VERSION ""

NS_ :

BS_:

BU_: ETH

BO_ 1274 USM_alertCleared: 8 Vector__XXX
 SG_ USM_alertClearedID : 0|8@1+ (1,0) [0|0] "" Vector__XXX

BO_ 1278 USM_logging10Hz: 8 Vector__XXX
 SG_ USM_frontSensorsHSDCurrent : 0|10@1+ (0.005865102639296188,0) [0|0] "" Vector__XXX
 SG_ USM_rearSensorsHSDCurrent : 10|10@1+ (0.005865102639296188,0) [0|0] "" Vector__XXX

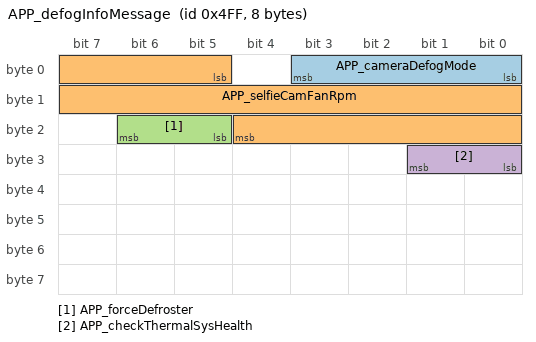
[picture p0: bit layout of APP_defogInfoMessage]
BO_ 1279 APP_defogInfoMessage: 8 Vector__XXX
 SG_ APP_cameraDefogMode : 0|4@1+ (1,0) [0|0] "" Vector__XXX
 SG_ APP_selfieCamFanRpm : 5|16@1+ (1,0) [0|0] "" Vector__XXX
 SG_ APP_forceDefroster : 21|2@1+ (1,0) [0|0] "" Vector__XXX
 SG_ APP_checkThermalSysHealth : 24|2@1+ (1,0) [0|0] "" Vector__XXX

BO_ 1282 RADC_alertMatrix0: 8 Vector__XXX
 SG_ RADC_a001_can1BusOff : 1|1@1+ (1,0) [0|0] "" Vector__XXX
 SG_ RADC_a002_ecuAdcError : 2|1@1+ (1,0) [0|0] "" Vector__XXX
 SG_ RADC_a003_ecuBistDisabled : 3|1@1+ (1,0) [0|0] "" Vector__XXX
 SG_ RADC_a004_ecuCrcHwError : 4|1@1+ (1,0) [0|0] "" Vector__XXX
 SG_ RADC_a005_ecuEcuMError : 5|1@1+ (1,0) [0|0] "" Vector__XXX
 SG_ RADC_a006_ecuFimError : 6|1@1+ (1,0) [0|0] "" Vector__XXX
 SG_ RADC_a007_ecuGptCheckError : 7|1@1+ (1,0) [0|0] "" Vector__XXX
 SG_ RADC_a008_ecuHwSwInterlock : 8|1@1+ (1,0) [0|0] "" Vector__XXX
 SG_ RADC_a009_plantModeActive : 9|1@1+ (1,0) [0|0] "" Vector__XXX
 SG_ RADC_a010_ecuIoHwAbError : 10|1@1+ (1,0) [0|0] "" Vector__XXX
 SG_ RADC_a011_ecuMcemError : 11|1@1+ (1,0) [0|0] "" Vector__XXX
 SG_ RADC_a012_ecuSpiError : 12|1@1+ (1,0) [0|0] "" Vector__XXX
 SG_ RADC_a013_ecuWdgError : 13|1@1+ (1,0) [0|0] "" Vector__XXX
 SG_ RADC_a014_fctSelfTestNotDone : 14|1@1+ (1,0) [0|0] "" Vector__XXX
 SG_ RADC_a015_fctSenInterference : 15|1@1+ (1,0) [0|0] "" Vector__XXX
 SG_ RADC_a016_adcOverVolt : 16|1@1+ (1,0) [0|0] "" Vector__XXX
 SG_ RADC_a017_adcUnderVolt : 17|1@1+ (1,0) [0|0] "" Vector__XXX
 SG_ RADC_a018_internalHardwareFault : 18|1@1+ (1,0) [0|0] "" Vector__XXX
 SG_ RADC_a019_internalSoftwareFault : 19|1@1+ (1,0) [0|0] "" Vector__XXX
 SG_ RADC_a020_overTemp : 20|1@1+ (1,0) [0|0] "" Vector__XXX
 SG_ RADC_a021_overTempCrit : 21|1@1+ (1,0) [0|0] "" Vector__XXX
 SG_ RADC_a022_tempImplausible : 22|1@1+ (1,0) [0|0] "" Vector__XXX
 SG_ RADC_a023_underTemp : 23|1@1+ (1,0) [0|0] "" Vector__XXX
 SG_ RADC_a024_underTempCrit : 24|1@1+ (1,0) [0|0] "" Vector__XXX
 SG_ RADC_a025_overVoltage : 25|1@1+ (1,0) [0|0] "" Vector__XXX
 SG_ RADC_a026_underVoltage : 26|1@1+ (1,0) [0|0] "" Vector__XXX
 SG_ RADC_a027_nvmFailure : 27|1@1+ (1,0) [0|0] "" Vector__XXX
 SG_ RADC_a028_rfChipError : 28|1@1+ (1,0) [0|0] "" Vector__XXX
 SG_ RADC_a029_rhcError : 29|1@1+ (1,0) [0|0] "" Vector__XXX
 SG_ RADC_a030_rspError : 30|1@1+ (1,0) [0|0] "" Vector__XXX
 SG_ RADC_a031_sensorMisaligned : 31|1@1+ (1,0) [0|0] "" Vector__XXX
 SG_ RADC_a032_sensorBlocked : 32|1@1+ (1,0) [0|0] "" Vector__XXX
 SG_ RADC_a033_sensorNeverAligned : 33|1@1+ (1,0) [0|0] "" Vector__XXX
 SG_ RADC_a034_vehDynamicsError : 34|1@1+ (1,0) [0|0] "" Vector__XXX
 SG_ RADC_a035_vinMIA : 35|1@1+ (1,0) [0|0] "" Vector__XXX
 SG_ RADC_a036_carConfigMIA : 36|1@1+ (1,0) [0|0] "" Vector__XXX
 SG_ RADC_a037_inertialSignalsMIA : 37|1@1+ (1,0) [0|0] "" Vector__XXX
 SG_ RADC_a038_steeringWheelAngleMIA : 38|1@1+ (1,0) [0|0] "" Vector__XXX
 SG_ RADC_a039_vehicleStateMIA : 39|1@1+ (1,0) [0|0] "" Vector__XXX
 SG_ RADC_a040_wheelSpeedsMIA : 40|1@1+ (1,0) [0|0] "" Vector__XXX
 SG_ RADC_a041_vinErr : 41|1@1+ (1,0) [0|0] "" Vector__XXX
 SG_ RADC_a042_carConfigErr : 42|1@1+ (1,0) [0|0] "" Vector__XXX
 SG_ RADC_a043_inertialSignalsErr : 43|1@1+ (1,0) [0|0] "" Vector__XXX
 SG_ RADC_a044_steeringWheelAngleErr : 44|1@1+ (1,0) [0|0] "" Vector__XXX
 SG_ RADC_a045_vehicleStateErr : 45|1@1+ (1,0) [0|0] "" Vector__XXX
 SG_ RADC_a046_wheelSpeedsErr : 46|1@1+ (1,0) [0|0] "" Vector__XXX
 SG_ RADC_a047_mismatchChassisType : 47|1@1+ (1,0) [0|0] "" Vector__XXX
 SG_ RADC_a048_mismatchAirSuspension : 48|1@1+ (1,0) [0|0] "" Vector__XXX
 SG_ RADC_a049_mismatchFourWheelDrive : 49|1@1+ (1,0) [0|0] "" Vector__XXX
 SG_ RADC_a050_mismatchCountry : 50|1@1+ (1,0) [0|0] "" Vector__XXX
 SG_ RADC_a051_mismatchEPASType : 51|1@1+ (1,0) [0|0] "" Vector__XXX
 SG_ RADC_a052_mismatcRadPos : 52|1@1+ (1,0) [0|0] "" Vector__XXX
 SG_ RADC_a053_emError : 53|1@1+ (1,0) [0|0] "" Vector__XXX
 SG_ RADC_a054_blockageInfo_Frame_1 : 54|1@1+ (1,0) [0|0] "" Vector__XXX
 SG_ RADC_a055_blockageInfo_Frame_2 : 55|1@1+ (1,0) [0|0] "" Vector__XXX

BO_ 1285 ESP_alertLog: 8 Vector__XXX
 SG_ ESP_alertID : 0|9@1+ (1,0) [0|0] "" Vector__XXX
 SG_ ESP_alertState : 15|1@1+ (1,0) [0|0] "" Vector__XXX

BO_ 1297 RCM_alertLog: 8 Vector__XXX
 SG_ RCM_alertID M : 0|10@1+ (1,0) [0|0] "" Vector__XXX
 SG_ RCM_alertState : 10|1@1+ (1,0) [0|0] "" Vector__XXX
 SG_ RCM_a000_eventArmStatus m0 : 11|1@1+ (1,0) [0|0] "" Vector__XXX
 SG_ RCM_a001_eventArmStatus m1 : 11|1@1+ (1,0) [0|0] "" Vector__XXX
 SG_ RCM_a002_eventArmStatus m2 : 11|1@1+ (1,0) [0|0] "" Vector__XXX
 SG_ RCM_a003_eventArmStatus m3 : 11|1@1+ (1,0) [0|0] "" Vector__XXX
 SG_ RCM_a004_eventArmStatus m4 : 11|1@1+ (1,0) [0|0] "" Vector__XXX
 SG_ RCM_a005_eventArmStatus m5 : 11|1@1+ (1,0) [0|0] "" Vector__XXX
 SG_ RCM_a006_eventArmStatus m6 : 11|1@1+ (1,0) [0|0] "" Vector__XXX
 SG_ RCM_a007_eventArmStatus m7 : 11|1@1+ (1,0) [0|0] "" Vector__XXX
 SG_ RCM_a008_eventArmStatus m8 : 11|1@1+ (1,0) [0|0] "" Vector__XXX
 SG_ RCM_a009_eventArmStatus m9 : 11|1@1+ (1,0) [0|0] "" Vector__XXX
 SG_ RCM_a010_eventArmStatus m10 : 11|1@1+ (1,0) [0|0] "" Vector__XXX
 SG_ RCM_a011_eventArmStatus m11 : 11|1@1+ (1,0) [0|0] "" Vector__XXX
 SG_ RCM_a012_eventArmStatus m12 : 11|1@1+ (1,0) [0|0] "" Vector__XXX
 SG_ RCM_a013_eventArmStatus m13 : 11|1@1+ (1,0) [0|0] "" Vector__XXX
 SG_ RCM_a014_eventArmStatus m14 : 11|1@1+ (1,0) [0|0] "" Vector__XXX
 SG_ RCM_a015_eventArmStatus m15 : 11|1@1+ (1,0) [0|0] "" Vector__XXX
 SG_ RCM_a016_eventArmStatus m16 : 11|1@1+ (1,0) [0|0] "" Vector__XXX
 SG_ RCM_a017_eventArmStatus m17 : 11|1@1+ (1,0) [0|0] "" Vector__XXX
 SG_ RCM_a018_eventArmStatus m18 : 11|1@1+ (1,0) [0|0] "" Vector__XXX
 SG_ RCM_a019_eventArmStatus m19 : 11|1@1+ (1,0) [0|0] "" Vector__XXX
 SG_ RCM_a020_eventArmStatus m20 : 11|1@1+ (1,0) [0|0] "" Vector__XXX
 SG_ RCM_a021_eventArmStatus m21 : 11|1@1+ (1,0) [0|0] "" Vector__XXX
 SG_ RCM_a022_eventArmStatus m22 : 11|1@1+ (1,0) [0|0] "" Vector__XXX
 SG_ RCM_a023_eventArmStatus m23 : 11|1@1+ (1,0) [0|0] "" Vector__XXX
 SG_ RCM_a024_eventArmStatus m24 : 11|1@1+ (1,0) [0|0] "" Vector__XXX
 SG_ RCM_a025_eventArmStatus m25 : 11|1@1+ (1,0) [0|0] "" Vector__XXX
 SG_ RCM_a026_eventArmStatus m26 : 11|1@1+ (1,0) [0|0] "" Vector__XXX
 SG_ RCM_a027_eventArmStatus m27 : 11|1@1+ (1,0) [0|0] "" Vector__XXX
 SG_ RCM_a028_eventArmStatus m28 : 11|1@1+ (1,0) [0|0] "" Vector__XXX
 SG_ RCM_a029_eventArmStatus m29 : 11|1@1+ (1,0) [0|0] "" Vector__XXX
 SG_ RCM_a030_eventArmStatus m30 : 11|1@1+ (1,0) [0|0] "" Vector__XXX
 SG_ RCM_a031_eventArmStatus m31 : 11|1@1+ (1,0) [0|0] "" Vector__XXX
 SG_ RCM_a032_eventArmStatus m32 : 11|1@1+ (1,0) [0|0] "" Vector__XXX
 SG_ RCM_a033_eventArmStatus m33 : 11|1@1+ (1,0) [0|0] "" Vector__XXX
 SG_ RCM_a034_eventArmStatus m34 : 11|1@1+ (1,0) [0|0] "" Vector__XXX
 SG_ RCM_a035_eventArmStatus m35 : 11|1@1+ (1,0) [0|0] "" Vector__XXX
 SG_ RCM_a036_eventArmStatus m36 : 11|1@1+ (1,0) [0|0] "" Vector__XXX
 SG_ RCM_a037_eventArmStatus m37 : 11|1@1+ (1,0) [0|0] "" Vector__XXX
 SG_ RCM_a038_eventArmStatus m38 : 11|1@1+ (1,0) [0|0] "" Vector__XXX
 SG_ RCM_a039_eventArmStatus m39 : 11|1@1+ (1,0) [0|0] "" Vector__XXX
 SG_ RCM_a040_eventArmStatus m40 : 11|1@1+ (1,0) [0|0] "" Vector__XXX
 SG_ RCM_a041_eventArmStatus m41 : 11|1@1+ (1,0) [0|0] "" Vector__XXX
 SG_ RCM_a042_eventArmStatus m42 : 11|1@1+ (1,0) [0|0] "" Vector__XXX
 SG_ RCM_a043_eventArmStatus m43 : 11|1@1+ (1,0) [0|0] "" Vector__XXX
 SG_ RCM_a044_eventArmStatus m44 : 11|1@1+ (1,0) [0|0] "" Vector__XXX
 SG_ RCM_a045_eventArmStatus m45 : 11|1@1+ (1,0) [0|0] "" Vector__XXX
 SG_ RCM_a046_eventArmStatus m46 : 11|1@1+ (1,0) [0|0] "" Vector__XXX
 SG_ RCM_a047_eventArmStatus m47 : 11|1@1+ (1,0) [0|0] "" Vector__XXX
 SG_ RCM_a048_eventArmStatus m48 : 11|1@1+ (1,0) [0|0] "" Vector__XXX
 SG_ RCM_a049_eventArmStatus m49 : 11|1@1+ (1,0) [0|0] "" Vector__XXX
 SG_ RCM_a050_eventArmStatus m50 : 11|1@1+ (1,0) [0|0] "" Vector__XXX
 SG_ RCM_a051_eventArmStatus m51 : 11|1@1+ (1,0) [0|0] "" Vector__XXX
 SG_ RCM_a052_eventArmStatus m52 : 11|1@1+ (1,0) [0|0] "" Vector__XXX
 SG_ RCM_a053_eventArmStatus m53 : 11|1@1+ (1,0) [0|0] "" Vector__XXX
 SG_ RCM_a054_eventArmStatus m54 : 11|1@1+ (1,0) [0|0] "" Vector__XXX
 SG_ RCM_a055_eventArmStatus m55 : 11|1@1+ (1,0) [0|0] "" Vector__XXX
 SG_ RCM_a056_eventArmStatus m56 : 11|1@1+ (1,0) [0|0] "" Vector__XXX
 SG_ RCM_a057_eventArmStatus m57 : 11|1@1+ (1,0) [0|0] "" Vector__XXX
 SG_ RCM_a058_eventArmStatus m58 : 11|1@1+ (1,0) [0|0] "" Vector__XXX
 SG_ RCM_a059_eventArmStatus m59 : 11|1@1+ (1,0) [0|0] "" Vector__XXX
 SG_ RCM_a060_eventArmStatus m60 : 11|1@1+ (1,0) [0|0] "" Vector__XXX
 SG_ RCM_a061_eventArmStatus m61 : 11|1@1+ (1,0) [0|0] "" Vector__XXX
 SG_ RCM_a062_eventArmStatus m62 : 11|1@1+ (1,0) [0|0] "" Vector__XXX
 SG_ RCM_a063_eventArmStatus m63 : 11|1@1+ (1,0) [0|0] "" Vector__XXX
 SG_ RCM_a064_eventArmStatus m64 : 11|1@1+ (1,0) [0|0] "" Vector__XXX
 SG_ RCM_a065_eventArmStatus m65 : 11|1@1+ (1,0) [0|0] "" Vector__XXX
 SG_ RCM_a066_eventArmStatus m66 : 11|1@1+ (1,0) [0|0] "" Vector__XXX
 SG_ RCM_a067_eventArmStatus m67 : 11|1@1+ (1,0) [0|0] "" Vector__XXX
 SG_ RCM_a068_eventArmStatus m68 : 11|1@1+ (1,0) [0|0] "" Vector__XXX
 SG_ RCM_a069_eventArmStatus m69 : 11|1@1+ (1,0) [0|0] "" Vector__XXX
 SG_ RCM_a070_eventArmStatus m70 : 11|1@1+ (1,0) [0|0] "" Vector__XXX
 SG_ RCM_a071_eventArmStatus m71 : 11|1@1+ (1,0) [0|0] "" Vector__XXX
 SG_ RCM_a072_eventArmStatus m72 : 11|1@1+ (1,0) [0|0] "" Vector__XXX
 SG_ RCM_a073_eventArmStatus m73 : 11|1@1+ (1,0) [0|0] "" Vector__XXX
 SG_ RCM_a074_eventArmStatus m74 : 11|1@1+ (1,0) [0|0] "" Vector__XXX
 SG_ RCM_a075_eventArmStatus m75 : 11|1@1+ (1,0) [0|0] "" Vector__XXX
 SG_ RCM_a076_eventArmStatus m76 : 11|1@1+ (1,0) [0|0] "" Vector__XXX
 SG_ RCM_a077_eventArmStatus m77 : 11|1@1+ (1,0) [0|0] "" Vector__XXX
 SG_ RCM_a078_eventArmStatus m78 : 11|1@1+ (1,0) [0|0] "" Vector__XXX
 SG_ RCM_a079_eventArmStatus m79 : 11|1@1+ (1,0) [0|0] "" Vector__XXX
 SG_ RCM_a080_eventArmStatus m80 : 11|1@1+ (1,0) [0|0] "" Vector__XXX
 SG_ RCM_a081_eventArmStatus m81 : 11|1@1+ (1,0) [0|0] "" Vector__XXX
 SG_ RCM_a082_eventArmStatus m82 : 11|1@1+ (1,0) [0|0] "" Vector__XXX
 SG_ RCM_a083_eventArmStatus m83 : 11|1@1+ (1,0) [0|0] "" Vector__XXX
 SG_ RCM_a084_eventArmStatus m84 : 11|1@1+ (1,0) [0|0] "" Vector__XXX
 SG_ RCM_a085_eventArmStatus m85 : 11|1@1+ (1,0) [0|0] "" Vector__XXX
 SG_ RCM_a086_eventArmStatus m86 : 11|1@1+ (1,0) [0|0] "" Vector__XXX
 SG_ RCM_a087_eventArmStatus m87 : 11|1@1+ (1,0) [0|0] "" Vector__XXX
 SG_ RCM_a088_eventArmStatus m88 : 11|1@1+ (1,0) [0|0] "" Vector__XXX
 SG_ RCM_a089_eventArmStatus m89 : 11|1@1+ (1,0) [0|0] "" Vector__XXX
 SG_ RCM_a090_eventArmStatus m90 : 11|1@1+ (1,0) [0|0] "" Vector__XXX
 SG_ RCM_a091_eventArmStatus m91 : 11|1@1+ (1,0) [0|0] "" Vector__XXX
 SG_ RCM_a092_eventArmStatus m92 : 11|1@1+ (1,0) [0|0] "" Vector__XXX
 SG_ RCM_a093_eventArmStatus m93 : 11|1@1+ (1,0) [0|0] "" Vector__XXX
 SG_ RCM_a094_eventArmStatus m94 : 11|1@1+ (1,0) [0|0] "" Vector__XXX
 SG_ RCM_a095_eventArmStatus m95 : 11|1@1+ (1,0) [0|0] "" Vector__XXX
 SG_ RCM_a096_eventArmStatus m96 : 11|1@1+ (1,0) [0|0] "" Vector__XXX
 SG_ RCM_a097_eventArmStatus m97 : 11|1@1+ (1,0) [0|0] "" Vector__XXX
 SG_ RCM_a098_eventArmStatus m98 : 11|1@1+ (1,0) [0|0] "" Vector__XXX
 SG_ RCM_a099_eventArmStatus m99 : 11|1@1+ (1,0) [0|0] "" Vector__XXX
 SG_ RCM_a100_eventArmStatus m100 : 11|1@1+ (1,0) [0|0] "" Vector__XXX
 SG_ RCM_a101_eventArmStatus m101 : 11|1@1+ (1,0) [0|0] "" Vector__XXX
 SG_ RCM_a102_eventArmStatus m102 : 11|1@1+ (1,0) [0|0] "" Vector__XXX
 SG_ RCM_a103_eventArmStatus m103 : 11|1@1+ (1,0) [0|0] "" Vector__XXX
 SG_ RCM_a104_eventArmStatus m104 : 11|1@1+ (1,0) [0|0] "" Vector__XXX
 SG_ RCM_a105_eventArmStatus m105 : 11|1@1+ (1,0) [0|0] "" Vector__XXX
 SG_ RCM_a106_eventArmStatus m106 : 11|1@1+ (1,0) [0|0] "" Vector__XXX
 SG_ RCM_a107_eventArmStatus m107 : 11|1@1+ (1,0) [0|0] "" Vector__XXX
 SG_ RCM_a108_eventArmStatus m108 : 11|1@1+ (1,0) [0|0] "" Vector__XXX
 SG_ RCM_a109_eventArmStatus m109 : 11|1@1+ (1,0) [0|0] "" Vector__XXX
 SG_ RCM_a110_eventArmStatus m110 : 11|1@1+ (1,0) [0|0] "" Vector__XXX
 SG_ RCM_a111_eventArmStatus m111 : 11|1@1+ (1,0) [0|0] "" Vector__XXX
 SG_ RCM_a112_eventArmStatus m112 : 11|1@1+ (1,0) [0|0] "" Vector__XXX
 SG_ RCM_a113_eventArmStatus m113 : 11|1@1+ (1,0) [0|0] "" Vector__XXX
 SG_ RCM_a114_eventArmStatus m114 : 11|1@1+ (1,0) [0|0] "" Vector__XXX
 SG_ RCM_a115_eventArmStatus m115 : 11|1@1+ (1,0) [0|0] "" Vector__XXX
 SG_ RCM_a116_eventArmStatus m116 : 11|1@1+ (1,0) [0|0] "" Vector__XXX
 SG_ RCM_a117_eventArmStatus m117 : 11|1@1+ (1,0) [0|0] "" Vector__XXX
 SG_ RCM_a118_eventArmStatus m118 : 11|1@1+ (1,0) [0|0] "" Vector__XXX
 SG_ RCM_a000_eventFactoryMode m0 : 12|1@1+ (1,0) [0|0] "" Vector__XXX
 SG_ RCM_a001_eventFactoryMode m1 : 12|1@1+ (1,0) [0|0] "" Vector__XXX
 SG_ RCM_a002_eventFactoryMode m2 : 12|1@1+ (1,0) [0|0] "" Vector__XXX
 SG_ RCM_a003_eventFactoryMode m3 : 12|1@1+ (1,0) [0|0] "" Vector__XXX
 SG_ RCM_a004_eventFactoryMode m4 : 12|1@1+ (1,0) [0|0] "" Vector__XXX
 SG_ RCM_a005_eventFactoryMode m5 : 12|1@1+ (1,0) [0|0] "" Vector__XXX
 SG_ RCM_a006_eventFactoryMode m6 : 12|1@1+ (1,0) [0|0] "" Vector__XXX
 SG_ RCM_a007_eventFactoryMode m7 : 12|1@1+ (1,0) [0|0] "" Vector__XXX
 SG_ RCM_a008_eventFactoryMode m8 : 12|1@1+ (1,0) [0|0] "" Vector__XXX
 SG_ RCM_a009_eventFactoryMode m9 : 12|1@1+ (1,0) [0|0] "" Vector__XXX
 SG_ RCM_a010_eventFactoryMode m10 : 12|1@1+ (1,0) [0|0] "" Vector__XXX
 SG_ RCM_a011_eventFactoryMode m11 : 12|1@1+ (1,0) [0|0] "" Vector__XXX
 SG_ RCM_a012_eventFactoryMode m12 : 12|1@1+ (1,0) [0|0] "" Vector__XXX
 SG_ RCM_a013_eventFactoryMode m13 : 12|1@1+ (1,0) [0|0] "" Vector__XXX
 SG_ RCM_a014_eventFactoryMode m14 : 12|1@1+ (1,0) [0|0] "" Vector__XXX
 SG_ RCM_a015_eventFactoryMode m15 : 12|1@1+ (1,0) [0|0] "" Vector__XXX
 SG_ RCM_a016_eventFactoryMode m16 : 12|1@1+ (1,0) [0|0] "" Vector__XXX
 SG_ RCM_a017_eventFactoryMode m17 : 12|1@1+ (1,0) [0|0] "" Vector__XXX
 SG_ RCM_a018_eventFactoryMode m18 : 12|1@1+ (1,0) [0|0] "" Vector__XXX
 SG_ RCM_a019_eventFactoryMode m19 : 12|1@1+ (1,0) [0|0] "" Vector__XXX
 SG_ RCM_a020_eventFactoryMode m20 : 12|1@1+ (1,0) [0|0] "" Vector__XXX
 SG_ RCM_a021_eventFactoryMode m21 : 12|1@1+ (1,0) [0|0] "" Vector__XXX
 SG_ RCM_a022_eventFactoryMode m22 : 12|1@1+ (1,0) [0|0] "" Vector__XXX
 SG_ RCM_a023_eventFactoryMode m23 : 12|1@1+ (1,0) [0|0] "" Vector__XXX
 SG_ RCM_a024_eventFactoryMode m24 : 12|1@1+ (1,0) [0|0] "" Vector__XXX
 SG_ RCM_a025_eventFactoryMode m25 : 12|1@1+ (1,0) [0|0] "" Vector__XXX
 SG_ RCM_a026_eventFactoryMode m26 : 12|1@1+ (1,0) [0|0] "" Vector__XXX
 SG_ RCM_a027_eventFactoryMode m27 : 12|1@1+ (1,0) [0|0] "" Vector__XXX
 SG_ RCM_a028_eventFactoryMode m28 : 12|1@1+ (1,0) [0|0] "" Vector__XXX
 SG_ RCM_a029_eventFactoryMode m29 : 12|1@1+ (1,0) [0|0] "" Vector__XXX
 SG_ RCM_a030_eventFactoryMode m30 : 12|1@1+ (1,0) [0|0] "" Vector__XXX
 SG_ RCM_a031_eventFactoryMode m31 : 12|1@1+ (1,0) [0|0] "" Vector__XXX
 SG_ RCM_a032_eventFactoryMode m32 : 12|1@1+ (1,0) [0|0] "" Vector__XXX
 SG_ RCM_a033_eventFactoryMode m33 : 12|1@1+ (1,0) [0|0] "" Vector__XXX
 SG_ RCM_a034_eventFactoryMode m34 : 12|1@1+ (1,0) [0|0] "" Vector__XXX
 SG_ RCM_a035_eventFactoryMode m35 : 12|1@1+ (1,0) [0|0] "" Vector__XXX
 SG_ RCM_a036_eventFactoryMode m36 : 12|1@1+ (1,0) [0|0] "" Vector__XXX
 SG_ RCM_a037_eventFactoryMode m37 : 12|1@1+ (1,0) [0|0] "" Vector__XXX
 SG_ RCM_a038_eventFactoryMode m38 : 12|1@1+ (1,0) [0|0] "" Vector__XXX
 SG_ RCM_a039_eventFactoryMode m39 : 12|1@1+ (1,0) [0|0] "" Vector__XXX
 SG_ RCM_a040_eventFactoryMode m40 : 12|1@1+ (1,0) [0|0] "" Vector__XXX
 SG_ RCM_a041_eventFactoryMode m41 : 12|1@1+ (1,0) [0|0] "" Vector__XXX
 SG_ RCM_a042_eventFactoryMode m42 : 12|1@1+ (1,0) [0|0] "" Vector__XXX
 SG_ RCM_a043_eventFactoryMode m43 : 12|1@1+ (1,0) [0|0] "" Vector__XXX
 SG_ RCM_a044_eventFactoryMode m44 : 12|1@1+ (1,0) [0|0] "" Vector__XXX
 SG_ RCM_a045_eventFactoryMode m45 : 12|1@1+ (1,0) [0|0] "" Vector__XXX
 SG_ RCM_a046_eventFactoryMode m46 : 12|1@1+ (1,0) [0|0] "" Vector__XXX
 SG_ RCM_a047_eventFactoryMode m47 : 12|1@1+ (1,0) [0|0] "" Vector__XXX
 SG_ RCM_a048_eventFactoryMode m48 : 12|1@1+ (1,0) [0|0] "" Vector__XXX
 SG_ RCM_a049_eventFactoryMode m49 : 12|1@1+ (1,0) [0|0] "" Vector__XXX
 SG_ RCM_a050_eventFactoryMode m50 : 12|1@1+ (1,0) [0|0] "" Vector__XXX
 SG_ RCM_a051_eventFactoryMode m51 : 12|1@1+ (1,0) [0|0] "" Vector__XXX
 SG_ RCM_a052_eventFactoryMode m52 : 12|1@1+ (1,0) [0|0] "" Vector__XXX
 SG_ RCM_a053_eventFactoryMode m53 : 12|1@1+ (1,0) [0|0] "" Vector__XXX
 SG_ RCM_a054_eventFactoryMode m54 : 12|1@1+ (1,0) [0|0] "" Vector__XXX
 SG_ RCM_a055_eventFactoryMode m55 : 12|1@1+ (1,0) [0|0] "" Vector__XXX
 SG_ RCM_a056_eventFactoryMode m56 : 12|1@1+ (1,0) [0|0] "" Vector__XXX
 SG_ RCM_a057_eventFactoryMode m57 : 12|1@1+ (1,0) [0|0] "" Vector__XXX
 SG_ RCM_a058_eventFactoryMode m58 : 12|1@1+ (1,0) [0|0] "" Vector__XXX
 SG_ RCM_a059_eventFactoryMode m59 : 12|1@1+ (1,0) [0|0] "" Vector__XXX
 SG_ RCM_a060_eventFactoryMode m60 : 12|1@1+ (1,0) [0|0] "" Vector__XXX
 SG_ RCM_a061_eventFactoryMode m61 : 12|1@1+ (1,0) [0|0] "" Vector__XXX
 SG_ RCM_a062_eventFactoryMode m62 : 12|1@1+ (1,0) [0|0] "" Vector__XXX
 SG_ RCM_a063_eventFactoryMode m63 : 12|1@1+ (1,0) [0|0] "" Vector__XXX
 SG_ RCM_a064_eventFactoryMode m64 : 12|1@1+ (1,0) [0|0] "" Vector__XXX
 SG_ RCM_a065_eventFactoryMode m65 : 12|1@1+ (1,0) [0|0] "" Vector__XXX
 SG_ RCM_a066_eventFactoryMode m66 : 12|1@1+ (1,0) [0|0] "" Vector__XXX
 SG_ RCM_a067_eventFactoryMode m67 : 12|1@1+ (1,0) [0|0] "" Vector__XXX
 SG_ RCM_a068_eventFactoryMode m68 : 12|1@1+ (1,0) [0|0] "" Vector__XXX
 SG_ RCM_a069_eventFactoryMode m69 : 12|1@1+ (1,0) [0|0] "" Vector__XXX
 SG_ RCM_a070_eventFactoryMode m70 : 12|1@1+ (1,0) [0|0] "" Vector__XXX
 SG_ RCM_a071_eventFactoryMode m71 : 12|1@1+ (1,0) [0|0] "" Vector__XXX
 SG_ RCM_a072_eventFactoryMode m72 : 12|1@1+ (1,0) [0|0] "" Vector__XXX
 SG_ RCM_a073_eventFactoryMode m73 : 12|1@1+ (1,0) [0|0] "" Vector__XXX
 SG_ RCM_a074_eventFactoryMode m74 : 12|1@1+ (1,0) [0|0] "" Vector__XXX
 SG_ RCM_a075_eventFactoryMode m75 : 12|1@1+ (1,0) [0|0] "" Vector__XXX
 SG_ RCM_a076_eventFactoryMode m76 : 12|1@1+ (1,0) [0|0] "" Vector__XXX
 SG_ RCM_a077_eventFactoryMode m77 : 12|1@1+ (1,0) [0|0] "" Vector__XXX
 SG_ RCM_a078_eventFactoryMode m78 : 12|1@1+ (1,0) [0|0] "" Vector__XXX
 SG_ RCM_a079_eventFactoryMode m79 : 12|1@1+ (1,0) [0|0] "" Vector__XXX
 SG_ RCM_a080_eventFactoryMode m80 : 12|1@1+ (1,0) [0|0] "" Vector__XXX
 SG_ RCM_a081_eventFactoryMode m81 : 12|1@1+ (1,0) [0|0] "" Vector__XXX
 SG_ RCM_a082_eventFactoryMode m82 : 12|1@1+ (1,0) [0|0] "" Vector__XXX
 SG_ RCM_a083_eventFactoryMode m83 : 12|1@1+ (1,0) [0|0] "" Vector__XXX
 SG_ RCM_a084_eventFactoryMode m84 : 12|1@1+ (1,0) [0|0] "" Vector__XXX
 SG_ RCM_a085_eventFactoryMode m85 : 12|1@1+ (1,0) [0|0] "" Vector__XXX
 SG_ RCM_a086_eventFactoryMode m86 : 12|1@1+ (1,0) [0|0] "" Vector__XXX
 SG_ RCM_a087_eventFactoryMode m87 : 12|1@1+ (1,0) [0|0] "" Vector__XXX
 SG_ RCM_a088_eventFactoryMode m88 : 12|1@1+ (1,0) [0|0] "" Vector__XXX
 SG_ RCM_a089_eventFactoryMode m89 : 12|1@1+ (1,0) [0|0] "" Vector__XXX
 SG_ RCM_a090_eventFactoryMode m90 : 12|1@1+ (1,0) [0|0] "" Vector__XXX
 SG_ RCM_a091_eventFactoryMode m91 : 12|1@1+ (1,0) [0|0] "" Vector__XXX
 SG_ RCM_a092_eventFactoryMode m92 : 12|1@1+ (1,0) [0|0] "" Vector__XXX
 SG_ RCM_a093_eventFactoryMode m93 : 12|1@1+ (1,0) [0|0] "" Vector__XXX
 SG_ RCM_a094_eventFactoryMode m94 : 12|1@1+ (1,0) [0|0] "" Vector__XXX
 SG_ RCM_a095_eventFactoryMode m95 : 12|1@1+ (1,0) [0|0] "" Vector__XXX
 SG_ RCM_a096_eventFactoryMode m96 : 12|1@1+ (1,0) [0|0] "" Vector__XXX
 SG_ RCM_a097_eventFactoryMode m97 : 12|1@1+ (1,0) [0|0] "" Vector__XXX
 SG_ RCM_a098_eventFactoryMode m98 : 12|1@1+ (1,0) [0|0] "" Vector__XXX
 SG_ RCM_a099_eventFactoryMode m99 : 12|1@1+ (1,0) [0|0] "" Vector__XXX
 SG_ RCM_a100_eventFactoryMode m100 : 12|1@1+ (1,0) [0|0] "" Vector__XXX
 SG_ RCM_a101_eventFactoryMode m101 : 12|1@1+ (1,0) [0|0] "" Vector__XXX
 SG_ RCM_a102_eventFactoryMode m102 : 12|1@1+ (1,0) [0|0] "" Vector__XXX
 SG_ RCM_a103_eventFactoryMode m103 : 12|1@1+ (1,0) [0|0] "" Vector__XXX
 SG_ RCM_a104_eventFactoryMode m104 : 12|1@1+ (1,0) [0|0] "" Vector__XXX
 SG_ RCM_a105_eventFactoryMode m105 : 12|1@1+ (1,0) [0|0] "" Vector__XXX
 SG_ RCM_a106_eventFactoryMode m106 : 12|1@1+ (1,0) [0|0] "" Vector__XXX
 SG_ RCM_a107_eventFactoryMode m107 : 12|1@1+ (1,0) [0|0] "" Vector__XXX
 SG_ RCM_a108_eventFactoryMode m108 : 12|1@1+ (1,0) [0|0] "" Vector__XXX
 SG_ RCM_a109_eventFactoryMode m109 : 12|1@1+ (1,0) [0|0] "" Vector__XXX
 SG_ RCM_a110_eventFactoryMode m110 : 12|1@1+ (1,0) [0|0] "" Vector__XXX
 SG_ RCM_a111_eventFactoryMode m111 : 12|1@1+ (1,0) [0|0] "" Vector__XXX
 SG_ RCM_a112_eventFactoryMode m112 : 12|1@1+ (1,0) [0|0] "" Vector__XXX
 SG_ RCM_a113_eventFactoryMode m113 : 12|1@1+ (1,0) [0|0] "" Vector__XXX
 SG_ RCM_a114_eventFactoryMode m114 : 12|1@1+ (1,0) [0|0] "" Vector__XXX
 SG_ RCM_a115_eventFactoryMode m115 : 12|1@1+ (1,0) [0|0] "" Vector__XXX
 SG_ RCM_a116_eventFactoryMode m116 : 12|1@1+ (1,0) [0|0] "" Vector__XXX
 SG_ RCM_a117_eventFactoryMode m117 : 12|1@1+ (1,0) [0|0] "" Vector__XXX
 SG_ RCM_a118_eventFactoryMode m118 : 12|1@1+ (1,0) [0|0] "" Vector__XXX
 SG_ RCM_a000_eventDiagEnabled m0 : 13|1@1+ (1,0) [0|0] "" Vector__XXX
 SG_ RCM_a001_eventDiagEnabled m1 : 13|1@1+ (1,0) [0|0] "" Vector__XXX
 SG_ RCM_a002_eventDiagEnabled m2 : 13|1@1+ (1,0) [0|0] "" Vector__XXX
 SG_ RCM_a003_eventDiagEnabled m3 : 13|1@1+ (1,0) [0|0] "" Vector__XXX
 SG_ RCM_a004_eventDiagEnabled m4 : 13|1@1+ (1,0) [0|0] "" Vector__XXX
 SG_ RCM_a005_eventDiagEnabled m5 : 13|1@1+ (1,0) [0|0] "" Vector__XXX
 SG_ RCM_a006_eventDiagEnabled m6 : 13|1@1+ (1,0) [0|0] "" Vector__XXX
 SG_ RCM_a007_eventDiagEnabled m7 : 13|1@1+ (1,0) [0|0] "" Vector__XXX
 SG_ RCM_a008_eventDiagEnabled m8 : 13|1@1+ (1,0) [0|0] "" Vector__XXX
 SG_ RCM_a009_eventDiagEnabled m9 : 13|1@1+ (1,0) [0|0] "" Vector__XXX
 SG_ RCM_a010_eventDiagEnabled m10 : 13|1@1+ (1,0) [0|0] "" Vector__XXX
 SG_ RCM_a011_eventDiagEnabled m11 : 13|1@1+ (1,0) [0|0] "" Vector__XXX
 SG_ RCM_a012_eventDiagEnabled m12 : 13|1@1+ (1,0) [0|0] "" Vector__XXX
 SG_ RCM_a013_eventDiagEnabled m13 : 13|1@1+ (1,0) [0|0] "" Vector__XXX
 SG_ RCM_a014_eventDiagEnabled m14 : 13|1@1+ (1,0) [0|0] "" Vector__XXX
 SG_ RCM_a015_eventDiagEnabled m15 : 13|1@1+ (1,0) [0|0] "" Vector__XXX
 SG_ RCM_a016_eventDiagEnabled m16 : 13|1@1+ (1,0) [0|0] "" Vector__XXX
 SG_ RCM_a017_eventDiagEnabled m17 : 13|1@1+ (1,0) [0|0] "" Vector__XXX
 SG_ RCM_a018_eventDiagEnabled m18 : 13|1@1+ (1,0) [0|0] "" Vector__XXX
 SG_ RCM_a019_eventDiagEnabled m19 : 13|1@1+ (1,0) [0|0] "" Vector__XXX
 SG_ RCM_a020_eventDiagEnabled m20 : 13|1@1+ (1,0) [0|0] "" Vector__XXX
 SG_ RCM_a021_eventDiagEnabled m21 : 13|1@1+ (1,0) [0|0] "" Vector__XXX
 SG_ RCM_a022_eventDiagEnabled m22 : 13|1@1+ (1,0) [0|0] "" Vector__XXX
 SG_ RCM_a023_eventDiagEnabled m23 : 13|1@1+ (1,0) [0|0] "" Vector__XXX
 SG_ RCM_a024_eventDiagEnabled m24 : 13|1@1+ (1,0) [0|0] "" Vector__XXX
 SG_ RCM_a025_eventDiagEnabled m25 : 13|1@1+ (1,0) [0|0] "" Vector__XXX
 SG_ RCM_a026_eventDiagEnabled m26 : 13|1@1+ (1,0) [0|0] "" Vector__XXX
 SG_ RCM_a027_eventDiagEnabled m27 : 13|1@1+ (1,0) [0|0] "" Vector__XXX
 SG_ RCM_a028_eventDiagEnabled m28 : 13|1@1+ (1,0) [0|0] "" Vector__XXX
 SG_ RCM_a029_eventDiagEnabled m29 : 13|1@1+ (1,0) [0|0] "" Vector__XXX
 SG_ RCM_a030_eventDiagEnabled m30 : 13|1@1+ (1,0) [0|0] "" Vector__XXX
 SG_ RCM_a031_eventDiagEnabled m31 : 13|1@1+ (1,0) [0|0] "" Vector__XXX
 SG_ RCM_a032_eventDiagEnabled m32 : 13|1@1+ (1,0) [0|0] "" Vector__XXX
 SG_ RCM_a033_eventDiagEnabled m33 : 13|1@1+ (1,0) [0|0] "" Vector__XXX
 SG_ RCM_a034_eventDiagEnabled m34 : 13|1@1+ (1,0) [0|0] "" Vector__XXX
 SG_ RCM_a035_eventDiagEnabled m35 : 13|1@1+ (1,0) [0|0] "" Vector__XXX
 SG_ RCM_a036_eventDiagEnabled m36 : 13|1@1+ (1,0) [0|0] "" Vector__XXX
 SG_ RCM_a037_eventDiagEnabled m37 : 13|1@1+ (1,0) [0|0] "" Vector__XXX
 SG_ RCM_a038_eventDiagEnabled m38 : 13|1@1+ (1,0) [0|0] "" Vector__XXX
 SG_ RCM_a039_eventDiagEnabled m39 : 13|1@1+ (1,0) [0|0] "" Vector__XXX
 SG_ RCM_a040_eventDiagEnabled m40 : 13|1@1+ (1,0) [0|0] "" Vector__XXX
 SG_ RCM_a041_eventDiagEnabled m41 : 13|1@1+ (1,0) [0|0] "" Vector__XXX
 SG_ RCM_a042_eventDiagEnabled m42 : 13|1@1+ (1,0) [0|0] "" Vector__XXX
 SG_ RCM_a043_eventDiagEnabled m43 : 13|1@1+ (1,0) [0|0] "" Vector__XXX
 SG_ RCM_a044_eventDiagEnabled m44 : 13|1@1+ (1,0) [0|0] "" Vector__XXX
 SG_ RCM_a045_eventDiagEnabled m45 : 13|1@1+ (1,0) [0|0] "" Vector__XXX
 SG_ RCM_a046_eventDiagEnabled m46 : 13|1@1+ (1,0) [0|0] "" Vector__XXX
 SG_ RCM_a047_eventDiagEnabled m47 : 13|1@1+ (1,0) [0|0] "" Vector__XXX
 SG_ RCM_a048_eventDiagEnabled m48 : 13|1@1+ (1,0) [0|0] "" Vector__XXX
 SG_ RCM_a049_eventDiagEnabled m49 : 13|1@1+ (1,0) [0|0] "" Vector__XXX
 SG_ RCM_a050_eventDiagEnabled m50 : 13|1@1+ (1,0) [0|0] "" Vector__XXX
 SG_ RCM_a051_eventDiagEnabled m51 : 13|1@1+ (1,0) [0|0] "" Vector__XXX
 SG_ RCM_a052_eventDiagEnabled m52 : 13|1@1+ (1,0) [0|0] "" Vector__XXX
 SG_ RCM_a053_eventDiagEnabled m53 : 13|1@1+ (1,0) [0|0] "" Vector__XXX
 SG_ RCM_a054_eventDiagEnabled m54 : 13|1@1+ (1,0) [0|0] "" Vector__XXX
 SG_ RCM_a055_eventDiagEnabled m55 : 13|1@1+ (1,0) [0|0] "" Vector__XXX
 SG_ RCM_a056_eventDiagEnabled m56 : 13|1@1+ (1,0) [0|0] "" Vector__XXX
 SG_ RCM_a057_eventDiagEnabled m57 : 13|1@1+ (1,0) [0|0] "" Vector__XXX
 SG_ RCM_a058_eventDiagEnabled m58 : 13|1@1+ (1,0) [0|0] "" Vector__XXX
 SG_ RCM_a059_eventDiagEnabled m59 : 13|1@1+ (1,0) [0|0] "" Vector__XXX
 SG_ RCM_a060_eventDiagEnabled m60 : 13|1@1+ (1,0) [0|0] "" Vector__XXX
 SG_ RCM_a061_eventDiagEnabled m61 : 13|1@1+ (1,0) [0|0] "" Vector__XXX
 SG_ RCM_a062_eventDiagEnabled m62 : 13|1@1+ (1,0) [0|0] "" Vector__XXX
 SG_ RCM_a063_eventDiagEnabled m63 : 13|1@1+ (1,0) [0|0] "" Vector__XXX
 SG_ RCM_a064_eventDiagEnabled m64 : 13|1@1+ (1,0) [0|0] "" Vector__XXX
 SG_ RCM_a065_eventDiagEnabled m65 : 13|1@1+ (1,0) [0|0] "" Vector__XXX
 SG_ RCM_a066_eventDiagEnabled m66 : 13|1@1+ (1,0) [0|0] "" Vector__XXX
 SG_ RCM_a067_eventDiagEnabled m67 : 13|1@1+ (1,0) [0|0] "" Vector__XXX
 SG_ RCM_a068_eventDiagEnabled m68 : 13|1@1+ (1,0) [0|0] "" Vector__XXX
 SG_ RCM_a069_eventDiagEnabled m69 : 13|1@1+ (1,0) [0|0] "" Vector__XXX
 SG_ RCM_a070_eventDiagEnabled m70 : 13|1@1+ (1,0) [0|0] "" Vector__XXX
 SG_ RCM_a071_eventDiagEnabled m71 : 13|1@1+ (1,0) [0|0] "" Vector__XXX
 SG_ RCM_a072_eventDiagEnabled m72 : 13|1@1+ (1,0) [0|0] "" Vector__XXX
 SG_ RCM_a073_eventDiagEnabled m73 : 13|1@1+ (1,0) [0|0] "" Vector__XXX
 SG_ RCM_a074_eventDiagEnabled m74 : 13|1@1+ (1,0) [0|0] "" Vector__XXX
 SG_ RCM_a075_eventDiagEnabled m75 : 13|1@1+ (1,0) [0|0] "" Vector__XXX
 SG_ RCM_a076_eventDiagEnabled m76 : 13|1@1+ (1,0) [0|0] "" Vector__XXX
 SG_ RCM_a077_eventDiagEnabled m77 : 13|1@1+ (1,0) [0|0] "" Vector__XXX
 SG_ RCM_a078_eventDiagEnabled m78 : 13|1@1+ (1,0) [0|0] "" Vector__XXX
 SG_ RCM_a079_eventDiagEnabled m79 : 13|1@1+ (1,0) [0|0] "" Vector__XXX
 SG_ RCM_a080_eventDiagEnabled m80 : 13|1@1+ (1,0) [0|0] "" Vector__XXX
 SG_ RCM_a081_eventDiagEnabled m81 : 13|1@1+ (1,0) [0|0] "" Vector__XXX
 SG_ RCM_a082_eventDiagEnabled m82 : 13|1@1+ (1,0) [0|0] "" Vector__XXX
 SG_ RCM_a083_eventDiagEnabled m83 : 13|1@1+ (1,0) [0|0] "" Vector__XXX
 SG_ RCM_a084_eventDiagEnabled m84 : 13|1@1+ (1,0) [0|0] "" Vector__XXX
 SG_ RCM_a085_eventDiagEnabled m85 : 13|1@1+ (1,0) [0|0] "" Vector__XXX
 SG_ RCM_a086_eventDiagEnabled m86 : 13|1@1+ (1,0) [0|0] "" Vector__XXX
 SG_ RCM_a087_eventDiagEnabled m87 : 13|1@1+ (1,0) [0|0] "" Vector__XXX
 SG_ RCM_a088_eventDiagEnabled m88 : 13|1@1+ (1,0) [0|0] "" Vector__XXX
 SG_ RCM_a089_eventDiagEnabled m89 : 13|1@1+ (1,0) [0|0] "" Vector__XXX
 SG_ RCM_a090_eventDiagEnabled m90 : 13|1@1+ (1,0) [0|0] "" Vector__XXX
 SG_ RCM_a091_eventDiagEnabled m91 : 13|1@1+ (1,0) [0|0] "" Vector__XXX
 SG_ RCM_a092_eventDiagEnabled m92 : 13|1@1+ (1,0) [0|0] "" Vector__XXX
 SG_ RCM_a093_eventDiagEnabled m93 : 13|1@1+ (1,0) [0|0] "" Vector__XXX
 SG_ RCM_a094_eventDiagEnabled m94 : 13|1@1+ (1,0) [0|0] "" Vector__XXX
 SG_ RCM_a095_eventDiagEnabled m95 : 13|1@1+ (1,0) [0|0] "" Vector__XXX
 SG_ RCM_a096_eventDiagEnabled m96 : 13|1@1+ (1,0) [0|0] "" Vector__XXX
 SG_ RCM_a097_eventDiagEnabled m97 : 13|1@1+ (1,0) [0|0] "" Vector__XXX
 SG_ RCM_a098_eventDiagEnabled m98 : 13|1@1+ (1,0) [0|0] "" Vector__XXX
 SG_ RCM_a099_eventDiagEnabled m99 : 13|1@1+ (1,0) [0|0] "" Vector__XXX
 SG_ RCM_a100_eventDiagEnabled m100 : 13|1@1+ (1,0) [0|0] "" Vector__XXX
 SG_ RCM_a101_eventDiagEnabled m101 : 13|1@1+ (1,0) [0|0] "" Vector__XXX
 SG_ RCM_a102_eventDiagEnabled m102 : 13|1@1+ (1,0) [0|0] "" Vector__XXX
 SG_ RCM_a103_eventDiagEnabled m103 : 13|1@1+ (1,0) [0|0] "" Vector__XXX
 SG_ RCM_a104_eventDiagEnabled m104 : 13|1@1+ (1,0) [0|0] "" Vector__XXX
 SG_ RCM_a105_eventDiagEnabled m105 : 13|1@1+ (1,0) [0|0] "" Vector__XXX
 SG_ RCM_a106_eventDiagEnabled m106 : 13|1@1+ (1,0) [0|0] "" Vector__XXX
 SG_ RCM_a107_eventDiagEnabled m107 : 13|1@1+ (1,0) [0|0] "" Vector__XXX
 SG_ RCM_a108_eventDiagEnabled m108 : 13|1@1+ (1,0) [0|0] "" Vector__XXX
 SG_ RCM_a109_eventDiagEnabled m109 : 13|1@1+ (1,0) [0|0] "" Vector__XXX
 SG_ RCM_a110_eventDiagEnabled m110 : 13|1@1+ (1,0) [0|0] "" Vector__XXX
 SG_ RCM_a111_eventDiagEnabled m111 : 13|1@1+ (1,0) [0|0] "" Vector__XXX
 SG_ RCM_a112_eventDiagEnabled m112 : 13|1@1+ (1,0) [0|0] "" Vector__XXX
 SG_ RCM_a113_eventDiagEnabled m113 : 13|1@1+ (1,0) [0|0] "" Vector__XXX
 SG_ RCM_a114_eventDiagEnabled m114 : 13|1@1+ (1,0) [0|0] "" Vector__XXX
 SG_ RCM_a115_eventDiagEnabled m115 : 13|1@1+ (1,0) [0|0] "" Vector__XXX
 SG_ RCM_a116_eventDiagEnabled m116 : 13|1@1+ (1,0) [0|0] "" Vector__XXX
 SG_ RCM_a117_eventDiagEnabled m117 : 13|1@1+ (1,0) [0|0] "" Vector__XXX
 SG_ RCM_a118_eventDiagEnabled m118 : 13|1@1+ (1,0) [0|0] "" Vector__XXX
 SG_ RCM_a000_eventDriveOrientation m0 : 14|1@1+ (1,0) [0|0] "" Vector__XXX
 SG_ RCM_a001_eventDriveOrientation m1 : 14|1@1+ (1,0) [0|0] "" Vector__XXX
 SG_ RCM_a002_eventDriveOrientation m2 : 14|1@1+ (1,0) [0|0] "" Vector__XXX
 SG_ RCM_a003_eventDriveOrientation m3 : 14|1@1+ (1,0) [0|0] "" Vector__XXX
 SG_ RCM_a004_eventDriveOrientation m4 : 14|1@1+ (1,0) [0|0] "" Vector__XXX
 SG_ RCM_a005_eventDriveOrientation m5 : 14|1@1+ (1,0) [0|0] "" Vector__XXX
 SG_ RCM_a006_eventDriveOrientation m6 : 14|1@1+ (1,0) [0|0] "" Vector__XXX
 SG_ RCM_a007_eventDriveOrientation m7 : 14|1@1+ (1,0) [0|0] "" Vector__XXX
 SG_ RCM_a008_eventDriveOrientation m8 : 14|1@1+ (1,0) [0|0] "" Vector__XXX
 SG_ RCM_a009_eventDriveOrientation m9 : 14|1@1+ (1,0) [0|0] "" Vector__XXX
 SG_ RCM_a010_eventDriveOrientation m10 : 14|1@1+ (1,0) [0|0] "" Vector__XXX
 SG_ RCM_a011_eventDriveOrientation m11 : 14|1@1+ (1,0) [0|0] "" Vector__XXX
 SG_ RCM_a012_eventDriveOrientation m12 : 14|1@1+ (1,0) [0|0] "" Vector__XXX
 SG_ RCM_a013_eventDriveOrientation m13 : 14|1@1+ (1,0) [0|0] "" Vector__XXX
 SG_ RCM_a014_eventDriveOrientation m14 : 14|1@1+ (1,0) [0|0] "" Vector__XXX
 SG_ RCM_a015_eventDriveOrientation m15 : 14|1@1+ (1,0) [0|0] "" Vector__XXX
 SG_ RCM_a016_eventDriveOrientation m16 : 14|1@1+ (1,0) [0|0] "" Vector__XXX
 SG_ RCM_a017_eventDriveOrientation m17 : 14|1@1+ (1,0) [0|0] "" Vector__XXX
 SG_ RCM_a018_eventDriveOrientation m18 : 14|1@1+ (1,0) [0|0] "" Vector__XXX
 SG_ RCM_a019_eventDriveOrientation m19 : 14|1@1+ (1,0) [0|0] "" Vector__XXX
 SG_ RCM_a020_eventDriveOrientation m20 : 14|1@1+ (1,0) [0|0] "" Vector__XXX
 SG_ RCM_a021_eventDriveOrientation m21 : 14|1@1+ (1,0) [0|0] "" Vector__XXX
 SG_ RCM_a022_eventDriveOrientation m22 : 14|1@1+ (1,0) [0|0] "" Vector__XXX
 SG_ RCM_a023_eventDriveOrientation m23 : 14|1@1+ (1,0) [0|0] "" Vector__XXX
 SG_ RCM_a024_eventDriveOrientation m24 : 14|1@1+ (1,0) [0|0] "" Vector__XXX
 SG_ RCM_a025_eventDriveOrientation m25 : 14|1@1+ (1,0) [0|0] "" Vector__XXX
 SG_ RCM_a026_eventDriveOrientation m26 : 14|1@1+ (1,0) [0|0] "" Vector__XXX
 SG_ RCM_a027_eventDriveOrientation m27 : 14|1@1+ (1,0) [0|0] "" Vector__XXX
 SG_ RCM_a028_eventDriveOrientation m28 : 14|1@1+ (1,0) [0|0] "" Vector__XXX
 SG_ RCM_a029_eventDriveOrientation m29 : 14|1@1+ (1,0) [0|0] "" Vector__XXX
 SG_ RCM_a030_eventDriveOrientation m30 : 14|1@1+ (1,0) [0|0] "" Vector__XXX
 SG_ RCM_a031_eventDriveOrientation m31 : 14|1@1+ (1,0) [0|0] "" Vector__XXX
 SG_ RCM_a032_eventDriveOrientation m32 : 14|1@1+ (1,0) [0|0] "" Vector__XXX
 SG_ RCM_a033_eventDriveOrientation m33 : 14|1@1+ (1,0) [0|0] "" Vector__XXX
 SG_ RCM_a034_eventDriveOrientation m34 : 14|1@1+ (1,0) [0|0] "" Vector__XXX
 SG_ RCM_a035_eventDriveOrientation m35 : 14|1@1+ (1,0) [0|0] "" Vector__XXX
 SG_ RCM_a036_eventDriveOrientation m36 : 14|1@1+ (1,0) [0|0] "" Vector__XXX
 SG_ RCM_a037_eventDriveOrientation m37 : 14|1@1+ (1,0) [0|0] "" Vector__XXX
 SG_ RCM_a038_eventDriveOrientation m38 : 14|1@1+ (1,0) [0|0] "" Vector__XXX
 SG_ RCM_a039_eventDriveOrientation m39 : 14|1@1+ (1,0) [0|0] "" Vector__XXX
 SG_ RCM_a040_eventDriveOrientation m40 : 14|1@1+ (1,0) [0|0] "" Vector__XXX
 SG_ RCM_a041_eventDriveOrientation m41 : 14|1@1+ (1,0) [0|0] "" Vector__XXX
 SG_ RCM_a042_eventDriveOrientation m42 : 14|1@1+ (1,0) [0|0] "" Vector__XXX
 SG_ RCM_a043_eventDriveOrientation m43 : 14|1@1+ (1,0) [0|0] "" Vector__XXX
 SG_ RCM_a044_eventDriveOrientation m44 : 14|1@1+ (1,0) [0|0] "" Vector__XXX
 SG_ RCM_a045_eventDriveOrientation m45 : 14|1@1+ (1,0) [0|0] "" Vector__XXX
 SG_ RCM_a046_eventDriveOrientation m46 : 14|1@1+ (1,0) [0|0] "" Vector__XXX
 SG_ RCM_a047_eventDriveOrientation m47 : 14|1@1+ (1,0) [0|0] "" Vector__XXX
 SG_ RCM_a048_eventDriveOrientation m48 : 14|1@1+ (1,0) [0|0] "" Vector__XXX
 SG_ RCM_a049_eventDriveOrientation m49 : 14|1@1+ (1,0) [0|0] "" Vector__XXX
 SG_ RCM_a050_eventDriveOrientation m50 : 14|1@1+ (1,0) [0|0] "" Vector__XXX
 SG_ RCM_a051_eventDriveOrientation m51 : 14|1@1+ (1,0) [0|0] "" Vector__XXX
 SG_ RCM_a052_eventDriveOrientation m52 : 14|1@1+ (1,0) [0|0] "" Vector__XXX
 SG_ RCM_a053_eventDriveOrientation m53 : 14|1@1+ (1,0) [0|0] "" Vector__XXX
 SG_ RCM_a054_eventDriveOrientation m54 : 14|1@1+ (1,0) [0|0] "" Vector__XXX
 SG_ RCM_a055_eventDriveOrientation m55 : 14|1@1+ (1,0) [0|0] "" Vector__XXX
 SG_ RCM_a056_eventDriveOrientation m56 : 14|1@1+ (1,0) [0|0] "" Vector__XXX
 SG_ RCM_a057_eventDriveOrientation m57 : 14|1@1+ (1,0) [0|0] "" Vector__XXX
 SG_ RCM_a058_eventDriveOrientation m58 : 14|1@1+ (1,0) [0|0] "" Vector__XXX
 SG_ RCM_a059_eventDriveOrientation m59 : 14|1@1+ (1,0) [0|0] "" Vector__XXX
 SG_ RCM_a060_eventDriveOrientation m60 : 14|1@1+ (1,0) [0|0] "" Vector__XXX
 SG_ RCM_a061_eventDriveOrientation m61 : 14|1@1+ (1,0) [0|0] "" Vector__XXX
 SG_ RCM_a062_eventDriveOrientation m62 : 14|1@1+ (1,0) [0|0] "" Vector__XXX
 SG_ RCM_a063_eventDriveOrientation m63 : 14|1@1+ (1,0) [0|0] "" Vector__XXX
 SG_ RCM_a064_eventDriveOrientation m64 : 14|1@1+ (1,0) [0|0] "" Vector__XXX
 SG_ RCM_a065_eventDriveOrientation m65 : 14|1@1+ (1,0) [0|0] "" Vector__XXX
 SG_ RCM_a066_eventDriveOrientation m66 : 14|1@1+ (1,0) [0|0] "" Vector__XXX
 SG_ RCM_a067_eventDriveOrientation m67 : 14|1@1+ (1,0) [0|0] "" Vector__XXX
 SG_ RCM_a068_eventDriveOrientation m68 : 14|1@1+ (1,0) [0|0] "" Vector__XXX
 SG_ RCM_a069_eventDriveOrientation m69 : 14|1@1+ (1,0) [0|0] "" Vector__XXX
 SG_ RCM_a070_eventDriveOrientation m70 : 14|1@1+ (1,0) [0|0] "" Vector__XXX
 SG_ RCM_a071_eventDriveOrientation m71 : 14|1@1+ (1,0) [0|0] "" Vector__XXX
 SG_ RCM_a072_eventDriveOrientation m72 : 14|1@1+ (1,0) [0|0] "" Vector__XXX
 SG_ RCM_a073_eventDriveOrientation m73 : 14|1@1+ (1,0) [0|0] "" Vector__XXX
 SG_ RCM_a074_eventDriveOrientation m74 : 14|1@1+ (1,0) [0|0] "" Vector__XXX
 SG_ RCM_a075_eventDriveOrientation m75 : 14|1@1+ (1,0) [0|0] "" Vector__XXX
 SG_ RCM_a076_eventDriveOrientation m76 : 14|1@1+ (1,0) [0|0] "" Vector__XXX
 SG_ RCM_a077_eventDriveOrientation m77 : 14|1@1+ (1,0) [0|0] "" Vector__XXX
 SG_ RCM_a078_eventDriveOrientation m78 : 14|1@1+ (1,0) [0|0] "" Vector__XXX
 SG_ RCM_a079_eventDriveOrientation m79 : 14|1@1+ (1,0) [0|0] "" Vector__XXX
 SG_ RCM_a080_eventDriveOrientation m80 : 14|1@1+ (1,0) [0|0] "" Vector__XXX
 SG_ RCM_a081_eventDriveOrientation m81 : 14|1@1+ (1,0) [0|0] "" Vector__XXX
 SG_ RCM_a082_eventDriveOrientation m82 : 14|1@1+ (1,0) [0|0] "" Vector__XXX
 SG_ RCM_a083_eventDriveOrientation m83 : 14|1@1+ (1,0) [0|0] "" Vector__XXX
 SG_ RCM_a084_eventDriveOrientation m84 : 14|1@1+ (1,0) [0|0] "" Vector__XXX
 SG_ RCM_a085_eventDriveOrientation m85 : 14|1@1+ (1,0) [0|0] "" Vector__XXX
 SG_ RCM_a086_eventDriveOrientation m86 : 14|1@1+ (1,0) [0|0] "" Vector__XXX
 SG_ RCM_a087_eventDriveOrientation m87 : 14|1@1+ (1,0) [0|0] "" Vector__XXX
 SG_ RCM_a088_eventDriveOrientation m88 : 14|1@1+ (1,0) [0|0] "" Vector__XXX
 SG_ RCM_a089_eventDriveOrientation m89 : 14|1@1+ (1,0) [0|0] "" Vector__XXX
 SG_ RCM_a090_eventDriveOrientation m90 : 14|1@1+ (1,0) [0|0] "" Vector__XXX
 SG_ RCM_a091_eventDriveOrientation m91 : 14|1@1+ (1,0) [0|0] "" Vector__XXX
 SG_ RCM_a092_eventDriveOrientation m92 : 14|1@1+ (1,0) [0|0] "" Vector__XXX
 SG_ RCM_a093_eventDriveOrientation m93 : 14|1@1+ (1,0) [0|0] "" Vector__XXX
 SG_ RCM_a094_eventDriveOrientation m94 : 14|1@1+ (1,0) [0|0] "" Vector__XXX
 SG_ RCM_a095_eventDriveOrientation m95 : 14|1@1+ (1,0) [0|0] "" Vector__XXX
 SG_ RCM_a096_eventDriveOrientation m96 : 14|1@1+ (1,0) [0|0] "" Vector__XXX
 SG_ RCM_a097_eventDriveOrientation m97 : 14|1@1+ (1,0) [0|0] "" Vector__XXX
 SG_ RCM_a098_eventDriveOrientation m98 : 14|1@1+ (1,0) [0|0] "" Vector__XXX
 SG_ RCM_a099_eventDriveOrientation m99 : 14|1@1+ (1,0) [0|0] "" Vector__XXX
 SG_ RCM_a100_eventDriveOrientation m100 : 14|1@1+ (1,0) [0|0] "" Vector__XXX
 SG_ RCM_a101_eventDriveOrientation m101 : 14|1@1+ (1,0) [0|0] "" Vector__XXX
 SG_ RCM_a102_eventDriveOrientation m102 : 14|1@1+ (1,0) [0|0] "" Vector__XXX
 SG_ RCM_a103_eventDriveOrientation m103 : 14|1@1+ (1,0) [0|0] "" Vector__XXX
 SG_ RCM_a104_eventDriveOrientation m104 : 14|1@1+ (1,0) [0|0] "" Vector__XXX
 SG_ RCM_a105_eventDriveOrientation m105 : 14|1@1+ (1,0) [0|0] "" Vector__XXX
 SG_ RCM_a106_eventDriveOrientation m106 : 14|1@1+ (1,0) [0|0] "" Vector__XXX
 SG_ RCM_a107_eventDriveOrientation m107 : 14|1@1+ (1,0) [0|0] "" Vector__XXX
 SG_ RCM_a108_eventDriveOrientation m108 : 14|1@1+ (1,0) [0|0] "" Vector__XXX
 SG_ RCM_a109_eventDriveOrientation m109 : 14|1@1+ (1,0) [0|0] "" Vector__XXX
 SG_ RCM_a110_eventDriveOrientation m110 : 14|1@1+ (1,0) [0|0] "" Vector__XXX
 SG_ RCM_a111_eventDriveOrientation m111 : 14|1@1+ (1,0) [0|0] "" Vector__XXX
 SG_ RCM_a112_eventDriveOrientation m112 : 14|1@1+ (1,0) [0|0] "" Vector__XXX
 SG_ RCM_a113_eventDriveOrientation m113 : 14|1@1+ (1,0) [0|0] "" Vector__XXX
 SG_ RCM_a114_eventDriveOrientation m114 : 14|1@1+ (1,0) [0|0] "" Vector__XXX
 SG_ RCM_a115_eventDriveOrientation m115 : 14|1@1+ (1,0) [0|0] "" Vector__XXX
 SG_ RCM_a116_eventDriveOrientation m116 : 14|1@1+ (1,0) [0|0] "" Vector__XXX
 SG_ RCM_a117_eventDriveOrientation m117 : 14|1@1+ (1,0) [0|0] "" Vector__XXX
 SG_ RCM_a118_eventDriveOrientation m118 : 14|1@1+ (1,0) [0|0] "" Vector__XXX
 SG_ RCM_a000_crashDetectedFront m0 : 16|1@1+ (1,0) [0|0] "" Vector__XXX
 SG_ RCM_a001_nearDeployFront m1 : 16|1@1+ (1,0) [0|0] "" Vector__XXX
 SG_ RCM_a002_airbagsUnArmed m2 : 16|1@1+ (1,0) [0|0] "" Vector__XXX
 SG_ RCM_a003_warningIndicatorOn m3 : 16|1@1+ (1,0) [0|0] "" Vector__XXX
 SG_ RCM_a004_frontAlgoDisabled m4 : 16|1@1+ (1,0) [0|0] "" Vector__XXX
 SG_ RCM_a005_externalCRCError m5 : 16|1@1+ (1,0) [0|0] "" Vector__XXX
 SG_ RCM_a006_batteryVoltageTooHigh m6 : 16|1@1+ (1,0) [0|0] "" Vector__XXX
 SG_ RCM_a007_lossOfMainPowerSupply m7 : 16|1@1+ (1,0) [0|0] "" Vector__XXX
 SG_ RCM_a008_lossOfMainPwrSupMonit m8 : 16|1@1+ (1,0) [0|0] "" Vector__XXX
 SG_ RCM_a009_reprogramLimitExceeded m9 : 16|1@1+ (1,0) [0|0] "" Vector__XXX
 SG_ RCM_a010_scmNotFunctional m10 : 16|1@1+ (1,0) [0|0] "" Vector__XXX
 SG_ RCM_a011_edrDataAreaLocked m11 : 16|1@1+ (1,0) [0|0] "" Vector__XXX
 SG_ RCM_a012_vinMismatch m12 : 16|1@1+ (1,0) [0|0] "" Vector__XXX
 SG_ RCM_a013_driveOrientiInitNotDone m13 : 16|1@1+ (1,0) [0|0] "" Vector__XXX
 SG_ RCM_a014_driverABStg1Sht2Gnd m14 : 16|1@1+ (1,0) [0|0] "" Vector__XXX
 SG_ RCM_a015_driverABStg2Sht2Gnd m15 : 16|1@1+ (1,0) [0|0] "" Vector__XXX
 SG_ RCM_a016_passABStg1Sht2Gnd m16 : 16|1@1+ (1,0) [0|0] "" Vector__XXX
 SG_ RCM_a017_passABStg2Sht2Gnd m17 : 16|1@1+ (1,0) [0|0] "" Vector__XXX
 SG_ RCM_a018_passActiveVentSht2Gnd m18 : 16|1@1+ (1,0) [0|0] "" Vector__XXX
 SG_ RCM_a019_pretenShldLeftSht2Gnd m19 : 16|1@1+ (1,0) [0|0] "" Vector__XXX
 SG_ RCM_a020_pretenShldRightSht2Gnd m20 : 16|1@1+ (1,0) [0|0] "" Vector__XXX
 SG_ RCM_a021_pretenLapLeftSht2Gnd m21 : 16|1@1+ (1,0) [0|0] "" Vector__XXX
 SG_ RCM_a022_pretenLapRightSht2Gnd m22 : 16|1@1+ (1,0) [0|0] "" Vector__XXX
 SG_ RCM_a023_loadLimLeftSht2Gnd m23 : 16|1@1+ (1,0) [0|0] "" Vector__XXX
 SG_ RCM_a024_loadLimRightSht2Gnd m24 : 16|1@1+ (1,0) [0|0] "" Vector__XXX
 SG_ RCM_a025_kneeABDrvrSht2Gnd m25 : 16|1@1+ (1,0) [0|0] "" Vector__XXX
 SG_ RCM_a026_kneeABPassSht2Gnd m26 : 16|1@1+ (1,0) [0|0] "" Vector__XXX
 SG_ RCM_a027_sideAB1stRowLSht2Gnd m27 : 16|1@1+ (1,0) [0|0] "" Vector__XXX
 SG_ RCM_a028_sideAB1stRowRSht2Gnd m28 : 16|1@1+ (1,0) [0|0] "" Vector__XXX
 SG_ RCM_a029_driverABAVSht2Gnd m29 : 16|1@1+ (1,0) [0|0] "" Vector__XXX
 SG_ RCM_a030_farsideABSht2Gnd m30 : 16|1@1+ (1,0) [0|0] "" Vector__XXX
 SG_ RCM_a031_frntCentrABSht2Gnd m31 : 16|1@1+ (1,0) [0|0] "" Vector__XXX
 SG_ RCM_a032_curABLeftSht2Gnd m32 : 16|1@1+ (1,0) [0|0] "" Vector__XXX
 SG_ RCM_a033_curABRightSht2Gnd m33 : 16|1@1+ (1,0) [0|0] "" Vector__XXX
 SG_ RCM_a034_preten2ndRowLSht2Gnd m34 : 16|1@1+ (1,0) [0|0] "" Vector__XXX
 SG_ RCM_a035_preten2ndRowRSht2Gnd m35 : 16|1@1+ (1,0) [0|0] "" Vector__XXX
 SG_ RCM_a036_curAB2ndRowLSht2Gnd m36 : 16|1@1+ (1,0) [0|0] "" Vector__XXX
 SG_ RCM_a037_curAB2ndRowRSht2Gnd m37 : 16|1@1+ (1,0) [0|0] "" Vector__XXX
 SG_ RCM_a038_unused1 m38 : 16|1@1+ (1,0) [0|0] "" Vector__XXX
 SG_ RCM_a039_unused7 m39 : 16|1@1+ (1,0) [0|0] "" Vector__XXX
 SG_ RCM_a040_hoodActuatorRSht2Gnd m40 : 16|1@1+ (1,0) [0|0] "" Vector__XXX
 SG_ RCM_a041_hoodActuatorLSht2Gnd m41 : 16|1@1+ (1,0) [0|0] "" Vector__XXX
 SG_ RCM_a042_ens1Sht2Bat m42 : 16|1@1+ (1,0) [0|0] "" Vector__XXX
 SG_ RCM_a043_ens2Sht2Bat m43 : 16|1@1+ (1,0) [0|0] "" Vector__XXX
 SG_ RCM_a044_upFrontSensorLSht2Gnd m44 : 16|1@1+ (1,0) [0|0] "" Vector__XXX
 SG_ RCM_a045_upFrontSensorRSht2Gnd m45 : 16|1@1+ (1,0) [0|0] "" Vector__XXX
 SG_ RCM_a046_sideAccelBPilLSht2Gnd m46 : 16|1@1+ (1,0) [0|0] "" Vector__XXX
 SG_ RCM_a047_sideAccelBPilRSht2Gnd m47 : 16|1@1+ (1,0) [0|0] "" Vector__XXX
 SG_ RCM_a048_sideAccelCPilLSht2Gnd m48 : 16|1@1+ (1,0) [0|0] "" Vector__XXX
 SG_ RCM_a049_sideAccelCPilRSht2Gnd m49 : 16|1@1+ (1,0) [0|0] "" Vector__XXX
 SG_ RCM_a050_upFrontSensorCSht2Gnd m50 : 16|1@1+ (1,0) [0|0] "" Vector__XXX
 SG_ RCM_a051_presFrntLDoorComm m51 : 16|1@1+ (1,0) [0|0] "" Vector__XXX
 SG_ RCM_a052_presFrntRDoorComm m52 : 16|1@1+ (1,0) [0|0] "" Vector__XXX
 SG_ RCM_a053_presPedProLComm m53 : 16|1@1+ (1,0) [0|0] "" Vector__XXX
 SG_ RCM_a054_presPedProRComm m54 : 16|1@1+ (1,0) [0|0] "" Vector__XXX
 SG_ RCM_a055_imuCalibrationNotDone m55 : 16|1@1+ (1,0) [0|0] "" Vector__XXX
 SG_ RCM_a056_ocs1pFaulted m56 : 16|1@1+ (1,0) [0|0] "" Vector__XXX
 SG_ RCM_a057_ocs1dFaulted m57 : 16|1@1+ (1,0) [0|0] "" Vector__XXX
 SG_ RCM_a058_bucklHallLeftShort m58 : 16|1@1+ (1,0) [0|0] "" Vector__XXX
 SG_ RCM_a059_bucklHallRightShort m59 : 16|1@1+ (1,0) [0|0] "" Vector__XXX
 SG_ RCM_a060_seaTrkPosLeftShort m60 : 16|1@1+ (1,0) [0|0] "" Vector__XXX
 SG_ RCM_a061_seaTrkPosRightShort m61 : 16|1@1+ (1,0) [0|0] "" Vector__XXX
 SG_ RCM_a062_alrShort m62 : 16|1@1+ (1,0) [0|0] "" Vector__XXX
 SG_ RCM_a063_sbsw2ndRowRSht2Gnd m63 : 16|1@1+ (1,0) [0|0] "" Vector__XXX
 SG_ RCM_a064_hwcp1CheckFail m64 : 16|1@1+ (1,0) [0|0] "" Vector__XXX
 SG_ RCM_a065_swDrvrOrientCheck m65 : 16|1@1+ (1,0) [0|0] "" Vector__XXX
 SG_ RCM_a066_sbsw2ndRowLShort m66 : 16|1@1+ (1,0) [0|0] "" Vector__XXX
 SG_ RCM_a067_comCANInitialization m67 : 16|1@1+ (1,0) [0|0] "" Vector__XXX
 SG_ RCM_a068_comChassisCANBusOff m68 : 16|1@1+ (1,0) [0|0] "" Vector__XXX
 SG_ RCM_a069_comChassisCANPH7MIA m69 : 16|1@1+ (1,0) [0|0] "" Vector__XXX
 SG_ RCM_a070_comChassisCANPH8MIA m70 : 16|1@1+ (1,0) [0|0] "" Vector__XXX
 SG_ RCM_a071_comChassisCANPH9MIA m71 : 16|1@1+ (1,0) [0|0] "" Vector__XXX
 SG_ RCM_a072_comUnusedMIA m72 : 16|1@1+ (1,0) [0|0] "" Vector__XXX
 SG_ RCM_a073_comChassisCANPH4MIA m73 : 16|1@1+ (1,0) [0|0] "" Vector__XXX
 SG_ RCM_a074_comChassisCANPH5MIA m74 : 16|1@1+ (1,0) [0|0] "" Vector__XXX
 SG_ RCM_a075_comChassisCANPH6MIA m75 : 16|1@1+ (1,0) [0|0] "" Vector__XXX
 SG_ RCM_a076_comEPBLStatusMIA m76 : 16|1@1+ (1,0) [0|0] "" Vector__XXX
 SG_ RCM_a077_comEPBRStatusMIA m77 : 16|1@1+ (1,0) [0|0] "" Vector__XXX
 SG_ RCM_a078_comOCS1PMIA m78 : 16|1@1+ (1,0) [0|0] "" Vector__XXX
 SG_ RCM_a079_comOCS1DMIA m79 : 16|1@1+ (1,0) [0|0] "" Vector__XXX
 SG_ RCM_a080_comGTWACSMIA m80 : 16|1@1+ (1,0) [0|0] "" Vector__XXX
 SG_ RCM_a081_comVCFRONTLVPrwMIA m81 : 16|1@1+ (1,0) [0|0] "" Vector__XXX
 SG_ RCM_a082_comUIodoMIA m82 : 16|1@1+ (1,0) [0|0] "" Vector__XXX
 SG_ RCM_a083_comGTWCarStateMIA m83 : 16|1@1+ (1,0) [0|0] "" Vector__XXX
 SG_ RCM_a084_comTPMSStatusMIA m84 : 16|1@1+ (1,0) [0|0] "" Vector__XXX
 SG_ RCM_a085_comGTWCarConfigMIA m85 : 16|1@1+ (1,0) [0|0] "" Vector__XXX
 SG_ RCM_a086_comVINmessageMIA m86 : 16|1@1+ (1,0) [0|0] "" Vector__XXX
 SG_ RCM_a087_comChassisCANSilent m87 : 16|1@1+ (1,0) [0|0] "" Vector__XXX
 SG_ RCM_a088_comChassisCANPH2MIA m88 : 16|1@1+ (1,0) [0|0] "" Vector__XXX
 SG_ RCM_a089_comChassisCANPH3MIA m89 : 16|1@1+ (1,0) [0|0] "" Vector__XXX
 SG_ RCM_a090_comPartyCANBusOff m90 : 16|1@1+ (1,0) [0|0] "" Vector__XXX
 SG_ RCM_a091_comEPAS3PStAnglInvlidQF m91 : 16|1@1+ (1,0) [0|0] "" Vector__XXX
 SG_ RCM_a092_comDASSafetyFrontMIA m92 : 16|1@1+ (1,0) [0|0] "" Vector__XXX
 SG_ RCM_a093_comVCLEFTStatusMIA m93 : 16|1@1+ (1,0) [0|0] "" Vector__XXX
 SG_ RCM_a094_comVCRIGHTStatusMIA m94 : 16|1@1+ (1,0) [0|0] "" Vector__XXX
 SG_ RCM_a095_comESPstatusMIA m95 : 16|1@1+ (1,0) [0|0] "" Vector__XXX
 SG_ RCM_a096_comESPwheelSpeedsMIA m96 : 16|1@1+ (1,0) [0|0] "" Vector__XXX
 SG_ RCM_a097_comDIspeedMIA m97 : 16|1@1+ (1,0) [0|0] "" Vector__XXX
 SG_ RCM_a098_comDIchassisControlMIA m98 : 16|1@1+ (1,0) [0|0] "" Vector__XXX
 SG_ RCM_a099_comDItorqueMIA m99 : 16|1@1+ (1,0) [0|0] "" Vector__XXX
 SG_ RCM_a100_comDIsystemStatusMIA m100 : 16|1@1+ (1,0) [0|0] "" Vector__XXX
 SG_ RCM_a101_idfMisuseMonitoringErr m101 : 16|1@1+ (1,0) [0|0] "" Vector__XXX
 SG_ RCM_a102_imuYawR8OffCompPosLife m102 : 16|1@1+ (1,0) [0|0] "" Vector__XXX
 SG_ RCM_a103_imuPtchR8OffCompPosLife m103 : 16|1@1+ (1,0) [0|0] "" Vector__XXX
 SG_ RCM_a104_imuRollR8OffCompPosLife m104 : 16|1@1+ (1,0) [0|0] "" Vector__XXX
 SG_ RCM_a105_imuLongAOffCompPosLife m105 : 16|1@1+ (1,0) [0|0] "" Vector__XXX
 SG_ RCM_a106_imuLatAcOffCompPosLife m106 : 16|1@1+ (1,0) [0|0] "" Vector__XXX
 SG_ RCM_a107_imuVertAOffCompPosLife m107 : 16|1@1+ (1,0) [0|0] "" Vector__XXX
 SG_ RCM_a108_crashAlgoWakeupSig m108 : 16|1@1+ (1,0) [0|0] "" Vector__XXX
 SG_ RCM_a109_immunityThrsholdCrossed m109 : 16|1@1+ (1,0) [0|0] "" Vector__XXX
 SG_ RCM_a110_inFactoryMode m110 : 16|1@1+ (1,0) [0|0] "" Vector__XXX
 SG_ RCM_a111_diagEnabled m111 : 16|1@1+ (1,0) [0|0] "" Vector__XXX
 SG_ RCM_a112_imuYawR8SnsrMonitTmp m112 : 16|1@1+ (1,0) [0|0] "" Vector__XXX
 SG_ RCM_a113_imuPitchR8SnsrMonitTmp m113 : 16|1@1+ (1,0) [0|0] "" Vector__XXX
 SG_ RCM_a114_imuRollR8SnsrMonitTmp m114 : 16|1@1+ (1,0) [0|0] "" Vector__XXX
 SG_ RCM_a115_imuLinAccChnlMonitTmp m115 : 16|1@1+ (1,0) [0|0] "" Vector__XXX
 SG_ RCM_a116_imuLatAccChnlMonitTmp m116 : 16|1@1+ (1,0) [0|0] "" Vector__XXX
 SG_ RCM_a117_imuZaccelChnlMonitTmp m117 : 16|1@1+ (1,0) [0|0] "" Vector__XXX
 SG_ RCM_a118_imuInPlaneSnsrMonitTmp m118 : 16|1@1+ (1,0) [0|0] "" Vector__XXX
 SG_ RCM_a000_crashDetectedRear m0 : 17|1@1+ (1,0) [0|0] "" Vector__XXX
 SG_ RCM_a001_nearDeployRear m1 : 17|1@1+ (1,0) [0|0] "" Vector__XXX
 SG_ RCM_a004_sideAlgoDisabled m4 : 17|1@1+ (1,0) [0|0] "" Vector__XXX
 SG_ RCM_a006_batteryVoltageTooLow m6 : 17|1@1+ (1,0) [0|0] "" Vector__XXX
 SG_ RCM_a007_lossOfBackupPowerSupply m7 : 17|1@1+ (1,0) [0|0] "" Vector__XXX
 SG_ RCM_a008_lossOfBckupPwrSupMonit m8 : 17|1@1+ (1,0) [0|0] "" Vector__XXX
 SG_ RCM_a012_vinNotProgrammed m12 : 17|1@1+ (1,0) [0|0] "" Vector__XXX
 SG_ RCM_a013_driveOrientPlausiCheck m13 : 17|1@1+ (1,0) [0|0] "" Vector__XXX
 SG_ RCM_a014_driverABStg1Sht2Bat m14 : 17|1@1+ (1,0) [0|0] "" Vector__XXX
 SG_ RCM_a015_driverABStg2Sht2Bat m15 : 17|1@1+ (1,0) [0|0] "" Vector__XXX
 SG_ RCM_a016_passABStg1Sht2Bat m16 : 17|1@1+ (1,0) [0|0] "" Vector__XXX
 SG_ RCM_a017_passABStg2Sht2Bat m17 : 17|1@1+ (1,0) [0|0] "" Vector__XXX
 SG_ RCM_a018_passActiveVentSht2Bat m18 : 17|1@1+ (1,0) [0|0] "" Vector__XXX
 SG_ RCM_a019_pretenShldLeftSht2Bat m19 : 17|1@1+ (1,0) [0|0] "" Vector__XXX
 SG_ RCM_a020_pretenShldRightSht2Bat m20 : 17|1@1+ (1,0) [0|0] "" Vector__XXX
 SG_ RCM_a021_pretenLapLeftSht2Bat m21 : 17|1@1+ (1,0) [0|0] "" Vector__XXX
 SG_ RCM_a022_pretenLapRightSht2Bat m22 : 17|1@1+ (1,0) [0|0] "" Vector__XXX
 SG_ RCM_a023_loadLimLeftSht2Bat m23 : 17|1@1+ (1,0) [0|0] "" Vector__XXX
 SG_ RCM_a024_loadLimRightSht2Bat m24 : 17|1@1+ (1,0) [0|0] "" Vector__XXX
 SG_ RCM_a025_kneeABDrvrSht2Bat m25 : 17|1@1+ (1,0) [0|0] "" Vector__XXX
 SG_ RCM_a026_kneeABPassSht2Bat m26 : 17|1@1+ (1,0) [0|0] "" Vector__XXX
 SG_ RCM_a027_sideAB1stRowLSht2Bat m27 : 17|1@1+ (1,0) [0|0] "" Vector__XXX
 SG_ RCM_a028_sideAB1stRowRSht2Bat m28 : 17|1@1+ (1,0) [0|0] "" Vector__XXX
 SG_ RCM_a029_driverABAVSht2Bat m29 : 17|1@1+ (1,0) [0|0] "" Vector__XXX
 SG_ RCM_a030_farsideABSht2Bat m30 : 17|1@1+ (1,0) [0|0] "" Vector__XXX
 SG_ RCM_a031_frntCentrABSht2Bat m31 : 17|1@1+ (1,0) [0|0] "" Vector__XXX
 SG_ RCM_a032_curABLeftSht2Bat m32 : 17|1@1+ (1,0) [0|0] "" Vector__XXX
 SG_ RCM_a033_curABRightSht2Bat m33 : 17|1@1+ (1,0) [0|0] "" Vector__XXX
 SG_ RCM_a034_preten2ndRowLSht2Bat m34 : 17|1@1+ (1,0) [0|0] "" Vector__XXX
 SG_ RCM_a035_preten2ndRowRSht2Bat m35 : 17|1@1+ (1,0) [0|0] "" Vector__XXX
 SG_ RCM_a036_curAB2ndRowLSht2Bat m36 : 17|1@1+ (1,0) [0|0] "" Vector__XXX
 SG_ RCM_a037_curAB2ndRowRSht2Bat m37 : 17|1@1+ (1,0) [0|0] "" Vector__XXX
 SG_ RCM_a038_unused2 m38 : 17|1@1+ (1,0) [0|0] "" Vector__XXX
 SG_ RCM_a039_unused8 m39 : 17|1@1+ (1,0) [0|0] "" Vector__XXX
 SG_ RCM_a040_hoodActuatorRSht2Bat m40 : 17|1@1+ (1,0) [0|0] "" Vector__XXX
 SG_ RCM_a041_hoodActuatorLSht2Bat m41 : 17|1@1+ (1,0) [0|0] "" Vector__XXX
 SG_ RCM_a042_ens1Sht2Gnd m42 : 17|1@1+ (1,0) [0|0] "" Vector__XXX
 SG_ RCM_a043_ens2Sht2Gnd m43 : 17|1@1+ (1,0) [0|0] "" Vector__XXX
 SG_ RCM_a044_upFrontSensorLSht2Bat m44 : 17|1@1+ (1,0) [0|0] "" Vector__XXX
 SG_ RCM_a045_upFrontSensorRSht2Bat m45 : 17|1@1+ (1,0) [0|0] "" Vector__XXX
 SG_ RCM_a046_sideAccelBPilLSht2Bat m46 : 17|1@1+ (1,0) [0|0] "" Vector__XXX
 SG_ RCM_a047_sideAccelBPilRSht2Bat m47 : 17|1@1+ (1,0) [0|0] "" Vector__XXX
 SG_ RCM_a048_sideAccelCPilLSht2Bat m48 : 17|1@1+ (1,0) [0|0] "" Vector__XXX
 SG_ RCM_a049_sideAccelCPilRSht2Bat m49 : 17|1@1+ (1,0) [0|0] "" Vector__XXX
 SG_ RCM_a050_upFrontSensorCSht2Bat m50 : 17|1@1+ (1,0) [0|0] "" Vector__XXX
 SG_ RCM_a051_presFrntLDoorInitTyp m51 : 17|1@1+ (1,0) [0|0] "" Vector__XXX
 SG_ RCM_a052_presFrntRDoorInitTyp m52 : 17|1@1+ (1,0) [0|0] "" Vector__XXX
 SG_ RCM_a053_presPedProLInitTyp m53 : 17|1@1+ (1,0) [0|0] "" Vector__XXX
 SG_ RCM_a054_presPedProRInitTyp m54 : 17|1@1+ (1,0) [0|0] "" Vector__XXX
 SG_ RCM_a055_imuCalibrationFailed m55 : 17|1@1+ (1,0) [0|0] "" Vector__XXX
 SG_ RCM_a056_ocs1pWrongCalD m56 : 17|1@1+ (1,0) [0|0] "" Vector__XXX
 SG_ RCM_a057_ocs1dWrongCalD m57 : 17|1@1+ (1,0) [0|0] "" Vector__XXX
 SG_ RCM_a058_bucklHallLeftSht2Bat m58 : 17|1@1+ (1,0) [0|0] "" Vector__XXX
 SG_ RCM_a059_bucklHallRightSht2Bat m59 : 17|1@1+ (1,0) [0|0] "" Vector__XXX
 SG_ RCM_a060_seaTrkPosLeftShort2Bat m60 : 17|1@1+ (1,0) [0|0] "" Vector__XXX
 SG_ RCM_a061_seaTrkPosRightSht2Bat m61 : 17|1@1+ (1,0) [0|0] "" Vector__XXX
 SG_ RCM_a062_alrSht2Bat m62 : 17|1@1+ (1,0) [0|0] "" Vector__XXX
 SG_ RCM_a063_sbsw2ndRowRSht2Bat m63 : 17|1@1+ (1,0) [0|0] "" Vector__XXX
 SG_ RCM_a064_hwcp1Sht2Bat m64 : 17|1@1+ (1,0) [0|0] "" Vector__XXX
 SG_ RCM_a065_swDrvrOrientSht2Bat m65 : 17|1@1+ (1,0) [0|0] "" Vector__XXX
 SG_ RCM_a066_sbsw2ndRowLSht2Bat m66 : 17|1@1+ (1,0) [0|0] "" Vector__XXX
 SG_ RCM_a069_comChassisCANPH7ChkSm m69 : 17|1@1+ (1,0) [0|0] "" Vector__XXX
 SG_ RCM_a070_comChassisCANPH8ChkSm m70 : 17|1@1+ (1,0) [0|0] "" Vector__XXX
 SG_ RCM_a071_comChassisCANPH9ChkSm m71 : 17|1@1+ (1,0) [0|0] "" Vector__XXX
 SG_ RCM_a072_comUnusedChkSm m72 : 17|1@1+ (1,0) [0|0] "" Vector__XXX
 SG_ RCM_a073_comChassisCANPH4ChkSm m73 : 17|1@1+ (1,0) [0|0] "" Vector__XXX
 SG_ RCM_a074_comChassisCANPH5ChkSm m74 : 17|1@1+ (1,0) [0|0] "" Vector__XXX
 SG_ RCM_a075_comChassisCANPH6ChkSm m75 : 17|1@1+ (1,0) [0|0] "" Vector__XXX
 SG_ RCM_a076_comEPBLStatusChkSm m76 : 17|1@1+ (1,0) [0|0] "" Vector__XXX
 SG_ RCM_a077_comEPBRStatusChkSm m77 : 17|1@1+ (1,0) [0|0] "" Vector__XXX
 SG_ RCM_a078_comOCS1PChkSm m78 : 17|1@1+ (1,0) [0|0] "" Vector__XXX
 SG_ RCM_a079_comOCS1DChkSm m79 : 17|1@1+ (1,0) [0|0] "" Vector__XXX
 SG_ RCM_a080_comGTWACSChkSm m80 : 17|1@1+ (1,0) [0|0] "" Vector__XXX
 SG_ RCM_a081_comVCFRONTLVPwrChkSm m81 : 17|1@1+ (1,0) [0|0] "" Vector__XXX
 SG_ RCM_a087_comPARTYCANSilent m87 : 17|1@1+ (1,0) [0|0] "" Vector__XXX
 SG_ RCM_a088_comChassisCANPH2ChkSm m88 : 17|1@1+ (1,0) [0|0] "" Vector__XXX
 SG_ RCM_a089_comChassisCANPH3ChkSm m89 : 17|1@1+ (1,0) [0|0] "" Vector__XXX
 SG_ RCM_a091_comEPAS3PsysStatusMIA m91 : 17|1@1+ (1,0) [0|0] "" Vector__XXX
 SG_ RCM_a092_comDASSafetyFrontChkSm m92 : 17|1@1+ (1,0) [0|0] "" Vector__XXX
 SG_ RCM_a093_comVCLEFTStatusChkSm m93 : 17|1@1+ (1,0) [0|0] "" Vector__XXX
 SG_ RCM_a094_comVCRIGHTStatusChkSm m94 : 17|1@1+ (1,0) [0|0] "" Vector__XXX
 SG_ RCM_a095_comESPstatusChkSm m95 : 17|1@1+ (1,0) [0|0] "" Vector__XXX
 SG_ RCM_a096_comESPwheelSpeedsChkSm m96 : 17|1@1+ (1,0) [0|0] "" Vector__XXX
 SG_ RCM_a097_comDIspeedChkSm m97 : 17|1@1+ (1,0) [0|0] "" Vector__XXX
 SG_ RCM_a098_comDIchassisCntrlChkSm m98 : 17|1@1+ (1,0) [0|0] "" Vector__XXX
 SG_ RCM_a099_comDItorqueChkSm m99 : 17|1@1+ (1,0) [0|0] "" Vector__XXX
 SG_ RCM_a100_comDIsystemStatusChkSm m100 : 17|1@1+ (1,0) [0|0] "" Vector__XXX
 SG_ RCM_a101_idfEnviMonitoringError m101 : 17|1@1+ (1,0) [0|0] "" Vector__XXX
 SG_ RCM_a102_imuYawR8OffCompNegLife m102 : 17|1@1+ (1,0) [0|0] "" Vector__XXX
 SG_ RCM_a103_imuPtchR8OffCompNegLife m103 : 17|1@1+ (1,0) [0|0] "" Vector__XXX
 SG_ RCM_a104_imuRollR8OffCompNegLife m104 : 17|1@1+ (1,0) [0|0] "" Vector__XXX
 SG_ RCM_a105_imuLongAOffCompNegLife m105 : 17|1@1+ (1,0) [0|0] "" Vector__XXX
 SG_ RCM_a106_imuLatAcOffCompNegLife m106 : 17|1@1+ (1,0) [0|0] "" Vector__XXX
 SG_ RCM_a107_imuVertAOffCompNegLife m107 : 17|1@1+ (1,0) [0|0] "" Vector__XXX
 SG_ RCM_a112_imuYawR8SnsrMonitPerm m112 : 17|1@1+ (1,0) [0|0] "" Vector__XXX
 SG_ RCM_a113_imuPitchR8SnsrMonitPerm m113 : 17|1@1+ (1,0) [0|0] "" Vector__XXX
 SG_ RCM_a114_imuRollR8SnsrMonitPerm m114 : 17|1@1+ (1,0) [0|0] "" Vector__XXX
 SG_ RCM_a115_imuLinAccChnlMonitPerm m115 : 17|1@1+ (1,0) [0|0] "" Vector__XXX
 SG_ RCM_a116_imuLatAccChnlMonitPerm m116 : 17|1@1+ (1,0) [0|0] "" Vector__XXX
 SG_ RCM_a117_imuZaccelChnlMonitPerm m117 : 17|1@1+ (1,0) [0|0] "" Vector__XXX
 SG_ RCM_a118_imuInPlaneSnsrMonitPerm m118 : 17|1@1+ (1,0) [0|0] "" Vector__XXX
 SG_ RCM_a000_crashDetectedLeft m0 : 18|1@1+ (1,0) [0|0] "" Vector__XXX
 SG_ RCM_a001_nearDeployLeft m1 : 18|1@1+ (1,0) [0|0] "" Vector__XXX
 SG_ RCM_a004_rollAlgoDisabled m4 : 18|1@1+ (1,0) [0|0] "" Vector__XXX
 SG_ RCM_a007_invalidShtdwnReqSequnce m7 : 18|1@1+ (1,0) [0|0] "" Vector__XXX
 SG_ RCM_a008_normalShtdwnUnavail m8 : 18|1@1+ (1,0) [0|0] "" Vector__XXX
 SG_ RCM_a014_driverABStg1Open m14 : 18|1@1+ (1,0) [0|0] "" Vector__XXX
 SG_ RCM_a015_driverABStg2Open m15 : 18|1@1+ (1,0) [0|0] "" Vector__XXX
 SG_ RCM_a016_passABStg1Open m16 : 18|1@1+ (1,0) [0|0] "" Vector__XXX
 SG_ RCM_a017_passABStg2Open m17 : 18|1@1+ (1,0) [0|0] "" Vector__XXX
 SG_ RCM_a018_passActiveVentOpen m18 : 18|1@1+ (1,0) [0|0] "" Vector__XXX
 SG_ RCM_a019_pretenShldLeftOpen m19 : 18|1@1+ (1,0) [0|0] "" Vector__XXX
 SG_ RCM_a020_pretenShldRightOpen m20 : 18|1@1+ (1,0) [0|0] "" Vector__XXX
 SG_ RCM_a021_pretenLapLeftOpen m21 : 18|1@1+ (1,0) [0|0] "" Vector__XXX
 SG_ RCM_a022_pretenLapRightOpen m22 : 18|1@1+ (1,0) [0|0] "" Vector__XXX
 SG_ RCM_a023_loadLimLeftOpen m23 : 18|1@1+ (1,0) [0|0] "" Vector__XXX
 SG_ RCM_a024_loadLimRightOpen m24 : 18|1@1+ (1,0) [0|0] "" Vector__XXX
 SG_ RCM_a025_kneeABDrvrOpen m25 : 18|1@1+ (1,0) [0|0] "" Vector__XXX
 SG_ RCM_a026_kneeABPassOpen m26 : 18|1@1+ (1,0) [0|0] "" Vector__XXX
 SG_ RCM_a027_sideAB1stRowLOpen m27 : 18|1@1+ (1,0) [0|0] "" Vector__XXX
 SG_ RCM_a028_sideAB1stRowROpen m28 : 18|1@1+ (1,0) [0|0] "" Vector__XXX
 SG_ RCM_a029_driverABAVOpen m29 : 18|1@1+ (1,0) [0|0] "" Vector__XXX
 SG_ RCM_a030_farsideABOpen m30 : 18|1@1+ (1,0) [0|0] "" Vector__XXX
 SG_ RCM_a031_frntCentrABOpen m31 : 18|1@1+ (1,0) [0|0] "" Vector__XXX
 SG_ RCM_a032_curABLeftOpen m32 : 18|1@1+ (1,0) [0|0] "" Vector__XXX
 SG_ RCM_a033_curABRightOpen m33 : 18|1@1+ (1,0) [0|0] "" Vector__XXX
 SG_ RCM_a034_preten2ndRowLOpen m34 : 18|1@1+ (1,0) [0|0] "" Vector__XXX
 SG_ RCM_a035_preten2ndRowROpen m35 : 18|1@1+ (1,0) [0|0] "" Vector__XXX
 SG_ RCM_a036_curAB2ndRowLOpen m36 : 18|1@1+ (1,0) [0|0] "" Vector__XXX
 SG_ RCM_a037_curAB2ndRowROpen m37 : 18|1@1+ (1,0) [0|0] "" Vector__XXX
 SG_ RCM_a038_unused3 m38 : 18|1@1+ (1,0) [0|0] "" Vector__XXX
 SG_ RCM_a039_unused9 m39 : 18|1@1+ (1,0) [0|0] "" Vector__XXX
 SG_ RCM_a040_hoodActuatorROpen m40 : 18|1@1+ (1,0) [0|0] "" Vector__XXX
 SG_ RCM_a041_hoodActuatorLOpen m41 : 18|1@1+ (1,0) [0|0] "" Vector__XXX
 SG_ RCM_a042_ens1Config m42 : 18|1@1+ (1,0) [0|0] "" Vector__XXX
 SG_ RCM_a043_ens2Config m43 : 18|1@1+ (1,0) [0|0] "" Vector__XXX
 SG_ RCM_a044_upFrontSensorLCrossCoup m44 : 18|1@1+ (1,0) [0|0] "" Vector__XXX
 SG_ RCM_a045_upFrontSensorRCrossCoup m45 : 18|1@1+ (1,0) [0|0] "" Vector__XXX
 SG_ RCM_a046_sideAccelBPilLCLosCoup m46 : 18|1@1+ (1,0) [0|0] "" Vector__XXX
 SG_ RCM_a047_sideAccelBPilRCrossCoup m47 : 18|1@1+ (1,0) [0|0] "" Vector__XXX
 SG_ RCM_a048_sideAccelCPilLCrossCoup m48 : 18|1@1+ (1,0) [0|0] "" Vector__XXX
 SG_ RCM_a049_sideAccelCPilRCrossCoup m49 : 18|1@1+ (1,0) [0|0] "" Vector__XXX
 SG_ RCM_a050_upFrontSensorCCrossCoup m50 : 18|1@1+ (1,0) [0|0] "" Vector__XXX
 SG_ RCM_a051_presFrntLDoorOption m51 : 18|1@1+ (1,0) [0|0] "" Vector__XXX
 SG_ RCM_a052_presFrntRDoorOption m52 : 18|1@1+ (1,0) [0|0] "" Vector__XXX
 SG_ RCM_a053_presPedProLOption m53 : 18|1@1+ (1,0) [0|0] "" Vector__XXX
 SG_ RCM_a054_presPedProROption m54 : 18|1@1+ (1,0) [0|0] "" Vector__XXX
 SG_ RCM_a058_bucklHallLeftOpen m58 : 18|1@1+ (1,0) [0|0] "" Vector__XXX
 SG_ RCM_a059_bucklHallRightOpen m59 : 18|1@1+ (1,0) [0|0] "" Vector__XXX
 SG_ RCM_a060_seaTrkPosLeftOpen m60 : 18|1@1+ (1,0) [0|0] "" Vector__XXX
 SG_ RCM_a061_seaTrkPosRightOpen m61 : 18|1@1+ (1,0) [0|0] "" Vector__XXX
 SG_ RCM_a062_alrOpen m62 : 18|1@1+ (1,0) [0|0] "" Vector__XXX
 SG_ RCM_a063_sbsw2ndRowROpen m63 : 18|1@1+ (1,0) [0|0] "" Vector__XXX
 SG_ RCM_a064_hwcp1CrossCoup m64 : 18|1@1+ (1,0) [0|0] "" Vector__XXX
 SG_ RCM_a065_swDrvrOrientCrossCoup m65 : 18|1@1+ (1,0) [0|0] "" Vector__XXX
 SG_ RCM_a066_sbsw2ndRowLCrossCoup m66 : 18|1@1+ (1,0) [0|0] "" Vector__XXX
 SG_ RCM_a069_comChassisCANPH7Cntr m69 : 18|1@1+ (1,0) [0|0] "" Vector__XXX
 SG_ RCM_a070_comChassisCANPH8Cntr m70 : 18|1@1+ (1,0) [0|0] "" Vector__XXX
 SG_ RCM_a071_comChassisCANPH9Cntr m71 : 18|1@1+ (1,0) [0|0] "" Vector__XXX
 SG_ RCM_a072_comUnusedCntr m72 : 18|1@1+ (1,0) [0|0] "" Vector__XXX
 SG_ RCM_a073_comChassisCANPH4Cntr m73 : 18|1@1+ (1,0) [0|0] "" Vector__XXX
 SG_ RCM_a074_comChassisCANPH5Cntr m74 : 18|1@1+ (1,0) [0|0] "" Vector__XXX
 SG_ RCM_a075_comChassisCANPH6Cntr m75 : 18|1@1+ (1,0) [0|0] "" Vector__XXX
 SG_ RCM_a076_comEPBLStatusCntr m76 : 18|1@1+ (1,0) [0|0] "" Vector__XXX
 SG_ RCM_a077_comEPBRStatusCntr m77 : 18|1@1+ (1,0) [0|0] "" Vector__XXX
 SG_ RCM_a078_comOCS1PCntr m78 : 18|1@1+ (1,0) [0|0] "" Vector__XXX
 SG_ RCM_a079_comOCS1DCntr m79 : 18|1@1+ (1,0) [0|0] "" Vector__XXX
 SG_ RCM_a080_comGTWACSCntr m80 : 18|1@1+ (1,0) [0|0] "" Vector__XXX
 SG_ RCM_a081_comVCFRONTLVPrwCntr m81 : 18|1@1+ (1,0) [0|0] "" Vector__XXX
 SG_ RCM_a087_comUnusedCANSilent m87 : 18|1@1+ (1,0) [0|0] "" Vector__XXX
 SG_ RCM_a088_comChassisCANPH2Cntr m88 : 18|1@1+ (1,0) [0|0] "" Vector__XXX
 SG_ RCM_a089_comChassisCANPH3Cntr m89 : 18|1@1+ (1,0) [0|0] "" Vector__XXX
 SG_ RCM_a091_comEPAS3PsysStatusChkSm m91 : 18|1@1+ (1,0) [0|0] "" Vector__XXX
 SG_ RCM_a092_comDASSafetyFrontCntr m92 : 18|1@1+ (1,0) [0|0] "" Vector__XXX
 SG_ RCM_a093_comVCLEFTStatusCntr m93 : 18|1@1+ (1,0) [0|0] "" Vector__XXX
 SG_ RCM_a094_comVCRIGHTStatusCntr m94 : 18|1@1+ (1,0) [0|0] "" Vector__XXX
 SG_ RCM_a095_comESPstatusCntr m95 : 18|1@1+ (1,0) [0|0] "" Vector__XXX
 SG_ RCM_a096_comESPwheelSpeedsCntr m96 : 18|1@1+ (1,0) [0|0] "" Vector__XXX
 SG_ RCM_a097_comDIspeedCntr m97 : 18|1@1+ (1,0) [0|0] "" Vector__XXX
 SG_ RCM_a098_comDIchassisControlCntr m98 : 18|1@1+ (1,0) [0|0] "" Vector__XXX
 SG_ RCM_a099_comDItorqueCntr m99 : 18|1@1+ (1,0) [0|0] "" Vector__XXX
 SG_ RCM_a100_comDIsystemStatusCntr m100 : 18|1@1+ (1,0) [0|0] "" Vector__XXX
 SG_ RCM_a101_idfEnviMonitoringEvent m101 : 18|1@1+ (1,0) [0|0] "" Vector__XXX
 SG_ RCM_a102_imuYawR8OffCompPosFLDC m102 : 18|1@1+ (1,0) [0|0] "" Vector__XXX
 SG_ RCM_a103_imuPtchR8OffCompPosFLDC m103 : 18|1@1+ (1,0) [0|0] "" Vector__XXX
 SG_ RCM_a104_imuRollR8OffCompPosFLDC m104 : 18|1@1+ (1,0) [0|0] "" Vector__XXX
 SG_ RCM_a105_imuLongAOffCompPosFLDC m105 : 18|1@1+ (1,0) [0|0] "" Vector__XXX
 SG_ RCM_a106_imuLatAcOffCompPosFLDC m106 : 18|1@1+ (1,0) [0|0] "" Vector__XXX
 SG_ RCM_a107_imuVertAOffCompPosFLDC m107 : 18|1@1+ (1,0) [0|0] "" Vector__XXX
 SG_ RCM_a113_imuPitchR8ChnlMonitTmp m113 : 18|1@1+ (1,0) [0|0] "" Vector__XXX
 SG_ RCM_a114_imuRollR8ChnlMonitTmp m114 : 18|1@1+ (1,0) [0|0] "" Vector__XXX
 SG_ RCM_a000_crashDetectedRight m0 : 19|1@1+ (1,0) [0|0] "" Vector__XXX
 SG_ RCM_a001_nearDeployRight m1 : 19|1@1+ (1,0) [0|0] "" Vector__XXX
 SG_ RCM_a004_idleMode m4 : 19|1@1+ (1,0) [0|0] "" Vector__XXX
 SG_ RCM_a014_driverABStg1Short m14 : 19|1@1+ (1,0) [0|0] "" Vector__XXX
 SG_ RCM_a015_driverABStg2Short m15 : 19|1@1+ (1,0) [0|0] "" Vector__XXX
 SG_ RCM_a016_passABStg1Short m16 : 19|1@1+ (1,0) [0|0] "" Vector__XXX
 SG_ RCM_a017_passABStg2Short m17 : 19|1@1+ (1,0) [0|0] "" Vector__XXX
 SG_ RCM_a018_passActiveVentShort m18 : 19|1@1+ (1,0) [0|0] "" Vector__XXX
 SG_ RCM_a019_pretenShldLeftShort m19 : 19|1@1+ (1,0) [0|0] "" Vector__XXX
 SG_ RCM_a020_pretenShldRightShort m20 : 19|1@1+ (1,0) [0|0] "" Vector__XXX
 SG_ RCM_a021_pretenLapLeftShort m21 : 19|1@1+ (1,0) [0|0] "" Vector__XXX
 SG_ RCM_a022_pretenLapRightShort m22 : 19|1@1+ (1,0) [0|0] "" Vector__XXX
 SG_ RCM_a023_loadLimLeftShort m23 : 19|1@1+ (1,0) [0|0] "" Vector__XXX
 SG_ RCM_a024_loadLimRightShort m24 : 19|1@1+ (1,0) [0|0] "" Vector__XXX
 SG_ RCM_a025_kneeABDrvrShort m25 : 19|1@1+ (1,0) [0|0] "" Vector__XXX
 SG_ RCM_a026_kneeABPassShort m26 : 19|1@1+ (1,0) [0|0] "" Vector__XXX
 SG_ RCM_a027_sideAB1stRowLShort m27 : 19|1@1+ (1,0) [0|0] "" Vector__XXX
 SG_ RCM_a028_sideAB1stRowRShort m28 : 19|1@1+ (1,0) [0|0] "" Vector__XXX
 SG_ RCM_a029_driverABAVShort m29 : 19|1@1+ (1,0) [0|0] "" Vector__XXX
 SG_ RCM_a030_farsideABShort m30 : 19|1@1+ (1,0) [0|0] "" Vector__XXX
 SG_ RCM_a031_frntCentrABShort m31 : 19|1@1+ (1,0) [0|0] "" Vector__XXX
 SG_ RCM_a032_curABLeftShort m32 : 19|1@1+ (1,0) [0|0] "" Vector__XXX
 SG_ RCM_a033_curABRightShort m33 : 19|1@1+ (1,0) [0|0] "" Vector__XXX
 SG_ RCM_a034_preten2ndRowLShort m34 : 19|1@1+ (1,0) [0|0] "" Vector__XXX
 SG_ RCM_a035_preten2ndRowRShort m35 : 19|1@1+ (1,0) [0|0] "" Vector__XXX
 SG_ RCM_a036_curAB2ndRowLShort m36 : 19|1@1+ (1,0) [0|0] "" Vector__XXX
 SG_ RCM_a037_curAB2ndRowRShort m37 : 19|1@1+ (1,0) [0|0] "" Vector__XXX
 SG_ RCM_a038_unused4 m38 : 19|1@1+ (1,0) [0|0] "" Vector__XXX
 SG_ RCM_a039_unused10 m39 : 19|1@1+ (1,0) [0|0] "" Vector__XXX
 SG_ RCM_a040_hoodActuatorRShort m40 : 19|1@1+ (1,0) [0|0] "" Vector__XXX
 SG_ RCM_a041_hoodActuatorLShort m41 : 19|1@1+ (1,0) [0|0] "" Vector__XXX
 SG_ RCM_a044_upFrontSensorLComm m44 : 19|1@1+ (1,0) [0|0] "" Vector__XXX
 SG_ RCM_a045_upFrontSensorRComm m45 : 19|1@1+ (1,0) [0|0] "" Vector__XXX
 SG_ RCM_a046_sideAccelBPilLComm m46 : 19|1@1+ (1,0) [0|0] "" Vector__XXX
 SG_ RCM_a047_sideAccelBPilRComm m47 : 19|1@1+ (1,0) [0|0] "" Vector__XXX
 SG_ RCM_a048_sideAccelCPilLComm m48 : 19|1@1+ (1,0) [0|0] "" Vector__XXX
 SG_ RCM_a049_sideAccelCPilRComm m49 : 19|1@1+ (1,0) [0|0] "" Vector__XXX
 SG_ RCM_a050_upFrontSensorCComm m50 : 19|1@1+ (1,0) [0|0] "" Vector__XXX
 SG_ RCM_a051_presFrntLDoorPlaus m51 : 19|1@1+ (1,0) [0|0] "" Vector__XXX
 SG_ RCM_a052_presFrntRDoorPlaus m52 : 19|1@1+ (1,0) [0|0] "" Vector__XXX
 SG_ RCM_a053_presPedProLPlaus m53 : 19|1@1+ (1,0) [0|0] "" Vector__XXX
 SG_ RCM_a054_presPedProRPlaus m54 : 19|1@1+ (1,0) [0|0] "" Vector__XXX
 SG_ RCM_a058_bucklHallLeftUndef m58 : 19|1@1+ (1,0) [0|0] "" Vector__XXX
 SG_ RCM_a059_bucklHallRightUndef m59 : 19|1@1+ (1,0) [0|0] "" Vector__XXX
 SG_ RCM_a060_seaTrkPosLeftUndefined m60 : 19|1@1+ (1,0) [0|0] "" Vector__XXX
 SG_ RCM_a061_seaTrkPosRightUndefined m61 : 19|1@1+ (1,0) [0|0] "" Vector__XXX
 SG_ RCM_a062_alrUndefined m62 : 19|1@1+ (1,0) [0|0] "" Vector__XXX
 SG_ RCM_a063_sbsw2ndRowRUndefined m63 : 19|1@1+ (1,0) [0|0] "" Vector__XXX
 SG_ RCM_a064_hwcp1Config m64 : 19|1@1+ (1,0) [0|0] "" Vector__XXX
 SG_ RCM_a065_swDrvrOrientConfig m65 : 19|1@1+ (1,0) [0|0] "" Vector__XXX
 SG_ RCM_a066_sbsw2ndRowLConfig m66 : 19|1@1+ (1,0) [0|0] "" Vector__XXX
 SG_ RCM_a091_comEPAS3PsysStatusCntr m91 : 19|1@1+ (1,0) [0|0] "" Vector__XXX
 SG_ RCM_a093_bucklSwVCFrontLeftFault m93 : 19|1@1+ (1,0) [0|0] "" Vector__XXX
 SG_ RCM_a094_bucklSwVCFrontRghtFault m94 : 19|1@1+ (1,0) [0|0] "" Vector__XXX
 SG_ RCM_a102_imuYawR8OffCompNegFLDC m102 : 19|1@1+ (1,0) [0|0] "" Vector__XXX
 SG_ RCM_a103_imuPtchR8OffCompNegFLDC m103 : 19|1@1+ (1,0) [0|0] "" Vector__XXX
 SG_ RCM_a104_imuRollR8OffCompNegFLDC m104 : 19|1@1+ (1,0) [0|0] "" Vector__XXX
 SG_ RCM_a105_imuLongAOffCompNegFLDC m105 : 19|1@1+ (1,0) [0|0] "" Vector__XXX
 SG_ RCM_a106_imuLatAcOffCompNegFLDC m106 : 19|1@1+ (1,0) [0|0] "" Vector__XXX
 SG_ RCM_a107_imuVertAOffCompNegFLDC m107 : 19|1@1+ (1,0) [0|0] "" Vector__XXX
 SG_ RCM_a112_imuYawR8ChnlMonitTmp m112 : 19|1@1+ (1,0) [0|0] "" Vector__XXX
 SG_ RCM_a113_imuPitchR8ChnlMonitPerm m113 : 19|1@1+ (1,0) [0|0] "" Vector__XXX
 SG_ RCM_a114_imuRollR8ChnlMonitPerm m114 : 19|1@1+ (1,0) [0|0] "" Vector__XXX
 SG_ RCM_a000_crashDetectedRoll m0 : 20|1@1+ (1,0) [0|0] "" Vector__XXX
 SG_ RCM_a001_nearDeployRoll m1 : 20|1@1+ (1,0) [0|0] "" Vector__XXX
 SG_ RCM_a004_internalFaultDetected m4 : 20|1@1+ (1,0) [0|0] "" Vector__XXX
 SG_ RCM_a014_driverABStg1CrossCoup m14 : 20|1@1+ (1,0) [0|0] "" Vector__XXX
 SG_ RCM_a015_driverABStg2CrossCoup m15 : 20|1@1+ (1,0) [0|0] "" Vector__XXX
 SG_ RCM_a016_passABStg1CrossCoup m16 : 20|1@1+ (1,0) [0|0] "" Vector__XXX
 SG_ RCM_a017_passABStg2CrossCoup m17 : 20|1@1+ (1,0) [0|0] "" Vector__XXX
 SG_ RCM_a018_passActiveVentCrossCoup m18 : 20|1@1+ (1,0) [0|0] "" Vector__XXX
 SG_ RCM_a019_pretenShldLeftCrossC m19 : 20|1@1+ (1,0) [0|0] "" Vector__XXX
 SG_ RCM_a020_pretenShldRightCrossC m20 : 20|1@1+ (1,0) [0|0] "" Vector__XXX
 SG_ RCM_a021_pretenLapLeftCrossCoup m21 : 20|1@1+ (1,0) [0|0] "" Vector__XXX
 SG_ RCM_a022_pretenLapRightCrossCoup m22 : 20|1@1+ (1,0) [0|0] "" Vector__XXX
 SG_ RCM_a023_loadLimLeftCrossCoup m23 : 20|1@1+ (1,0) [0|0] "" Vector__XXX
 SG_ RCM_a024_loadLimRightCrossCoup m24 : 20|1@1+ (1,0) [0|0] "" Vector__XXX
 SG_ RCM_a025_kneeABDrvrCrossCoup m25 : 20|1@1+ (1,0) [0|0] "" Vector__XXX
 SG_ RCM_a026_kneeABPassCrossCoup m26 : 20|1@1+ (1,0) [0|0] "" Vector__XXX
 SG_ RCM_a027_sideAB1stRowLCrossCoup m27 : 20|1@1+ (1,0) [0|0] "" Vector__XXX
 SG_ RCM_a028_sideAB1stRowRCrossCoup m28 : 20|1@1+ (1,0) [0|0] "" Vector__XXX
 SG_ RCM_a029_driverABAVCrossCoup m29 : 20|1@1+ (1,0) [0|0] "" Vector__XXX
 SG_ RCM_a030_farsideABCrossCoup m30 : 20|1@1+ (1,0) [0|0] "" Vector__XXX
 SG_ RCM_a031_frntCentrABCrossCoup m31 : 20|1@1+ (1,0) [0|0] "" Vector__XXX
 SG_ RCM_a032_curABLeftCrossCoup m32 : 20|1@1+ (1,0) [0|0] "" Vector__XXX
 SG_ RCM_a033_curABRightCrossCoup m33 : 20|1@1+ (1,0) [0|0] "" Vector__XXX
 SG_ RCM_a034_preten2ndRowLCrossCoup m34 : 20|1@1+ (1,0) [0|0] "" Vector__XXX
 SG_ RCM_a035_preten2ndRowRCrossCoup m35 : 20|1@1+ (1,0) [0|0] "" Vector__XXX
 SG_ RCM_a036_curAB2ndRowLCrossCoup m36 : 20|1@1+ (1,0) [0|0] "" Vector__XXX
 SG_ RCM_a037_curAB2ndRowRCrossCoup m37 : 20|1@1+ (1,0) [0|0] "" Vector__XXX
 SG_ RCM_a038_unused5 m38 : 20|1@1+ (1,0) [0|0] "" Vector__XXX
 SG_ RCM_a039_unused11 m39 : 20|1@1+ (1,0) [0|0] "" Vector__XXX
 SG_ RCM_a040_hoodActuatorRCrossCoup m40 : 20|1@1+ (1,0) [0|0] "" Vector__XXX
 SG_ RCM_a041_hoodActuatorLCrossCoup m41 : 20|1@1+ (1,0) [0|0] "" Vector__XXX
 SG_ RCM_a044_upFrontSensorLInitTyp m44 : 20|1@1+ (1,0) [0|0] "" Vector__XXX
 SG_ RCM_a045_upFrontSensorRInitTyp m45 : 20|1@1+ (1,0) [0|0] "" Vector__XXX
 SG_ RCM_a046_sideAccelBPilLInitTyp m46 : 20|1@1+ (1,0) [0|0] "" Vector__XXX
 SG_ RCM_a047_sideAccelBPilRInitTyp m47 : 20|1@1+ (1,0) [0|0] "" Vector__XXX
 SG_ RCM_a048_sideAccelCPilLInitTyp m48 : 20|1@1+ (1,0) [0|0] "" Vector__XXX
 SG_ RCM_a049_sideAccelCPilRInitTyp m49 : 20|1@1+ (1,0) [0|0] "" Vector__XXX
 SG_ RCM_a050_upFrontSensorCInitTyp m50 : 20|1@1+ (1,0) [0|0] "" Vector__XXX
 SG_ RCM_a051_presFrntLDoorAbsPre m51 : 20|1@1+ (1,0) [0|0] "" Vector__XXX
 SG_ RCM_a052_presFrntRDoorAbsPre m52 : 20|1@1+ (1,0) [0|0] "" Vector__XXX
 SG_ RCM_a053_presPedProLAbsPre m53 : 20|1@1+ (1,0) [0|0] "" Vector__XXX
 SG_ RCM_a054_presPedProRAbsPre m54 : 20|1@1+ (1,0) [0|0] "" Vector__XXX
 SG_ RCM_a058_bucklHallLeftCrossCoup m58 : 20|1@1+ (1,0) [0|0] "" Vector__XXX
 SG_ RCM_a059_bucklHallRightCrossCoup m59 : 20|1@1+ (1,0) [0|0] "" Vector__XXX
 SG_ RCM_a060_seaTrkPosLeftCrossCoup m60 : 20|1@1+ (1,0) [0|0] "" Vector__XXX
 SG_ RCM_a061_seaTrkPosRightCrossCoup m61 : 20|1@1+ (1,0) [0|0] "" Vector__XXX
 SG_ RCM_a062_alrCrossCoup m62 : 20|1@1+ (1,0) [0|0] "" Vector__XXX
 SG_ RCM_a063_sbsw2ndRowRCrossCoup m63 : 20|1@1+ (1,0) [0|0] "" Vector__XXX
 SG_ RCM_a093_bucklSwVCRearLeftFault m93 : 20|1@1+ (1,0) [0|0] "" Vector__XXX
 SG_ RCM_a094_bucklSwVCRearRghtFault m94 : 20|1@1+ (1,0) [0|0] "" Vector__XXX
 SG_ RCM_a102_imuYawR8OffCompPosSLDC m102 : 20|1@1+ (1,0) [0|0] "" Vector__XXX
 SG_ RCM_a103_imuPtchR8OffCompPosSLDC m103 : 20|1@1+ (1,0) [0|0] "" Vector__XXX
 SG_ RCM_a104_imuRollR8OffCompPosSLDC m104 : 20|1@1+ (1,0) [0|0] "" Vector__XXX
 SG_ RCM_a105_imuLongAOffCompPosSLDC m105 : 20|1@1+ (1,0) [0|0] "" Vector__XXX
 SG_ RCM_a106_imuLatAcOffCompPosSLDC m106 : 20|1@1+ (1,0) [0|0] "" Vector__XXX
 SG_ RCM_a107_imuVertAOffCompPosSLDC m107 : 20|1@1+ (1,0) [0|0] "" Vector__XXX
 SG_ RCM_a112_imuYawR8ChnlMonitPerm m112 : 20|1@1+ (1,0) [0|0] "" Vector__XXX
 SG_ RCM_a000_crashDetectedPreten m0 : 21|1@1+ (1,0) [0|0] "" Vector__XXX
 SG_ RCM_a001_nearDeployPretensioner m1 : 21|1@1+ (1,0) [0|0] "" Vector__XXX
 SG_ RCM_a004_swVersionMismatch m4 : 21|1@1+ (1,0) [0|0] "" Vector__XXX
 SG_ RCM_a014_driverABStg1Config m14 : 21|1@1+ (1,0) [0|0] "" Vector__XXX
 SG_ RCM_a015_driverABStg2Config m15 : 21|1@1+ (1,0) [0|0] "" Vector__XXX
 SG_ RCM_a016_passABStg1Config m16 : 21|1@1+ (1,0) [0|0] "" Vector__XXX
 SG_ RCM_a017_passABStg2Config m17 : 21|1@1+ (1,0) [0|0] "" Vector__XXX
 SG_ RCM_a018_passActiveVentConfig m18 : 21|1@1+ (1,0) [0|0] "" Vector__XXX
 SG_ RCM_a019_pretenShldLeftConfig m19 : 21|1@1+ (1,0) [0|0] "" Vector__XXX
 SG_ RCM_a020_pretenShldRightConfig m20 : 21|1@1+ (1,0) [0|0] "" Vector__XXX
 SG_ RCM_a021_pretenLapLeftConfig m21 : 21|1@1+ (1,0) [0|0] "" Vector__XXX
 SG_ RCM_a022_pretenLapRightConfig m22 : 21|1@1+ (1,0) [0|0] "" Vector__XXX
 SG_ RCM_a023_loadLimLeftConfig m23 : 21|1@1+ (1,0) [0|0] "" Vector__XXX
 SG_ RCM_a024_loadLimRightConfig m24 : 21|1@1+ (1,0) [0|0] "" Vector__XXX
 SG_ RCM_a025_kneeABDrvrConfig m25 : 21|1@1+ (1,0) [0|0] "" Vector__XXX
 SG_ RCM_a026_kneeABPassConfig m26 : 21|1@1+ (1,0) [0|0] "" Vector__XXX
 SG_ RCM_a027_sideAB1stRowLConfig m27 : 21|1@1+ (1,0) [0|0] "" Vector__XXX
 SG_ RCM_a028_sideAB1stRowRConfig m28 : 21|1@1+ (1,0) [0|0] "" Vector__XXX
 SG_ RCM_a029_driverABAVConfig m29 : 21|1@1+ (1,0) [0|0] "" Vector__XXX
 SG_ RCM_a030_farsideABConfig m30 : 21|1@1+ (1,0) [0|0] "" Vector__XXX
 SG_ RCM_a031_frntCentrABConfig m31 : 21|1@1+ (1,0) [0|0] "" Vector__XXX
 SG_ RCM_a032_curABLeftConfig m32 : 21|1@1+ (1,0) [0|0] "" Vector__XXX
 SG_ RCM_a033_curABRightConfig m33 : 21|1@1+ (1,0) [0|0] "" Vector__XXX
 SG_ RCM_a034_preten2ndRowLCgf m34 : 21|1@1+ (1,0) [0|0] "" Vector__XXX
 SG_ RCM_a035_preten2ndRowRCgf m35 : 21|1@1+ (1,0) [0|0] "" Vector__XXX
 SG_ RCM_a036_curAB2ndRowLConfig m36 : 21|1@1+ (1,0) [0|0] "" Vector__XXX
 SG_ RCM_a037_curAB2ndRowRConfig m37 : 21|1@1+ (1,0) [0|0] "" Vector__XXX
 SG_ RCM_a038_unused6 m38 : 21|1@1+ (1,0) [0|0] "" Vector__XXX
 SG_ RCM_a039_unused12 m39 : 21|1@1+ (1,0) [0|0] "" Vector__XXX
 SG_ RCM_a040_hoodActuatorRConfig m40 : 21|1@1+ (1,0) [0|0] "" Vector__XXX
 SG_ RCM_a041_hoodActuatorLConfig m41 : 21|1@1+ (1,0) [0|0] "" Vector__XXX
 SG_ RCM_a044_upFrontSensorLOption m44 : 21|1@1+ (1,0) [0|0] "" Vector__XXX
 SG_ RCM_a045_upFrontSensorROption m45 : 21|1@1+ (1,0) [0|0] "" Vector__XXX
 SG_ RCM_a046_sideAccelBPilLOption m46 : 21|1@1+ (1,0) [0|0] "" Vector__XXX
 SG_ RCM_a047_sideAccelBPilROption m47 : 21|1@1+ (1,0) [0|0] "" Vector__XXX
 SG_ RCM_a048_sideAccelCPilLOption m48 : 21|1@1+ (1,0) [0|0] "" Vector__XXX
 SG_ RCM_a049_sideAccelCPilROption m49 : 21|1@1+ (1,0) [0|0] "" Vector__XXX
 SG_ RCM_a050_upFrontSensorCOption m50 : 21|1@1+ (1,0) [0|0] "" Vector__XXX
 SG_ RCM_a051_presFrntLDoorDefect m51 : 21|1@1+ (1,0) [0|0] "" Vector__XXX
 SG_ RCM_a052_presFrntRDoorDefect m52 : 21|1@1+ (1,0) [0|0] "" Vector__XXX
 SG_ RCM_a053_presPedProLDefect m53 : 21|1@1+ (1,0) [0|0] "" Vector__XXX
 SG_ RCM_a054_presPedProRDefect m54 : 21|1@1+ (1,0) [0|0] "" Vector__XXX
 SG_ RCM_a058_bucklHallLeftConfig m58 : 21|1@1+ (1,0) [0|0] "" Vector__XXX
 SG_ RCM_a059_bucklSwRightConfig m59 : 21|1@1+ (1,0) [0|0] "" Vector__XXX
 SG_ RCM_a060_seaTrkPosLeftConfig m60 : 21|1@1+ (1,0) [0|0] "" Vector__XXX
 SG_ RCM_a061_seaTrkPosRightConfig m61 : 21|1@1+ (1,0) [0|0] "" Vector__XXX
 SG_ RCM_a062_alrConfig m62 : 21|1@1+ (1,0) [0|0] "" Vector__XXX
 SG_ RCM_a063_sbsw2ndRowRConfig m63 : 21|1@1+ (1,0) [0|0] "" Vector__XXX
 SG_ RCM_a094_bucklSwVCRearCnterFault m94 : 21|1@1+ (1,0) [0|0] "" Vector__XXX
 SG_ RCM_a102_imuYawR8OffCompNegSLDC m102 : 21|1@1+ (1,0) [0|0] "" Vector__XXX
 SG_ RCM_a103_imuPtchR8OffCompNegSLDC m103 : 21|1@1+ (1,0) [0|0] "" Vector__XXX
 SG_ RCM_a104_imuRollR8OffCompNegSLDC m104 : 21|1@1+ (1,0) [0|0] "" Vector__XXX
 SG_ RCM_a105_imuLongAOffCompNegSLDC m105 : 21|1@1+ (1,0) [0|0] "" Vector__XXX
 SG_ RCM_a106_imuLatAcOffCompNegSLDC m106 : 21|1@1+ (1,0) [0|0] "" Vector__XXX
 SG_ RCM_a107_imuVertAOffCompNegSLDC m107 : 21|1@1+ (1,0) [0|0] "" Vector__XXX
 SG_ RCM_a000_crashDetectedStage1 m0 : 22|1@1+ (1,0) [0|0] "" Vector__XXX
 SG_ RCM_a004_paramLayoutIDInv m4 : 22|1@1+ (1,0) [0|0] "" Vector__XXX
 SG_ RCM_a044_upFrontSensorLplaus m44 : 22|1@1+ (1,0) [0|0] "" Vector__XXX
 SG_ RCM_a045_upFrontSensorRplaus m45 : 22|1@1+ (1,0) [0|0] "" Vector__XXX
 SG_ RCM_a046_sideAccelBPilLplaus m46 : 22|1@1+ (1,0) [0|0] "" Vector__XXX
 SG_ RCM_a047_sideAccelBPilRplaus m47 : 22|1@1+ (1,0) [0|0] "" Vector__XXX
 SG_ RCM_a048_sideAccelCPilLplaus m48 : 22|1@1+ (1,0) [0|0] "" Vector__XXX
 SG_ RCM_a049_sideAccelCPilRplaus m49 : 22|1@1+ (1,0) [0|0] "" Vector__XXX
 SG_ RCM_a050_upFrontSensorCplaus m50 : 22|1@1+ (1,0) [0|0] "" Vector__XXX
 SG_ RCM_a051_presFrntLDoorSht2Gnd m51 : 22|1@1+ (1,0) [0|0] "" Vector__XXX
 SG_ RCM_a052_presFrntRDoorSht2Gnd m52 : 22|1@1+ (1,0) [0|0] "" Vector__XXX
 SG_ RCM_a053_presPedProLSht2Gnd m53 : 22|1@1+ (1,0) [0|0] "" Vector__XXX
 SG_ RCM_a054_presPedProRSht2Gnd m54 : 22|1@1+ (1,0) [0|0] "" Vector__XXX
 SG_ RCM_a000_crashDetectedStage2 m0 : 23|1@1+ (1,0) [0|0] "" Vector__XXX
 SG_ RCM_a004_algoPASIDMismatch m4 : 23|1@1+ (1,0) [0|0] "" Vector__XXX
 SG_ RCM_a044_upFrontSensorLDefect m44 : 23|1@1+ (1,0) [0|0] "" Vector__XXX
 SG_ RCM_a045_upFrontSensorRDefect m45 : 23|1@1+ (1,0) [0|0] "" Vector__XXX
 SG_ RCM_a046_sideAccelBPilLDefect m46 : 23|1@1+ (1,0) [0|0] "" Vector__XXX
 SG_ RCM_a047_sideAccelBPilRDefect m47 : 23|1@1+ (1,0) [0|0] "" Vector__XXX
 SG_ RCM_a048_sideAccelCPilLDefect m48 : 23|1@1+ (1,0) [0|0] "" Vector__XXX
 SG_ RCM_a049_sideAccelCPilRDefect m49 : 23|1@1+ (1,0) [0|0] "" Vector__XXX
 SG_ RCM_a050_upFrontSensorCDefect m50 : 23|1@1+ (1,0) [0|0] "" Vector__XXX
 SG_ RCM_a051_presFrntLDoorSht2Bat m51 : 23|1@1+ (1,0) [0|0] "" Vector__XXX
 SG_ RCM_a052_presFrntRDoorSht2Bat m52 : 23|1@1+ (1,0) [0|0] "" Vector__XXX
 SG_ RCM_a053_presPedProLSht2Bat m53 : 23|1@1+ (1,0) [0|0] "" Vector__XXX
 SG_ RCM_a054_presPedProRSht2Bat m54 : 23|1@1+ (1,0) [0|0] "" Vector__XXX
 SG_ RCM_a000_crashDetectedHVpyro m0 : 24|1@1+ (1,0) [0|0] "" Vector__XXX
 SG_ RCM_a051_presFrntLDoorCrossCoup m51 : 24|1@1+ (1,0) [0|0] "" Vector__XXX
 SG_ RCM_a052_presFrntRDoorCrossCoup m52 : 24|1@1+ (1,0) [0|0] "" Vector__XXX
 SG_ RCM_a053_presPedProLCrossCoup m53 : 24|1@1+ (1,0) [0|0] "" Vector__XXX
 SG_ RCM_a054_presPedProRCrossCoup m54 : 24|1@1+ (1,0) [0|0] "" Vector__XXX
 SG_ RCM_a000_eventIDFsignal m0 : 25|1@1+ (1,0) [0|0] "" Vector__XXX
 SG_ RCM_a001_eventIDFsignal m1 : 25|1@1+ (1,0) [0|0] "" Vector__XXX
 SG_ RCM_a002_eventIDFsignal m2 : 25|1@1+ (1,0) [0|0] "" Vector__XXX
 SG_ RCM_a003_eventIDFsignal m3 : 25|1@1+ (1,0) [0|0] "" Vector__XXX
 SG_ RCM_a004_eventIDFsignal m4 : 25|1@1+ (1,0) [0|0] "" Vector__XXX
 SG_ RCM_a005_eventIDFsignal m5 : 25|1@1+ (1,0) [0|0] "" Vector__XXX
 SG_ RCM_a006_eventIDFsignal m6 : 25|1@1+ (1,0) [0|0] "" Vector__XXX
 SG_ RCM_a007_eventIDFsignal m7 : 25|1@1+ (1,0) [0|0] "" Vector__XXX
 SG_ RCM_a008_eventIDFsignal m8 : 25|1@1+ (1,0) [0|0] "" Vector__XXX
 SG_ RCM_a009_eventIDFsignal m9 : 25|1@1+ (1,0) [0|0] "" Vector__XXX
 SG_ RCM_a010_eventIDFsignal m10 : 25|1@1+ (1,0) [0|0] "" Vector__XXX
 SG_ RCM_a011_eventIDFsignal m11 : 25|1@1+ (1,0) [0|0] "" Vector__XXX
 SG_ RCM_a012_eventIDFsignal m12 : 25|1@1+ (1,0) [0|0] "" Vector__XXX
 SG_ RCM_a013_eventIDFsignal m13 : 25|1@1+ (1,0) [0|0] "" Vector__XXX
 SG_ RCM_a014_eventIDFsignal m14 : 25|1@1+ (1,0) [0|0] "" Vector__XXX
 SG_ RCM_a015_eventIDFsignal m15 : 25|1@1+ (1,0) [0|0] "" Vector__XXX
 SG_ RCM_a016_eventIDFsignal m16 : 25|1@1+ (1,0) [0|0] "" Vector__XXX
 SG_ RCM_a017_eventIDFsignal m17 : 25|1@1+ (1,0) [0|0] "" Vector__XXX
 SG_ RCM_a018_eventIDFsignal m18 : 25|1@1+ (1,0) [0|0] "" Vector__XXX
 SG_ RCM_a019_eventIDFsignal m19 : 25|1@1+ (1,0) [0|0] "" Vector__XXX
 SG_ RCM_a020_eventIDFsignal m20 : 25|1@1+ (1,0) [0|0] "" Vector__XXX
 SG_ RCM_a021_eventIDFsignal m21 : 25|1@1+ (1,0) [0|0] "" Vector__XXX
 SG_ RCM_a022_eventIDFsignal m22 : 25|1@1+ (1,0) [0|0] "" Vector__XXX
 SG_ RCM_a023_eventIDFsignal m23 : 25|1@1+ (1,0) [0|0] "" Vector__XXX
 SG_ RCM_a024_eventIDFsignal m24 : 25|1@1+ (1,0) [0|0] "" Vector__XXX
 SG_ RCM_a025_eventIDFsignal m25 : 25|1@1+ (1,0) [0|0] "" Vector__XXX
 SG_ RCM_a026_eventIDFsignal m26 : 25|1@1+ (1,0) [0|0] "" Vector__XXX
 SG_ RCM_a027_eventIDFsignal m27 : 25|1@1+ (1,0) [0|0] "" Vector__XXX
 SG_ RCM_a028_eventIDFsignal m28 : 25|1@1+ (1,0) [0|0] "" Vector__XXX
 SG_ RCM_a029_eventIDFsignal m29 : 25|1@1+ (1,0) [0|0] "" Vector__XXX
 SG_ RCM_a030_eventIDFsignal m30 : 25|1@1+ (1,0) [0|0] "" Vector__XXX
 SG_ RCM_a031_eventIDFsignal m31 : 25|1@1+ (1,0) [0|0] "" Vector__XXX
 SG_ RCM_a032_eventIDFsignal m32 : 25|1@1+ (1,0) [0|0] "" Vector__XXX
 SG_ RCM_a033_eventIDFsignal m33 : 25|1@1+ (1,0) [0|0] "" Vector__XXX
 SG_ RCM_a034_eventIDFsignal m34 : 25|1@1+ (1,0) [0|0] "" Vector__XXX
 SG_ RCM_a035_eventIDFsignal m35 : 25|1@1+ (1,0) [0|0] "" Vector__XXX
 SG_ RCM_a036_eventIDFsignal m36 : 25|1@1+ (1,0) [0|0] "" Vector__XXX
 SG_ RCM_a037_eventIDFsignal m37 : 25|1@1+ (1,0) [0|0] "" Vector__XXX
 SG_ RCM_a038_eventIDFsignal m38 : 25|1@1+ (1,0) [0|0] "" Vector__XXX
 SG_ RCM_a039_eventIDFsignal m39 : 25|1@1+ (1,0) [0|0] "" Vector__XXX
 SG_ RCM_a040_eventIDFsignal m40 : 25|1@1+ (1,0) [0|0] "" Vector__XXX
 SG_ RCM_a041_eventIDFsignal m41 : 25|1@1+ (1,0) [0|0] "" Vector__XXX
 SG_ RCM_a042_eventIDFsignal m42 : 25|1@1+ (1,0) [0|0] "" Vector__XXX
 SG_ RCM_a043_eventIDFsignal m43 : 25|1@1+ (1,0) [0|0] "" Vector__XXX
 SG_ RCM_a044_eventIDFsignal m44 : 25|1@1+ (1,0) [0|0] "" Vector__XXX
 SG_ RCM_a045_eventIDFsignal m45 : 25|1@1+ (1,0) [0|0] "" Vector__XXX
 SG_ RCM_a046_eventIDFsignal m46 : 25|1@1+ (1,0) [0|0] "" Vector__XXX
 SG_ RCM_a047_eventIDFsignal m47 : 25|1@1+ (1,0) [0|0] "" Vector__XXX
 SG_ RCM_a048_eventIDFsignal m48 : 25|1@1+ (1,0) [0|0] "" Vector__XXX
 SG_ RCM_a049_eventIDFsignal m49 : 25|1@1+ (1,0) [0|0] "" Vector__XXX
 SG_ RCM_a050_eventIDFsignal m50 : 25|1@1+ (1,0) [0|0] "" Vector__XXX
 SG_ RCM_a051_eventIDFsignal m51 : 25|1@1+ (1,0) [0|0] "" Vector__XXX
 SG_ RCM_a052_eventIDFsignal m52 : 25|1@1+ (1,0) [0|0] "" Vector__XXX
 SG_ RCM_a053_eventIDFsignal m53 : 25|1@1+ (1,0) [0|0] "" Vector__XXX
 SG_ RCM_a054_eventIDFsignal m54 : 25|1@1+ (1,0) [0|0] "" Vector__XXX
 SG_ RCM_a055_eventIDFsignal m55 : 25|1@1+ (1,0) [0|0] "" Vector__XXX
 SG_ RCM_a056_eventIDFsignal m56 : 25|1@1+ (1,0) [0|0] "" Vector__XXX
 SG_ RCM_a057_eventIDFsignal m57 : 25|1@1+ (1,0) [0|0] "" Vector__XXX
 SG_ RCM_a058_eventIDFsignal m58 : 25|1@1+ (1,0) [0|0] "" Vector__XXX
 SG_ RCM_a059_eventIDFsignal m59 : 25|1@1+ (1,0) [0|0] "" Vector__XXX
 SG_ RCM_a060_eventIDFsignal m60 : 25|1@1+ (1,0) [0|0] "" Vector__XXX
 SG_ RCM_a061_eventIDFsignal m61 : 25|1@1+ (1,0) [0|0] "" Vector__XXX
 SG_ RCM_a062_eventIDFsignal m62 : 25|1@1+ (1,0) [0|0] "" Vector__XXX
 SG_ RCM_a063_eventIDFsignal m63 : 25|1@1+ (1,0) [0|0] "" Vector__XXX
 SG_ RCM_a064_eventIDFsignal m64 : 25|1@1+ (1,0) [0|0] "" Vector__XXX
 SG_ RCM_a065_eventIDFsignal m65 : 25|1@1+ (1,0) [0|0] "" Vector__XXX
 SG_ RCM_a066_eventIDFsignal m66 : 25|1@1+ (1,0) [0|0] "" Vector__XXX
 SG_ RCM_a067_eventIDFsignal m67 : 25|1@1+ (1,0) [0|0] "" Vector__XXX
 SG_ RCM_a068_eventIDFsignal m68 : 25|1@1+ (1,0) [0|0] "" Vector__XXX
 SG_ RCM_a069_eventIDFsignal m69 : 25|1@1+ (1,0) [0|0] "" Vector__XXX
 SG_ RCM_a070_eventIDFsignal m70 : 25|1@1+ (1,0) [0|0] "" Vector__XXX
 SG_ RCM_a071_eventIDFsignal m71 : 25|1@1+ (1,0) [0|0] "" Vector__XXX
 SG_ RCM_a072_eventIDFsignal m72 : 25|1@1+ (1,0) [0|0] "" Vector__XXX
 SG_ RCM_a073_eventIDFsignal m73 : 25|1@1+ (1,0) [0|0] "" Vector__XXX
 SG_ RCM_a074_eventIDFsignal m74 : 25|1@1+ (1,0) [0|0] "" Vector__XXX
 SG_ RCM_a075_eventIDFsignal m75 : 25|1@1+ (1,0) [0|0] "" Vector__XXX
 SG_ RCM_a076_eventIDFsignal m76 : 25|1@1+ (1,0) [0|0] "" Vector__XXX
 SG_ RCM_a077_eventIDFsignal m77 : 25|1@1+ (1,0) [0|0] "" Vector__XXX
 SG_ RCM_a078_eventIDFsignal m78 : 25|1@1+ (1,0) [0|0] "" Vector__XXX
 SG_ RCM_a079_eventIDFsignal m79 : 25|1@1+ (1,0) [0|0] "" Vector__XXX
 SG_ RCM_a080_eventIDFsignal m80 : 25|1@1+ (1,0) [0|0] "" Vector__XXX
 SG_ RCM_a081_eventIDFsignal m81 : 25|1@1+ (1,0) [0|0] "" Vector__XXX
 SG_ RCM_a082_eventIDFsignal m82 : 25|1@1+ (1,0) [0|0] "" Vector__XXX
 SG_ RCM_a083_eventIDFsignal m83 : 25|1@1+ (1,0) [0|0] "" Vector__XXX
 SG_ RCM_a084_eventIDFsignal m84 : 25|1@1+ (1,0) [0|0] "" Vector__XXX
 SG_ RCM_a085_eventIDFsignal m85 : 25|1@1+ (1,0) [0|0] "" Vector__XXX
 SG_ RCM_a086_eventIDFsignal m86 : 25|1@1+ (1,0) [0|0] "" Vector__XXX
 SG_ RCM_a087_eventIDFsignal m87 : 25|1@1+ (1,0) [0|0] "" Vector__XXX
 SG_ RCM_a088_eventIDFsignal m88 : 25|1@1+ (1,0) [0|0] "" Vector__XXX
 SG_ RCM_a089_eventIDFsignal m89 : 25|1@1+ (1,0) [0|0] "" Vector__XXX
 SG_ RCM_a090_eventIDFsignal m90 : 25|1@1+ (1,0) [0|0] "" Vector__XXX
 SG_ RCM_a091_eventIDFsignal m91 : 25|1@1+ (1,0) [0|0] "" Vector__XXX
 SG_ RCM_a092_eventIDFsignal m92 : 25|1@1+ (1,0) [0|0] "" Vector__XXX
 SG_ RCM_a093_eventIDFsignal m93 : 25|1@1+ (1,0) [0|0] "" Vector__XXX
 SG_ RCM_a094_eventIDFsignal m94 : 25|1@1+ (1,0) [0|0] "" Vector__XXX
 SG_ RCM_a095_eventIDFsignal m95 : 25|1@1+ (1,0) [0|0] "" Vector__XXX
 SG_ RCM_a096_eventIDFsignal m96 : 25|1@1+ (1,0) [0|0] "" Vector__XXX
 SG_ RCM_a097_eventIDFsignal m97 : 25|1@1+ (1,0) [0|0] "" Vector__XXX
 SG_ RCM_a098_eventIDFsignal m98 : 25|1@1+ (1,0) [0|0] "" Vector__XXX
 SG_ RCM_a099_eventIDFsignal m99 : 25|1@1+ (1,0) [0|0] "" Vector__XXX
 SG_ RCM_a100_eventIDFsignal m100 : 25|1@1+ (1,0) [0|0] "" Vector__XXX
 SG_ RCM_a101_eventIDFsignal m101 : 25|1@1+ (1,0) [0|0] "" Vector__XXX
 SG_ RCM_a102_eventIDFsignal m102 : 25|1@1+ (1,0) [0|0] "" Vector__XXX
 SG_ RCM_a103_eventIDFsignal m103 : 25|1@1+ (1,0) [0|0] "" Vector__XXX
 SG_ RCM_a104_eventIDFsignal m104 : 25|1@1+ (1,0) [0|0] "" Vector__XXX
 SG_ RCM_a105_eventIDFsignal m105 : 25|1@1+ (1,0) [0|0] "" Vector__XXX
 SG_ RCM_a106_eventIDFsignal m106 : 25|1@1+ (1,0) [0|0] "" Vector__XXX
 SG_ RCM_a107_eventIDFsignal m107 : 25|1@1+ (1,0) [0|0] "" Vector__XXX
 SG_ RCM_a108_eventIDFsignal m108 : 25|1@1+ (1,0) [0|0] "" Vector__XXX
 SG_ RCM_a109_eventIDFsignal m109 : 25|1@1+ (1,0) [0|0] "" Vector__XXX
 SG_ RCM_a110_eventIDFsignal m110 : 25|1@1+ (1,0) [0|0] "" Vector__XXX
 SG_ RCM_a111_eventIDFsignal m111 : 25|1@1+ (1,0) [0|0] "" Vector__XXX
 SG_ RCM_a112_eventIDFsignal m112 : 25|1@1+ (1,0) [0|0] "" Vector__XXX
 SG_ RCM_a113_eventIDFsignal m113 : 25|1@1+ (1,0) [0|0] "" Vector__XXX
 SG_ RCM_a114_eventIDFsignal m114 : 25|1@1+ (1,0) [0|0] "" Vector__XXX
 SG_ RCM_a115_eventIDFsignal m115 : 25|1@1+ (1,0) [0|0] "" Vector__XXX
 SG_ RCM_a116_eventIDFsignal m116 : 25|1@1+ (1,0) [0|0] "" Vector__XXX
 SG_ RCM_a117_eventIDFsignal m117 : 25|1@1+ (1,0) [0|0] "" Vector__XXX
 SG_ RCM_a118_eventIDFsignal m118 : 25|1@1+ (1,0) [0|0] "" Vector__XXX
 SG_ RCM_a000_eventFrontLeftSeatbelt m0 : 26|1@1+ (1,0) [0|0] "" Vector__XXX
 SG_ RCM_a001_eventFrontLeftSeatbelt m1 : 26|1@1+ (1,0) [0|0] "" Vector__XXX
 SG_ RCM_a002_eventFrontLeftSeatbelt m2 : 26|1@1+ (1,0) [0|0] "" Vector__XXX
 SG_ RCM_a003_eventFrontLeftSeatbelt m3 : 26|1@1+ (1,0) [0|0] "" Vector__XXX
 SG_ RCM_a004_eventFrontLeftSeatbelt m4 : 26|1@1+ (1,0) [0|0] "" Vector__XXX
 SG_ RCM_a005_eventFrontLeftSeatbelt m5 : 26|1@1+ (1,0) [0|0] "" Vector__XXX
 SG_ RCM_a006_eventFrontLeftSeatbelt m6 : 26|1@1+ (1,0) [0|0] "" Vector__XXX
 SG_ RCM_a007_eventFrontLeftSeatbelt m7 : 26|1@1+ (1,0) [0|0] "" Vector__XXX
 SG_ RCM_a008_eventFrontLeftSeatbelt m8 : 26|1@1+ (1,0) [0|0] "" Vector__XXX
 SG_ RCM_a009_eventFrontLeftSeatbelt m9 : 26|1@1+ (1,0) [0|0] "" Vector__XXX
 SG_ RCM_a010_eventFrontLeftSeatbelt m10 : 26|1@1+ (1,0) [0|0] "" Vector__XXX
 SG_ RCM_a011_eventFrontLeftSeatbelt m11 : 26|1@1+ (1,0) [0|0] "" Vector__XXX
 SG_ RCM_a012_eventFrontLeftSeatbelt m12 : 26|1@1+ (1,0) [0|0] "" Vector__XXX
 SG_ RCM_a013_eventFrontLeftSeatbelt m13 : 26|1@1+ (1,0) [0|0] "" Vector__XXX
 SG_ RCM_a014_eventFrontLeftSeatbelt m14 : 26|1@1+ (1,0) [0|0] "" Vector__XXX
 SG_ RCM_a015_eventFrontLeftSeatbelt m15 : 26|1@1+ (1,0) [0|0] "" Vector__XXX
 SG_ RCM_a016_eventFrontLeftSeatbelt m16 : 26|1@1+ (1,0) [0|0] "" Vector__XXX
 SG_ RCM_a017_eventFrontLeftSeatbelt m17 : 26|1@1+ (1,0) [0|0] "" Vector__XXX
 SG_ RCM_a018_eventFrontLeftSeatbelt m18 : 26|1@1+ (1,0) [0|0] "" Vector__XXX
 SG_ RCM_a019_eventFrontLeftSeatbelt m19 : 26|1@1+ (1,0) [0|0] "" Vector__XXX
 SG_ RCM_a020_eventFrontLeftSeatbelt m20 : 26|1@1+ (1,0) [0|0] "" Vector__XXX
 SG_ RCM_a021_eventFrontLeftSeatbelt m21 : 26|1@1+ (1,0) [0|0] "" Vector__XXX
 SG_ RCM_a022_eventFrontLeftSeatbelt m22 : 26|1@1+ (1,0) [0|0] "" Vector__XXX
 SG_ RCM_a023_eventFrontLeftSeatbelt m23 : 26|1@1+ (1,0) [0|0] "" Vector__XXX
 SG_ RCM_a024_eventFrontLeftSeatbelt m24 : 26|1@1+ (1,0) [0|0] "" Vector__XXX
 SG_ RCM_a025_eventFrontLeftSeatbelt m25 : 26|1@1+ (1,0) [0|0] "" Vector__XXX
 SG_ RCM_a026_eventFrontLeftSeatbelt m26 : 26|1@1+ (1,0) [0|0] "" Vector__XXX
 SG_ RCM_a027_eventFrontLeftSeatbelt m27 : 26|1@1+ (1,0) [0|0] "" Vector__XXX
 SG_ RCM_a028_eventFrontLeftSeatbelt m28 : 26|1@1+ (1,0) [0|0] "" Vector__XXX
 SG_ RCM_a029_eventFrontLeftSeatbelt m29 : 26|1@1+ (1,0) [0|0] "" Vector__XXX
 SG_ RCM_a030_eventFrontLeftSeatbelt m30 : 26|1@1+ (1,0) [0|0] "" Vector__XXX
 SG_ RCM_a031_eventFrontLeftSeatbelt m31 : 26|1@1+ (1,0) [0|0] "" Vector__XXX
 SG_ RCM_a032_eventFrontLeftSeatbelt m32 : 26|1@1+ (1,0) [0|0] "" Vector__XXX
 SG_ RCM_a033_eventFrontLeftSeatbelt m33 : 26|1@1+ (1,0) [0|0] "" Vector__XXX
 SG_ RCM_a034_eventFrontLeftSeatbelt m34 : 26|1@1+ (1,0) [0|0] "" Vector__XXX
 SG_ RCM_a035_eventFrontLeftSeatbelt m35 : 26|1@1+ (1,0) [0|0] "" Vector__XXX
 SG_ RCM_a036_eventFrontLeftSeatbelt m36 : 26|1@1+ (1,0) [0|0] "" Vector__XXX
 SG_ RCM_a037_eventFrontLeftSeatbelt m37 : 26|1@1+ (1,0) [0|0] "" Vector__XXX
 SG_ RCM_a038_eventFrontLeftSeatbelt m38 : 26|1@1+ (1,0) [0|0] "" Vector__XXX
 SG_ RCM_a039_eventFrontLeftSeatbelt m39 : 26|1@1+ (1,0) [0|0] "" Vector__XXX
 SG_ RCM_a040_eventFrontLeftSeatbelt m40 : 26|1@1+ (1,0) [0|0] "" Vector__XXX
 SG_ RCM_a041_eventFrontLeftSeatbelt m41 : 26|1@1+ (1,0) [0|0] "" Vector__XXX
 SG_ RCM_a042_eventFrontLeftSeatbelt m42 : 26|1@1+ (1,0) [0|0] "" Vector__XXX
 SG_ RCM_a043_eventFrontLeftSeatbelt m43 : 26|1@1+ (1,0) [0|0] "" Vector__XXX
 SG_ RCM_a044_eventFrontLeftSeatbelt m44 : 26|1@1+ (1,0) [0|0] "" Vector__XXX
 SG_ RCM_a045_eventFrontLeftSeatbelt m45 : 26|1@1+ (1,0) [0|0] "" Vector__XXX
 SG_ RCM_a046_eventFrontLeftSeatbelt m46 : 26|1@1+ (1,0) [0|0] "" Vector__XXX
 SG_ RCM_a047_eventFrontLeftSeatbelt m47 : 26|1@1+ (1,0) [0|0] "" Vector__XXX
 SG_ RCM_a048_eventFrontLeftSeatbelt m48 : 26|1@1+ (1,0) [0|0] "" Vector__XXX
 SG_ RCM_a049_eventFrontLeftSeatbelt m49 : 26|1@1+ (1,0) [0|0] "" Vector__XXX
 SG_ RCM_a050_eventFrontLeftSeatbelt m50 : 26|1@1+ (1,0) [0|0] "" Vector__XXX
 SG_ RCM_a051_eventFrontLeftSeatbelt m51 : 26|1@1+ (1,0) [0|0] "" Vector__XXX
 SG_ RCM_a052_eventFrontLeftSeatbelt m52 : 26|1@1+ (1,0) [0|0] "" Vector__XXX
 SG_ RCM_a053_eventFrontLeftSeatbelt m53 : 26|1@1+ (1,0) [0|0] "" Vector__XXX
 SG_ RCM_a054_eventFrontLeftSeatbelt m54 : 26|1@1+ (1,0) [0|0] "" Vector__XXX
 SG_ RCM_a055_eventFrontLeftSeatbelt m55 : 26|1@1+ (1,0) [0|0] "" Vector__XXX
 SG_ RCM_a056_eventFrontLeftSeatbelt m56 : 26|1@1+ (1,0) [0|0] "" Vector__XXX
 SG_ RCM_a057_eventFrontLeftSeatbelt m57 : 26|1@1+ (1,0) [0|0] "" Vector__XXX
 SG_ RCM_a058_eventFrontLeftSeatbelt m58 : 26|1@1+ (1,0) [0|0] "" Vector__XXX
 SG_ RCM_a059_eventFrontLeftSeatbelt m59 : 26|1@1+ (1,0) [0|0] "" Vector__XXX
 SG_ RCM_a060_eventFrontLeftSeatbelt m60 : 26|1@1+ (1,0) [0|0] "" Vector__XXX
 SG_ RCM_a061_eventFrontLeftSeatbelt m61 : 26|1@1+ (1,0) [0|0] "" Vector__XXX
 SG_ RCM_a062_eventFrontLeftSeatbelt m62 : 26|1@1+ (1,0) [0|0] "" Vector__XXX
 SG_ RCM_a063_eventFrontLeftSeatbelt m63 : 26|1@1+ (1,0) [0|0] "" Vector__XXX
 SG_ RCM_a064_eventFrontLeftSeatbelt m64 : 26|1@1+ (1,0) [0|0] "" Vector__XXX
 SG_ RCM_a065_eventFrontLeftSeatbelt m65 : 26|1@1+ (1,0) [0|0] "" Vector__XXX
 SG_ RCM_a066_eventFrontLeftSeatbelt m66 : 26|1@1+ (1,0) [0|0] "" Vector__XXX
 SG_ RCM_a067_eventFrontLeftSeatbelt m67 : 26|1@1+ (1,0) [0|0] "" Vector__XXX
 SG_ RCM_a068_eventFrontLeftSeatbelt m68 : 26|1@1+ (1,0) [0|0] "" Vector__XXX
 SG_ RCM_a069_eventFrontLeftSeatbelt m69 : 26|1@1+ (1,0) [0|0] "" Vector__XXX
 SG_ RCM_a070_eventFrontLeftSeatbelt m70 : 26|1@1+ (1,0) [0|0] "" Vector__XXX
 SG_ RCM_a071_eventFrontLeftSeatbelt m71 : 26|1@1+ (1,0) [0|0] "" Vector__XXX
 SG_ RCM_a072_eventFrontLeftSeatbelt m72 : 26|1@1+ (1,0) [0|0] "" Vector__XXX
 SG_ RCM_a073_eventFrontLeftSeatbelt m73 : 26|1@1+ (1,0) [0|0] "" Vector__XXX
 SG_ RCM_a074_eventFrontLeftSeatbelt m74 : 26|1@1+ (1,0) [0|0] "" Vector__XXX
 SG_ RCM_a075_eventFrontLeftSeatbelt m75 : 26|1@1+ (1,0) [0|0] "" Vector__XXX
 SG_ RCM_a076_eventFrontLeftSeatbelt m76 : 26|1@1+ (1,0) [0|0] "" Vector__XXX
 SG_ RCM_a077_eventFrontLeftSeatbelt m77 : 26|1@1+ (1,0) [0|0] "" Vector__XXX
 SG_ RCM_a078_eventFrontLeftSeatbelt m78 : 26|1@1+ (1,0) [0|0] "" Vector__XXX
 SG_ RCM_a079_eventFrontLeftSeatbelt m79 : 26|1@1+ (1,0) [0|0] "" Vector__XXX
 SG_ RCM_a080_eventFrontLeftSeatbelt m80 : 26|1@1+ (1,0) [0|0] "" Vector__XXX
 SG_ RCM_a081_eventFrontLeftSeatbelt m81 : 26|1@1+ (1,0) [0|0] "" Vector__XXX
 SG_ RCM_a082_eventFrontLeftSeatbelt m82 : 26|1@1+ (1,0) [0|0] "" Vector__XXX
 SG_ RCM_a083_eventFrontLeftSeatbelt m83 : 26|1@1+ (1,0) [0|0] "" Vector__XXX
 SG_ RCM_a084_eventFrontLeftSeatbelt m84 : 26|1@1+ (1,0) [0|0] "" Vector__XXX
 SG_ RCM_a085_eventFrontLeftSeatbelt m85 : 26|1@1+ (1,0) [0|0] "" Vector__XXX
 SG_ RCM_a086_eventFrontLeftSeatbelt m86 : 26|1@1+ (1,0) [0|0] "" Vector__XXX
 SG_ RCM_a087_eventFrontLeftSeatbelt m87 : 26|1@1+ (1,0) [0|0] "" Vector__XXX
 SG_ RCM_a088_eventFrontLeftSeatbelt m88 : 26|1@1+ (1,0) [0|0] "" Vector__XXX
 SG_ RCM_a089_eventFrontLeftSeatbelt m89 : 26|1@1+ (1,0) [0|0] "" Vector__XXX
 SG_ RCM_a090_eventFrontLeftSeatbelt m90 : 26|1@1+ (1,0) [0|0] "" Vector__XXX
 SG_ RCM_a091_eventFrontLeftSeatbelt m91 : 26|1@1+ (1,0) [0|0] "" Vector__XXX
 SG_ RCM_a092_eventFrontLeftSeatbelt m92 : 26|1@1+ (1,0) [0|0] "" Vector__XXX
 SG_ RCM_a093_eventFrontLeftSeatbelt m93 : 26|1@1+ (1,0) [0|0] "" Vector__XXX
 SG_ RCM_a094_eventFrontLeftSeatbelt m94 : 26|1@1+ (1,0) [0|0] "" Vector__XXX
 SG_ RCM_a095_eventFrontLeftSeatbelt m95 : 26|1@1+ (1,0) [0|0] "" Vector__XXX
 SG_ RCM_a096_eventFrontLeftSeatbelt m96 : 26|1@1+ (1,0) [0|0] "" Vector__XXX
 SG_ RCM_a097_eventFrontLeftSeatbelt m97 : 26|1@1+ (1,0) [0|0] "" Vector__XXX
 SG_ RCM_a098_eventFrontLeftSeatbelt m98 : 26|1@1+ (1,0) [0|0] "" Vector__XXX
 SG_ RCM_a099_eventFrontLeftSeatbelt m99 : 26|1@1+ (1,0) [0|0] "" Vector__XXX
 SG_ RCM_a100_eventFrontLeftSeatbelt m100 : 26|1@1+ (1,0) [0|0] "" Vector__XXX
 SG_ RCM_a101_eventFrontLeftSeatbelt m101 : 26|1@1+ (1,0) [0|0] "" Vector__XXX
 SG_ RCM_a102_eventFrontLeftSeatbelt m102 : 26|1@1+ (1,0) [0|0] "" Vector__XXX
 SG_ RCM_a103_eventFrontLeftSeatbelt m103 : 26|1@1+ (1,0) [0|0] "" Vector__XXX
 SG_ RCM_a104_eventFrontLeftSeatbelt m104 : 26|1@1+ (1,0) [0|0] "" Vector__XXX
 SG_ RCM_a105_eventFrontLeftSeatbelt m105 : 26|1@1+ (1,0) [0|0] "" Vector__XXX
 SG_ RCM_a106_eventFrontLeftSeatbelt m106 : 26|1@1+ (1,0) [0|0] "" Vector__XXX
 SG_ RCM_a107_eventFrontLeftSeatbelt m107 : 26|1@1+ (1,0) [0|0] "" Vector__XXX
 SG_ RCM_a108_eventFrontLeftSeatbelt m108 : 26|1@1+ (1,0) [0|0] "" Vector__XXX
 SG_ RCM_a109_eventFrontLeftSeatbelt m109 : 26|1@1+ (1,0) [0|0] "" Vector__XXX
 SG_ RCM_a110_eventFrontLeftSeatbelt m110 : 26|1@1+ (1,0) [0|0] "" Vector__XXX
 SG_ RCM_a111_eventFrontLeftSeatbelt m111 : 26|1@1+ (1,0) [0|0] "" Vector__XXX
 SG_ RCM_a112_eventFrontLeftSeatbelt m112 : 26|1@1+ (1,0) [0|0] "" Vector__XXX
 SG_ RCM_a113_eventFrontLeftSeatbelt m113 : 26|1@1+ (1,0) [0|0] "" Vector__XXX
 SG_ RCM_a114_eventFrontLeftSeatbelt m114 : 26|1@1+ (1,0) [0|0] "" Vector__XXX
 SG_ RCM_a115_eventFrontLeftSeatbelt m115 : 26|1@1+ (1,0) [0|0] "" Vector__XXX
 SG_ RCM_a116_eventFrontLeftSeatbelt m116 : 26|1@1+ (1,0) [0|0] "" Vector__XXX
 SG_ RCM_a117_eventFrontLeftSeatbelt m117 : 26|1@1+ (1,0) [0|0] "" Vector__XXX
 SG_ RCM_a118_eventFrontLeftSeatbelt m118 : 26|1@1+ (1,0) [0|0] "" Vector__XXX
 SG_ RCM_a000_eventFrontRightSeatbelt m0 : 27|1@1+ (1,0) [0|0] "" Vector__XXX
 SG_ RCM_a001_eventFrontRightSeatbelt m1 : 27|1@1+ (1,0) [0|0] "" Vector__XXX
 SG_ RCM_a002_eventFrontRightSeatbelt m2 : 27|1@1+ (1,0) [0|0] "" Vector__XXX
 SG_ RCM_a003_eventFrontRightSeatbelt m3 : 27|1@1+ (1,0) [0|0] "" Vector__XXX
 SG_ RCM_a004_eventFrontRightSeatbelt m4 : 27|1@1+ (1,0) [0|0] "" Vector__XXX
 SG_ RCM_a005_eventFrontRightSeatbelt m5 : 27|1@1+ (1,0) [0|0] "" Vector__XXX
 SG_ RCM_a006_eventFrontRightSeatbelt m6 : 27|1@1+ (1,0) [0|0] "" Vector__XXX
 SG_ RCM_a007_eventFrontRightSeatbelt m7 : 27|1@1+ (1,0) [0|0] "" Vector__XXX
 SG_ RCM_a008_eventFrontRightSeatbelt m8 : 27|1@1+ (1,0) [0|0] "" Vector__XXX
 SG_ RCM_a009_eventFrontRightSeatbelt m9 : 27|1@1+ (1,0) [0|0] "" Vector__XXX
 SG_ RCM_a010_eventFrontRightSeatbelt m10 : 27|1@1+ (1,0) [0|0] "" Vector__XXX
 SG_ RCM_a011_eventFrontRightSeatbelt m11 : 27|1@1+ (1,0) [0|0] "" Vector__XXX
 SG_ RCM_a012_eventFrontRightSeatbelt m12 : 27|1@1+ (1,0) [0|0] "" Vector__XXX
 SG_ RCM_a013_eventFrontRightSeatbelt m13 : 27|1@1+ (1,0) [0|0] "" Vector__XXX
 SG_ RCM_a014_eventFrontRightSeatbelt m14 : 27|1@1+ (1,0) [0|0] "" Vector__XXX
 SG_ RCM_a015_eventFrontRightSeatbelt m15 : 27|1@1+ (1,0) [0|0] "" Vector__XXX
 SG_ RCM_a016_eventFrontRightSeatbelt m16 : 27|1@1+ (1,0) [0|0] "" Vector__XXX
 SG_ RCM_a017_eventFrontRightSeatbelt m17 : 27|1@1+ (1,0) [0|0] "" Vector__XXX
 SG_ RCM_a018_eventFrontRightSeatbelt m18 : 27|1@1+ (1,0) [0|0] "" Vector__XXX
 SG_ RCM_a019_eventFrontRightSeatbelt m19 : 27|1@1+ (1,0) [0|0] "" Vector__XXX
 SG_ RCM_a020_eventFrontRightSeatbelt m20 : 27|1@1+ (1,0) [0|0] "" Vector__XXX
 SG_ RCM_a021_eventFrontRightSeatbelt m21 : 27|1@1+ (1,0) [0|0] "" Vector__XXX
 SG_ RCM_a022_eventFrontRightSeatbelt m22 : 27|1@1+ (1,0) [0|0] "" Vector__XXX
 SG_ RCM_a023_eventFrontRightSeatbelt m23 : 27|1@1+ (1,0) [0|0] "" Vector__XXX
 SG_ RCM_a024_eventFrontRightSeatbelt m24 : 27|1@1+ (1,0) [0|0] "" Vector__XXX
 SG_ RCM_a025_eventFrontRightSeatbelt m25 : 27|1@1+ (1,0) [0|0] "" Vector__XXX
 SG_ RCM_a026_eventFrontRightSeatbelt m26 : 27|1@1+ (1,0) [0|0] "" Vector__XXX
 SG_ RCM_a027_eventFrontRightSeatbelt m27 : 27|1@1+ (1,0) [0|0] "" Vector__XXX
 SG_ RCM_a028_eventFrontRightSeatbelt m28 : 27|1@1+ (1,0) [0|0] "" Vector__XXX
 SG_ RCM_a029_eventFrontRightSeatbelt m29 : 27|1@1+ (1,0) [0|0] "" Vector__XXX
 SG_ RCM_a030_eventFrontRightSeatbelt m30 : 27|1@1+ (1,0) [0|0] "" Vector__XXX
 SG_ RCM_a031_eventFrontRightSeatbelt m31 : 27|1@1+ (1,0) [0|0] "" Vector__XXX
 SG_ RCM_a032_eventFrontRightSeatbelt m32 : 27|1@1+ (1,0) [0|0] "" Vector__XXX
 SG_ RCM_a033_eventFrontRightSeatbelt m33 : 27|1@1+ (1,0) [0|0] "" Vector__XXX
 SG_ RCM_a034_eventFrontRightSeatbelt m34 : 27|1@1+ (1,0) [0|0] "" Vector__XXX
 SG_ RCM_a035_eventFrontRightSeatbelt m35 : 27|1@1+ (1,0) [0|0] "" Vector__XXX
 SG_ RCM_a036_eventFrontRightSeatbelt m36 : 27|1@1+ (1,0) [0|0] "" Vector__XXX
 SG_ RCM_a037_eventFrontRightSeatbelt m37 : 27|1@1+ (1,0) [0|0] "" Vector__XXX
 SG_ RCM_a038_eventFrontRightSeatbelt m38 : 27|1@1+ (1,0) [0|0] "" Vector__XXX
 SG_ RCM_a039_eventFrontRightSeatbelt m39 : 27|1@1+ (1,0) [0|0] "" Vector__XXX
 SG_ RCM_a040_eventFrontRightSeatbelt m40 : 27|1@1+ (1,0) [0|0] "" Vector__XXX
 SG_ RCM_a041_eventFrontRightSeatbelt m41 : 27|1@1+ (1,0) [0|0] "" Vector__XXX
 SG_ RCM_a042_eventFrontRightSeatbelt m42 : 27|1@1+ (1,0) [0|0] "" Vector__XXX
 SG_ RCM_a043_eventFrontRightSeatbelt m43 : 27|1@1+ (1,0) [0|0] "" Vector__XXX
 SG_ RCM_a044_eventFrontRightSeatbelt m44 : 27|1@1+ (1,0) [0|0] "" Vector__XXX
 SG_ RCM_a045_eventFrontRightSeatbelt m45 : 27|1@1+ (1,0) [0|0] "" Vector__XXX
 SG_ RCM_a046_eventFrontRightSeatbelt m46 : 27|1@1+ (1,0) [0|0] "" Vector__XXX
 SG_ RCM_a047_eventFrontRightSeatbelt m47 : 27|1@1+ (1,0) [0|0] "" Vector__XXX
 SG_ RCM_a048_eventFrontRightSeatbelt m48 : 27|1@1+ (1,0) [0|0] "" Vector__XXX
 SG_ RCM_a049_eventFrontRightSeatbelt m49 : 27|1@1+ (1,0) [0|0] "" Vector__XXX
 SG_ RCM_a050_eventFrontRightSeatbelt m50 : 27|1@1+ (1,0) [0|0] "" Vector__XXX
 SG_ RCM_a051_eventFrontRightSeatbelt m51 : 27|1@1+ (1,0) [0|0] "" Vector__XXX
 SG_ RCM_a052_eventFrontRightSeatbelt m52 : 27|1@1+ (1,0) [0|0] "" Vector__XXX
 SG_ RCM_a053_eventFrontRightSeatbelt m53 : 27|1@1+ (1,0) [0|0] "" Vector__XXX
 SG_ RCM_a054_eventFrontRightSeatbelt m54 : 27|1@1+ (1,0) [0|0] "" Vector__XXX
 SG_ RCM_a055_eventFrontRightSeatbelt m55 : 27|1@1+ (1,0) [0|0] "" Vector__XXX
 SG_ RCM_a056_eventFrontRightSeatbelt m56 : 27|1@1+ (1,0) [0|0] "" Vector__XXX
 SG_ RCM_a057_eventFrontRightSeatbelt m57 : 27|1@1+ (1,0) [0|0] "" Vector__XXX
 SG_ RCM_a058_eventFrontRightSeatbelt m58 : 27|1@1+ (1,0) [0|0] "" Vector__XXX
 SG_ RCM_a059_eventFrontRightSeatbelt m59 : 27|1@1+ (1,0) [0|0] "" Vector__XXX
 SG_ RCM_a060_eventFrontRightSeatbelt m60 : 27|1@1+ (1,0) [0|0] "" Vector__XXX
 SG_ RCM_a061_eventFrontRightSeatbelt m61 : 27|1@1+ (1,0) [0|0] "" Vector__XXX
 SG_ RCM_a062_eventFrontRightSeatbelt m62 : 27|1@1+ (1,0) [0|0] "" Vector__XXX
 SG_ RCM_a063_eventFrontRightSeatbelt m63 : 27|1@1+ (1,0) [0|0] "" Vector__XXX
 SG_ RCM_a064_eventFrontRightSeatbelt m64 : 27|1@1+ (1,0) [0|0] "" Vector__XXX
 SG_ RCM_a065_eventFrontRightSeatbelt m65 : 27|1@1+ (1,0) [0|0] "" Vector__XXX
 SG_ RCM_a066_eventFrontRightSeatbelt m66 : 27|1@1+ (1,0) [0|0] "" Vector__XXX
 SG_ RCM_a067_eventFrontRightSeatbelt m67 : 27|1@1+ (1,0) [0|0] "" Vector__XXX
 SG_ RCM_a068_eventFrontRightSeatbelt m68 : 27|1@1+ (1,0) [0|0] "" Vector__XXX
 SG_ RCM_a069_eventFrontRightSeatbelt m69 : 27|1@1+ (1,0) [0|0] "" Vector__XXX
 SG_ RCM_a070_eventFrontRightSeatbelt m70 : 27|1@1+ (1,0) [0|0] "" Vector__XXX
 SG_ RCM_a071_eventFrontRightSeatbelt m71 : 27|1@1+ (1,0) [0|0] "" Vector__XXX
 SG_ RCM_a072_eventFrontRightSeatbelt m72 : 27|1@1+ (1,0) [0|0] "" Vector__XXX
 SG_ RCM_a073_eventFrontRightSeatbelt m73 : 27|1@1+ (1,0) [0|0] "" Vector__XXX
 SG_ RCM_a074_eventFrontRightSeatbelt m74 : 27|1@1+ (1,0) [0|0] "" Vector__XXX
 SG_ RCM_a075_eventFrontRightSeatbelt m75 : 27|1@1+ (1,0) [0|0] "" Vector__XXX
 SG_ RCM_a076_eventFrontRightSeatbelt m76 : 27|1@1+ (1,0) [0|0] "" Vector__XXX
 SG_ RCM_a077_eventFrontRightSeatbelt m77 : 27|1@1+ (1,0) [0|0] "" Vector__XXX
 SG_ RCM_a078_eventFrontRightSeatbelt m78 : 27|1@1+ (1,0) [0|0] "" Vector__XXX
 SG_ RCM_a079_eventFrontRightSeatbelt m79 : 27|1@1+ (1,0) [0|0] "" Vector__XXX
 SG_ RCM_a080_eventFrontRightSeatbelt m80 : 27|1@1+ (1,0) [0|0] "" Vector__XXX
 SG_ RCM_a081_eventFrontRightSeatbelt m81 : 27|1@1+ (1,0) [0|0] "" Vector__XXX
 SG_ RCM_a082_eventFrontRightSeatbelt m82 : 27|1@1+ (1,0) [0|0] "" Vector__XXX
 SG_ RCM_a083_eventFrontRightSeatbelt m83 : 27|1@1+ (1,0) [0|0] "" Vector__XXX
 SG_ RCM_a084_eventFrontRightSeatbelt m84 : 27|1@1+ (1,0) [0|0] "" Vector__XXX
 SG_ RCM_a085_eventFrontRightSeatbelt m85 : 27|1@1+ (1,0) [0|0] "" Vector__XXX
 SG_ RCM_a086_eventFrontRightSeatbelt m86 : 27|1@1+ (1,0) [0|0] "" Vector__XXX
 SG_ RCM_a087_eventFrontRightSeatbelt m87 : 27|1@1+ (1,0) [0|0] "" Vector__XXX
 SG_ RCM_a088_eventFrontRightSeatbelt m88 : 27|1@1+ (1,0) [0|0] "" Vector__XXX
 SG_ RCM_a089_eventFrontRightSeatbelt m89 : 27|1@1+ (1,0) [0|0] "" Vector__XXX
 SG_ RCM_a090_eventFrontRightSeatbelt m90 : 27|1@1+ (1,0) [0|0] "" Vector__XXX
 SG_ RCM_a091_eventFrontRightSeatbelt m91 : 27|1@1+ (1,0) [0|0] "" Vector__XXX
 SG_ RCM_a092_eventFrontRightSeatbelt m92 : 27|1@1+ (1,0) [0|0] "" Vector__XXX
 SG_ RCM_a093_eventFrontRightSeatbelt m93 : 27|1@1+ (1,0) [0|0] "" Vector__XXX
 SG_ RCM_a094_eventFrontRightSeatbelt m94 : 27|1@1+ (1,0) [0|0] "" Vector__XXX
 SG_ RCM_a095_eventFrontRightSeatbelt m95 : 27|1@1+ (1,0) [0|0] "" Vector__XXX
 SG_ RCM_a096_eventFrontRightSeatbelt m96 : 27|1@1+ (1,0) [0|0] "" Vector__XXX
 SG_ RCM_a097_eventFrontRightSeatbelt m97 : 27|1@1+ (1,0) [0|0] "" Vector__XXX
 SG_ RCM_a098_eventFrontRightSeatbelt m98 : 27|1@1+ (1,0) [0|0] "" Vector__XXX
 SG_ RCM_a099_eventFrontRightSeatbelt m99 : 27|1@1+ (1,0) [0|0] "" Vector__XXX
 SG_ RCM_a100_eventFrontRightSeatbelt m100 : 27|1@1+ (1,0) [0|0] "" Vector__XXX
 SG_ RCM_a101_eventFrontRightSeatbelt m101 : 27|1@1+ (1,0) [0|0] "" Vector__XXX
 SG_ RCM_a102_eventFrontRightSeatbelt m102 : 27|1@1+ (1,0) [0|0] "" Vector__XXX
 SG_ RCM_a103_eventFrontRightSeatbelt m103 : 27|1@1+ (1,0) [0|0] "" Vector__XXX
 SG_ RCM_a104_eventFrontRightSeatbelt m104 : 27|1@1+ (1,0) [0|0] "" Vector__XXX
 SG_ RCM_a105_eventFrontRightSeatbelt m105 : 27|1@1+ (1,0) [0|0] "" Vector__XXX
 SG_ RCM_a106_eventFrontRightSeatbelt m106 : 27|1@1+ (1,0) [0|0] "" Vector__XXX
 SG_ RCM_a107_eventFrontRightSeatbelt m107 : 27|1@1+ (1,0) [0|0] "" Vector__XXX
 SG_ RCM_a108_eventFrontRightSeatbelt m108 : 27|1@1+ (1,0) [0|0] "" Vector__XXX
 SG_ RCM_a109_eventFrontRightSeatbelt m109 : 27|1@1+ (1,0) [0|0] "" Vector__XXX
 SG_ RCM_a110_eventFrontRightSeatbelt m110 : 27|1@1+ (1,0) [0|0] "" Vector__XXX
 SG_ RCM_a111_eventFrontRightSeatbelt m111 : 27|1@1+ (1,0) [0|0] "" Vector__XXX
 SG_ RCM_a112_eventFrontRightSeatbelt m112 : 27|1@1+ (1,0) [0|0] "" Vector__XXX
 SG_ RCM_a113_eventFrontRightSeatbelt m113 : 27|1@1+ (1,0) [0|0] "" Vector__XXX
 SG_ RCM_a114_eventFrontRightSeatbelt m114 : 27|1@1+ (1,0) [0|0] "" Vector__XXX
 SG_ RCM_a115_eventFrontRightSeatbelt m115 : 27|1@1+ (1,0) [0|0] "" Vector__XXX
 SG_ RCM_a116_eventFrontRightSeatbelt m116 : 27|1@1+ (1,0) [0|0] "" Vector__XXX
 SG_ RCM_a117_eventFrontRightSeatbelt m117 : 27|1@1+ (1,0) [0|0] "" Vector__XXX
 SG_ RCM_a118_eventFrontRightSeatbelt m118 : 27|1@1+ (1,0) [0|0] "" Vector__XXX
 SG_ RCM_a000_eventVehicleSpeed m0 : 28|12@1+ (0.08,-40) [0|0] "" Vector__XXX
 SG_ RCM_a001_eventVehicleSpeed m1 : 28|12@1+ (0.08,-40) [0|0] "" Vector__XXX
 SG_ RCM_a002_eventVehicleSpeed m2 : 28|12@1+ (0.08,-40) [0|0] "" Vector__XXX
 SG_ RCM_a003_eventVehicleSpeed m3 : 28|12@1+ (0.08,-40) [0|0] "" Vector__XXX
 SG_ RCM_a004_eventVehicleSpeed m4 : 28|12@1+ (0.08,-40) [0|0] "" Vector__XXX
 SG_ RCM_a005_eventVehicleSpeed m5 : 28|12@1+ (0.08,-40) [0|0] "" Vector__XXX
 SG_ RCM_a006_eventVehicleSpeed m6 : 28|12@1+ (0.08,-40) [0|0] "" Vector__XXX
 SG_ RCM_a007_eventVehicleSpeed m7 : 28|12@1+ (0.08,-40) [0|0] "" Vector__XXX
 SG_ RCM_a008_eventVehicleSpeed m8 : 28|12@1+ (0.08,-40) [0|0] "" Vector__XXX
 SG_ RCM_a009_eventVehicleSpeed m9 : 28|12@1+ (0.08,-40) [0|0] "" Vector__XXX
 SG_ RCM_a010_eventVehicleSpeed m10 : 28|12@1+ (0.08,-40) [0|0] "" Vector__XXX
 SG_ RCM_a011_eventVehicleSpeed m11 : 28|12@1+ (0.08,-40) [0|0] "" Vector__XXX
 SG_ RCM_a012_eventVehicleSpeed m12 : 28|12@1+ (0.08,-40) [0|0] "" Vector__XXX
 SG_ RCM_a013_eventVehicleSpeed m13 : 28|12@1+ (0.08,-40) [0|0] "" Vector__XXX
 SG_ RCM_a014_eventVehicleSpeed m14 : 28|12@1+ (0.08,-40) [0|0] "" Vector__XXX
 SG_ RCM_a015_eventVehicleSpeed m15 : 28|12@1+ (0.08,-40) [0|0] "" Vector__XXX
 SG_ RCM_a016_eventVehicleSpeed m16 : 28|12@1+ (0.08,-40) [0|0] "" Vector__XXX
 SG_ RCM_a017_eventVehicleSpeed m17 : 28|12@1+ (0.08,-40) [0|0] "" Vector__XXX
 SG_ RCM_a018_eventVehicleSpeed m18 : 28|12@1+ (0.08,-40) [0|0] "" Vector__XXX
 SG_ RCM_a019_eventVehicleSpeed m19 : 28|12@1+ (0.08,-40) [0|0] "" Vector__XXX
 SG_ RCM_a020_eventVehicleSpeed m20 : 28|12@1+ (0.08,-40) [0|0] "" Vector__XXX
 SG_ RCM_a021_eventVehicleSpeed m21 : 28|12@1+ (0.08,-40) [0|0] "" Vector__XXX
 SG_ RCM_a022_eventVehicleSpeed m22 : 28|12@1+ (0.08,-40) [0|0] "" Vector__XXX
 SG_ RCM_a023_eventVehicleSpeed m23 : 28|12@1+ (0.08,-40) [0|0] "" Vector__XXX
 SG_ RCM_a024_eventVehicleSpeed m24 : 28|12@1+ (0.08,-40) [0|0] "" Vector__XXX
 SG_ RCM_a025_eventVehicleSpeed m25 : 28|12@1+ (0.08,-40) [0|0] "" Vector__XXX
 SG_ RCM_a026_eventVehicleSpeed m26 : 28|12@1+ (0.08,-40) [0|0] "" Vector__XXX
 SG_ RCM_a027_eventVehicleSpeed m27 : 28|12@1+ (0.08,-40) [0|0] "" Vector__XXX
 SG_ RCM_a028_eventVehicleSpeed m28 : 28|12@1+ (0.08,-40) [0|0] "" Vector__XXX
 SG_ RCM_a029_eventVehicleSpeed m29 : 28|12@1+ (0.08,-40) [0|0] "" Vector__XXX
 SG_ RCM_a030_eventVehicleSpeed m30 : 28|12@1+ (0.08,-40) [0|0] "" Vector__XXX
 SG_ RCM_a031_eventVehicleSpeed m31 : 28|12@1+ (0.08,-40) [0|0] "" Vector__XXX
 SG_ RCM_a032_eventVehicleSpeed m32 : 28|12@1+ (0.08,-40) [0|0] "" Vector__XXX
 SG_ RCM_a033_eventVehicleSpeed m33 : 28|12@1+ (0.08,-40) [0|0] "" Vector__XXX
 SG_ RCM_a034_eventVehicleSpeed m34 : 28|12@1+ (0.08,-40) [0|0] "" Vector__XXX
 SG_ RCM_a035_eventVehicleSpeed m35 : 28|12@1+ (0.08,-40) [0|0] "" Vector__XXX
 SG_ RCM_a036_eventVehicleSpeed m36 : 28|12@1+ (0.08,-40) [0|0] "" Vector__XXX
 SG_ RCM_a037_eventVehicleSpeed m37 : 28|12@1+ (0.08,-40) [0|0] "" Vector__XXX
 SG_ RCM_a038_eventVehicleSpeed m38 : 28|12@1+ (0.08,-40) [0|0] "" Vector__XXX
 SG_ RCM_a039_eventVehicleSpeed m39 : 28|12@1+ (0.08,-40) [0|0] "" Vector__XXX
 SG_ RCM_a040_eventVehicleSpeed m40 : 28|12@1+ (0.08,-40) [0|0] "" Vector__XXX
 SG_ RCM_a041_eventVehicleSpeed m41 : 28|12@1+ (0.08,-40) [0|0] "" Vector__XXX
 SG_ RCM_a042_eventVehicleSpeed m42 : 28|12@1+ (0.08,-40) [0|0] "" Vector__XXX
 SG_ RCM_a043_eventVehicleSpeed m43 : 28|12@1+ (0.08,-40) [0|0] "" Vector__XXX
 SG_ RCM_a044_eventVehicleSpeed m44 : 28|12@1+ (0.08,-40) [0|0] "" Vector__XXX
 SG_ RCM_a045_eventVehicleSpeed m45 : 28|12@1+ (0.08,-40) [0|0] "" Vector__XXX
 SG_ RCM_a046_eventVehicleSpeed m46 : 28|12@1+ (0.08,-40) [0|0] "" Vector__XXX
 SG_ RCM_a047_eventVehicleSpeed m47 : 28|12@1+ (0.08,-40) [0|0] "" Vector__XXX
 SG_ RCM_a048_eventVehicleSpeed m48 : 28|12@1+ (0.08,-40) [0|0] "" Vector__XXX
 SG_ RCM_a049_eventVehicleSpeed m49 : 28|12@1+ (0.08,-40) [0|0] "" Vector__XXX
 SG_ RCM_a050_eventVehicleSpeed m50 : 28|12@1+ (0.08,-40) [0|0] "" Vector__XXX
 SG_ RCM_a051_eventVehicleSpeed m51 : 28|12@1+ (0.08,-40) [0|0] "" Vector__XXX
 SG_ RCM_a052_eventVehicleSpeed m52 : 28|12@1+ (0.08,-40) [0|0] "" Vector__XXX
 SG_ RCM_a053_eventVehicleSpeed m53 : 28|12@1+ (0.08,-40) [0|0] "" Vector__XXX
 SG_ RCM_a054_eventVehicleSpeed m54 : 28|12@1+ (0.08,-40) [0|0] "" Vector__XXX
 SG_ RCM_a055_eventVehicleSpeed m55 : 28|12@1+ (0.08,-40) [0|0] "" Vector__XXX
 SG_ RCM_a056_eventVehicleSpeed m56 : 28|12@1+ (0.08,-40) [0|0] "" Vector__XXX
 SG_ RCM_a057_eventVehicleSpeed m57 : 28|12@1+ (0.08,-40) [0|0] "" Vector__XXX
 SG_ RCM_a058_eventVehicleSpeed m58 : 28|12@1+ (0.08,-40) [0|0] "" Vector__XXX
 SG_ RCM_a059_eventVehicleSpeed m59 : 28|12@1+ (0.08,-40) [0|0] "" Vector__XXX
 SG_ RCM_a060_eventVehicleSpeed m60 : 28|12@1+ (0.08,-40) [0|0] "" Vector__XXX
 SG_ RCM_a061_eventVehicleSpeed m61 : 28|12@1+ (0.08,-40) [0|0] "" Vector__XXX
 SG_ RCM_a062_eventVehicleSpeed m62 : 28|12@1+ (0.08,-40) [0|0] "" Vector__XXX
 SG_ RCM_a063_eventVehicleSpeed m63 : 28|12@1+ (0.08,-40) [0|0] "" Vector__XXX
 SG_ RCM_a064_eventVehicleSpeed m64 : 28|12@1+ (0.08,-40) [0|0] "" Vector__XXX
 SG_ RCM_a065_eventVehicleSpeed m65 : 28|12@1+ (0.08,-40) [0|0] "" Vector__XXX
 SG_ RCM_a066_eventVehicleSpeed m66 : 28|12@1+ (0.08,-40) [0|0] "" Vector__XXX
 SG_ RCM_a067_eventVehicleSpeed m67 : 28|12@1+ (0.08,-40) [0|0] "" Vector__XXX
 SG_ RCM_a068_eventVehicleSpeed m68 : 28|12@1+ (0.08,-40) [0|0] "" Vector__XXX
 SG_ RCM_a069_eventVehicleSpeed m69 : 28|12@1+ (0.08,-40) [0|0] "" Vector__XXX
 SG_ RCM_a070_eventVehicleSpeed m70 : 28|12@1+ (0.08,-40) [0|0] "" Vector__XXX
 SG_ RCM_a071_eventVehicleSpeed m71 : 28|12@1+ (0.08,-40) [0|0] "" Vector__XXX
 SG_ RCM_a072_eventVehicleSpeed m72 : 28|12@1+ (0.08,-40) [0|0] "" Vector__XXX
 SG_ RCM_a073_eventVehicleSpeed m73 : 28|12@1+ (0.08,-40) [0|0] "" Vector__XXX
 SG_ RCM_a074_eventVehicleSpeed m74 : 28|12@1+ (0.08,-40) [0|0] "" Vector__XXX
 SG_ RCM_a075_eventVehicleSpeed m75 : 28|12@1+ (0.08,-40) [0|0] "" Vector__XXX
 SG_ RCM_a076_eventVehicleSpeed m76 : 28|12@1+ (0.08,-40) [0|0] "" Vector__XXX
 SG_ RCM_a077_eventVehicleSpeed m77 : 28|12@1+ (0.08,-40) [0|0] "" Vector__XXX
 SG_ RCM_a078_eventVehicleSpeed m78 : 28|12@1+ (0.08,-40) [0|0] "" Vector__XXX
 SG_ RCM_a079_eventVehicleSpeed m79 : 28|12@1+ (0.08,-40) [0|0] "" Vector__XXX
 SG_ RCM_a080_eventVehicleSpeed m80 : 28|12@1+ (0.08,-40) [0|0] "" Vector__XXX
 SG_ RCM_a081_eventVehicleSpeed m81 : 28|12@1+ (0.08,-40) [0|0] "" Vector__XXX
 SG_ RCM_a082_eventVehicleSpeed m82 : 28|12@1+ (0.08,-40) [0|0] "" Vector__XXX
 SG_ RCM_a083_eventVehicleSpeed m83 : 28|12@1+ (0.08,-40) [0|0] "" Vector__XXX
 SG_ RCM_a084_eventVehicleSpeed m84 : 28|12@1+ (0.08,-40) [0|0] "" Vector__XXX
 SG_ RCM_a085_eventVehicleSpeed m85 : 28|12@1+ (0.08,-40) [0|0] "" Vector__XXX
 SG_ RCM_a086_eventVehicleSpeed m86 : 28|12@1+ (0.08,-40) [0|0] "" Vector__XXX
 SG_ RCM_a087_eventVehicleSpeed m87 : 28|12@1+ (0.08,-40) [0|0] "" Vector__XXX
 SG_ RCM_a088_eventVehicleSpeed m88 : 28|12@1+ (0.08,-40) [0|0] "" Vector__XXX
 SG_ RCM_a089_eventVehicleSpeed m89 : 28|12@1+ (0.08,-40) [0|0] "" Vector__XXX
 SG_ RCM_a090_eventVehicleSpeed m90 : 28|12@1+ (0.08,-40) [0|0] "" Vector__XXX
 SG_ RCM_a091_eventVehicleSpeed m91 : 28|12@1+ (0.08,-40) [0|0] "" Vector__XXX
 SG_ RCM_a092_eventVehicleSpeed m92 : 28|12@1+ (0.08,-40) [0|0] "" Vector__XXX
 SG_ RCM_a093_eventVehicleSpeed m93 : 28|12@1+ (0.08,-40) [0|0] "" Vector__XXX
 SG_ RCM_a094_eventVehicleSpeed m94 : 28|12@1+ (0.08,-40) [0|0] "" Vector__XXX
 SG_ RCM_a095_eventVehicleSpeed m95 : 28|12@1+ (0.08,-40) [0|0] "" Vector__XXX
 SG_ RCM_a096_eventVehicleSpeed m96 : 28|12@1+ (0.08,-40) [0|0] "" Vector__XXX
 SG_ RCM_a097_eventVehicleSpeed m97 : 28|12@1+ (0.08,-40) [0|0] "" Vector__XXX
 SG_ RCM_a098_eventVehicleSpeed m98 : 28|12@1+ (0.08,-40) [0|0] "" Vector__XXX
 SG_ RCM_a099_eventVehicleSpeed m99 : 28|12@1+ (0.08,-40) [0|0] "" Vector__XXX
 SG_ RCM_a100_eventVehicleSpeed m100 : 28|12@1+ (0.08,-40) [0|0] "" Vector__XXX
 SG_ RCM_a101_eventVehicleSpeed m101 : 28|12@1+ (0.08,-40) [0|0] "" Vector__XXX
 SG_ RCM_a102_eventVehicleSpeed m102 : 28|12@1+ (0.08,-40) [0|0] "" Vector__XXX
 SG_ RCM_a103_eventVehicleSpeed m103 : 28|12@1+ (0.08,-40) [0|0] "" Vector__XXX
 SG_ RCM_a104_eventVehicleSpeed m104 : 28|12@1+ (0.08,-40) [0|0] "" Vector__XXX
 SG_ RCM_a105_eventVehicleSpeed m105 : 28|12@1+ (0.08,-40) [0|0] "" Vector__XXX
 SG_ RCM_a106_eventVehicleSpeed m106 : 28|12@1+ (0.08,-40) [0|0] "" Vector__XXX
 SG_ RCM_a107_eventVehicleSpeed m107 : 28|12@1+ (0.08,-40) [0|0] "" Vector__XXX
 SG_ RCM_a108_eventVehicleSpeed m108 : 28|12@1+ (0.08,-40) [0|0] "" Vector__XXX
 SG_ RCM_a109_eventVehicleSpeed m109 : 28|12@1+ (0.08,-40) [0|0] "" Vector__XXX
 SG_ RCM_a110_eventVehicleSpeed m110 : 28|12@1+ (0.08,-40) [0|0] "" Vector__XXX
 SG_ RCM_a111_eventVehicleSpeed m111 : 28|12@1+ (0.08,-40) [0|0] "" Vector__XXX
 SG_ RCM_a112_eventVehicleSpeed m112 : 28|12@1+ (0.08,-40) [0|0] "" Vector__XXX
 SG_ RCM_a113_eventVehicleSpeed m113 : 28|12@1+ (0.08,-40) [0|0] "" Vector__XXX
 SG_ RCM_a114_eventVehicleSpeed m114 : 28|12@1+ (0.08,-40) [0|0] "" Vector__XXX
 SG_ RCM_a115_eventVehicleSpeed m115 : 28|12@1+ (0.08,-40) [0|0] "" Vector__XXX
 SG_ RCM_a116_eventVehicleSpeed m116 : 28|12@1+ (0.08,-40) [0|0] "" Vector__XXX
 SG_ RCM_a117_eventVehicleSpeed m117 : 28|12@1+ (0.08,-40) [0|0] "" Vector__XXX
 SG_ RCM_a118_eventVehicleSpeed m118 : 28|12@1+ (0.08,-40) [0|0] "" Vector__XXX
 SG_ RCM_a000_eventSteeringAngle m0 : 45|14@0+ (0.1,-819.2) [0|0] "" Vector__XXX
 SG_ RCM_a001_eventSteeringAngle m1 : 45|14@0+ (0.1,-819.2) [0|0] "" Vector__XXX
 SG_ RCM_a002_eventSteeringAngle m2 : 45|14@0+ (0.1,-819.2) [0|0] "" Vector__XXX
 SG_ RCM_a003_eventSteeringAngle m3 : 45|14@0+ (0.1,-819.2) [0|0] "" Vector__XXX
 SG_ RCM_a004_eventSteeringAngle m4 : 45|14@0+ (0.1,-819.2) [0|0] "" Vector__XXX
 SG_ RCM_a005_eventSteeringAngle m5 : 45|14@0+ (0.1,-819.2) [0|0] "" Vector__XXX
 SG_ RCM_a006_eventSteeringAngle m6 : 45|14@0+ (0.1,-819.2) [0|0] "" Vector__XXX
 SG_ RCM_a007_eventSteeringAngle m7 : 45|14@0+ (0.1,-819.2) [0|0] "" Vector__XXX
 SG_ RCM_a008_eventSteeringAngle m8 : 45|14@0+ (0.1,-819.2) [0|0] "" Vector__XXX
 SG_ RCM_a009_eventSteeringAngle m9 : 45|14@0+ (0.1,-819.2) [0|0] "" Vector__XXX
 SG_ RCM_a010_eventSteeringAngle m10 : 45|14@0+ (0.1,-819.2) [0|0] "" Vector__XXX
 SG_ RCM_a011_eventSteeringAngle m11 : 45|14@0+ (0.1,-819.2) [0|0] "" Vector__XXX
 SG_ RCM_a012_eventSteeringAngle m12 : 45|14@0+ (0.1,-819.2) [0|0] "" Vector__XXX
 SG_ RCM_a013_eventSteeringAngle m13 : 45|14@0+ (0.1,-819.2) [0|0] "" Vector__XXX
 SG_ RCM_a014_eventSteeringAngle m14 : 45|14@0+ (0.1,-819.2) [0|0] "" Vector__XXX
 SG_ RCM_a015_eventSteeringAngle m15 : 45|14@0+ (0.1,-819.2) [0|0] "" Vector__XXX
 SG_ RCM_a016_eventSteeringAngle m16 : 45|14@0+ (0.1,-819.2) [0|0] "" Vector__XXX
 SG_ RCM_a017_eventSteeringAngle m17 : 45|14@0+ (0.1,-819.2) [0|0] "" Vector__XXX
 SG_ RCM_a018_eventSteeringAngle m18 : 45|14@0+ (0.1,-819.2) [0|0] "" Vector__XXX
 SG_ RCM_a019_eventSteeringAngle m19 : 45|14@0+ (0.1,-819.2) [0|0] "" Vector__XXX
 SG_ RCM_a020_eventSteeringAngle m20 : 45|14@0+ (0.1,-819.2) [0|0] "" Vector__XXX
 SG_ RCM_a021_eventSteeringAngle m21 : 45|14@0+ (0.1,-819.2) [0|0] "" Vector__XXX
 SG_ RCM_a022_eventSteeringAngle m22 : 45|14@0+ (0.1,-819.2) [0|0] "" Vector__XXX
 SG_ RCM_a023_eventSteeringAngle m23 : 45|14@0+ (0.1,-819.2) [0|0] "" Vector__XXX
 SG_ RCM_a024_eventSteeringAngle m24 : 45|14@0+ (0.1,-819.2) [0|0] "" Vector__XXX
 SG_ RCM_a025_eventSteeringAngle m25 : 45|14@0+ (0.1,-819.2) [0|0] "" Vector__XXX
 SG_ RCM_a026_eventSteeringAngle m26 : 45|14@0+ (0.1,-819.2) [0|0] "" Vector__XXX
 SG_ RCM_a027_eventSteeringAngle m27 : 45|14@0+ (0.1,-819.2) [0|0] "" Vector__XXX
 SG_ RCM_a028_eventSteeringAngle m28 : 45|14@0+ (0.1,-819.2) [0|0] "" Vector__XXX
 SG_ RCM_a029_eventSteeringAngle m29 : 45|14@0+ (0.1,-819.2) [0|0] "" Vector__XXX
 SG_ RCM_a030_eventSteeringAngle m30 : 45|14@0+ (0.1,-819.2) [0|0] "" Vector__XXX
 SG_ RCM_a031_eventSteeringAngle m31 : 45|14@0+ (0.1,-819.2) [0|0] "" Vector__XXX
 SG_ RCM_a032_eventSteeringAngle m32 : 45|14@0+ (0.1,-819.2) [0|0] "" Vector__XXX
 SG_ RCM_a033_eventSteeringAngle m33 : 45|14@0+ (0.1,-819.2) [0|0] "" Vector__XXX
 SG_ RCM_a034_eventSteeringAngle m34 : 45|14@0+ (0.1,-819.2) [0|0] "" Vector__XXX
 SG_ RCM_a035_eventSteeringAngle m35 : 45|14@0+ (0.1,-819.2) [0|0] "" Vector__XXX
 SG_ RCM_a036_eventSteeringAngle m36 : 45|14@0+ (0.1,-819.2) [0|0] "" Vector__XXX
 SG_ RCM_a037_eventSteeringAngle m37 : 45|14@0+ (0.1,-819.2) [0|0] "" Vector__XXX
 SG_ RCM_a038_eventSteeringAngle m38 : 45|14@0+ (0.1,-819.2) [0|0] "" Vector__XXX
 SG_ RCM_a039_eventSteeringAngle m39 : 45|14@0+ (0.1,-819.2) [0|0] "" Vector__XXX
 SG_ RCM_a040_eventSteeringAngle m40 : 45|14@0+ (0.1,-819.2) [0|0] "" Vector__XXX
 SG_ RCM_a041_eventSteeringAngle m41 : 45|14@0+ (0.1,-819.2) [0|0] "" Vector__XXX
 SG_ RCM_a042_eventSteeringAngle m42 : 45|14@0+ (0.1,-819.2) [0|0] "" Vector__XXX
 SG_ RCM_a043_eventSteeringAngle m43 : 45|14@0+ (0.1,-819.2) [0|0] "" Vector__XXX
 SG_ RCM_a044_eventSteeringAngle m44 : 45|14@0+ (0.1,-819.2) [0|0] "" Vector__XXX
 SG_ RCM_a045_eventSteeringAngle m45 : 45|14@0+ (0.1,-819.2) [0|0] "" Vector__XXX
 SG_ RCM_a046_eventSteeringAngle m46 : 45|14@0+ (0.1,-819.2) [0|0] "" Vector__XXX
 SG_ RCM_a047_eventSteeringAngle m47 : 45|14@0+ (0.1,-819.2) [0|0] "" Vector__XXX
 SG_ RCM_a048_eventSteeringAngle m48 : 45|14@0+ (0.1,-819.2) [0|0] "" Vector__XXX
 SG_ RCM_a049_eventSteeringAngle m49 : 45|14@0+ (0.1,-819.2) [0|0] "" Vector__XXX
 SG_ RCM_a050_eventSteeringAngle m50 : 45|14@0+ (0.1,-819.2) [0|0] "" Vector__XXX
 SG_ RCM_a051_eventSteeringAngle m51 : 45|14@0+ (0.1,-819.2) [0|0] "" Vector__XXX
 SG_ RCM_a052_eventSteeringAngle m52 : 45|14@0+ (0.1,-819.2) [0|0] "" Vector__XXX
 SG_ RCM_a053_eventSteeringAngle m53 : 45|14@0+ (0.1,-819.2) [0|0] "" Vector__XXX
 SG_ RCM_a054_eventSteeringAngle m54 : 45|14@0+ (0.1,-819.2) [0|0] "" Vector__XXX
 SG_ RCM_a055_eventSteeringAngle m55 : 45|14@0+ (0.1,-819.2) [0|0] "" Vector__XXX
 SG_ RCM_a056_eventSteeringAngle m56 : 45|14@0+ (0.1,-819.2) [0|0] "" Vector__XXX
 SG_ RCM_a057_eventSteeringAngle m57 : 45|14@0+ (0.1,-819.2) [0|0] "" Vector__XXX
 SG_ RCM_a058_eventSteeringAngle m58 : 45|14@0+ (0.1,-819.2) [0|0] "" Vector__XXX
 SG_ RCM_a059_eventSteeringAngle m59 : 45|14@0+ (0.1,-819.2) [0|0] "" Vector__XXX
 SG_ RCM_a060_eventSteeringAngle m60 : 45|14@0+ (0.1,-819.2) [0|0] "" Vector__XXX
 SG_ RCM_a061_eventSteeringAngle m61 : 45|14@0+ (0.1,-819.2) [0|0] "" Vector__XXX
 SG_ RCM_a062_eventSteeringAngle m62 : 45|14@0+ (0.1,-819.2) [0|0] "" Vector__XXX
 SG_ RCM_a063_eventSteeringAngle m63 : 45|14@0+ (0.1,-819.2) [0|0] "" Vector__XXX
 SG_ RCM_a064_eventSteeringAngle m64 : 45|14@0+ (0.1,-819.2) [0|0] "" Vector__XXX
 SG_ RCM_a065_eventSteeringAngle m65 : 45|14@0+ (0.1,-819.2) [0|0] "" Vector__XXX
 SG_ RCM_a066_eventSteeringAngle m66 : 45|14@0+ (0.1,-819.2) [0|0] "" Vector__XXX
 SG_ RCM_a067_eventSteeringAngle m67 : 45|14@0+ (0.1,-819.2) [0|0] "" Vector__XXX
 SG_ RCM_a068_eventSteeringAngle m68 : 45|14@0+ (0.1,-819.2) [0|0] "" Vector__XXX
 SG_ RCM_a069_eventSteeringAngle m69 : 45|14@0+ (0.1,-819.2) [0|0] "" Vector__XXX
 SG_ RCM_a070_eventSteeringAngle m70 : 45|14@0+ (0.1,-819.2) [0|0] "" Vector__XXX
 SG_ RCM_a071_eventSteeringAngle m71 : 45|14@0+ (0.1,-819.2) [0|0] "" Vector__XXX
 SG_ RCM_a072_eventSteeringAngle m72 : 45|14@0+ (0.1,-819.2) [0|0] "" Vector__XXX
 SG_ RCM_a073_eventSteeringAngle m73 : 45|14@0+ (0.1,-819.2) [0|0] "" Vector__XXX
 SG_ RCM_a074_eventSteeringAngle m74 : 45|14@0+ (0.1,-819.2) [0|0] "" Vector__XXX
 SG_ RCM_a075_eventSteeringAngle m75 : 45|14@0+ (0.1,-819.2) [0|0] "" Vector__XXX
 SG_ RCM_a076_eventSteeringAngle m76 : 45|14@0+ (0.1,-819.2) [0|0] "" Vector__XXX
 SG_ RCM_a077_eventSteeringAngle m77 : 45|14@0+ (0.1,-819.2) [0|0] "" Vector__XXX
 SG_ RCM_a078_eventSteeringAngle m78 : 45|14@0+ (0.1,-819.2) [0|0] "" Vector__XXX
 SG_ RCM_a079_eventSteeringAngle m79 : 45|14@0+ (0.1,-819.2) [0|0] "" Vector__XXX
 SG_ RCM_a080_eventSteeringAngle m80 : 45|14@0+ (0.1,-819.2) [0|0] "" Vector__XXX
 SG_ RCM_a081_eventSteeringAngle m81 : 45|14@0+ (0.1,-819.2) [0|0] "" Vector__XXX
 SG_ RCM_a082_eventSteeringAngle m82 : 45|14@0+ (0.1,-819.2) [0|0] "" Vector__XXX
 SG_ RCM_a083_eventSteeringAngle m83 : 45|14@0+ (0.1,-819.2) [0|0] "" Vector__XXX
 SG_ RCM_a084_eventSteeringAngle m84 : 45|14@0+ (0.1,-819.2) [0|0] "" Vector__XXX
 SG_ RCM_a085_eventSteeringAngle m85 : 45|14@0+ (0.1,-819.2) [0|0] "" Vector__XXX
 SG_ RCM_a086_eventSteeringAngle m86 : 45|14@0+ (0.1,-819.2) [0|0] "" Vector__XXX
 SG_ RCM_a087_eventSteeringAngle m87 : 45|14@0+ (0.1,-819.2) [0|0] "" Vector__XXX
 SG_ RCM_a088_eventSteeringAngle m88 : 45|14@0+ (0.1,-819.2) [0|0] "" Vector__XXX
 SG_ RCM_a089_eventSteeringAngle m89 : 45|14@0+ (0.1,-819.2) [0|0] "" Vector__XXX
 SG_ RCM_a090_eventSteeringAngle m90 : 45|14@0+ (0.1,-819.2) [0|0] "" Vector__XXX
 SG_ RCM_a091_eventSteeringAngle m91 : 45|14@0+ (0.1,-819.2) [0|0] "" Vector__XXX
 SG_ RCM_a092_eventSteeringAngle m92 : 45|14@0+ (0.1,-819.2) [0|0] "" Vector__XXX
 SG_ RCM_a093_eventSteeringAngle m93 : 45|14@0+ (0.1,-819.2) [0|0] "" Vector__XXX
 SG_ RCM_a094_eventSteeringAngle m94 : 45|14@0+ (0.1,-819.2) [0|0] "" Vector__XXX
 SG_ RCM_a095_eventSteeringAngle m95 : 45|14@0+ (0.1,-819.2) [0|0] "" Vector__XXX
 SG_ RCM_a096_eventSteeringAngle m96 : 45|14@0+ (0.1,-819.2) [0|0] "" Vector__XXX
 SG_ RCM_a097_eventSteeringAngle m97 : 45|14@0+ (0.1,-819.2) [0|0] "" Vector__XXX
 SG_ RCM_a098_eventSteeringAngle m98 : 45|14@0+ (0.1,-819.2) [0|0] "" Vector__XXX
 SG_ RCM_a099_eventSteeringAngle m99 : 45|14@0+ (0.1,-819.2) [0|0] "" Vector__XXX
 SG_ RCM_a100_eventSteeringAngle m100 : 45|14@0+ (0.1,-819.2) [0|0] "" Vector__XXX
 SG_ RCM_a101_eventSteeringAngle m101 : 45|14@0+ (0.1,-819.2) [0|0] "" Vector__XXX
 SG_ RCM_a102_eventSteeringAngle m102 : 45|14@0+ (0.1,-819.2) [0|0] "" Vector__XXX
 SG_ RCM_a103_eventSteeringAngle m103 : 45|14@0+ (0.1,-819.2) [0|0] "" Vector__XXX
 SG_ RCM_a104_eventSteeringAngle m104 : 45|14@0+ (0.1,-819.2) [0|0] "" Vector__XXX
 SG_ RCM_a105_eventSteeringAngle m105 : 45|14@0+ (0.1,-819.2) [0|0] "" Vector__XXX
 SG_ RCM_a106_eventSteeringAngle m106 : 45|14@0+ (0.1,-819.2) [0|0] "" Vector__XXX
 SG_ RCM_a107_eventSteeringAngle m107 : 45|14@0+ (0.1,-819.2) [0|0] "" Vector__XXX
 SG_ RCM_a108_eventSteeringAngle m108 : 45|14@0+ (0.1,-819.2) [0|0] "" Vector__XXX
 SG_ RCM_a109_eventSteeringAngle m109 : 45|14@0+ (0.1,-819.2) [0|0] "" Vector__XXX
 SG_ RCM_a110_eventSteeringAngle m110 : 45|14@0+ (0.1,-819.2) [0|0] "" Vector__XXX
 SG_ RCM_a111_eventSteeringAngle m111 : 45|14@0+ (0.1,-819.2) [0|0] "" Vector__XXX
 SG_ RCM_a112_eventSteeringAngle m112 : 45|14@0+ (0.1,-819.2) [0|0] "" Vector__XXX
 SG_ RCM_a113_eventSteeringAngle m113 : 45|14@0+ (0.1,-819.2) [0|0] "" Vector__XXX
 SG_ RCM_a114_eventSteeringAngle m114 : 45|14@0+ (0.1,-819.2) [0|0] "" Vector__XXX
 SG_ RCM_a115_eventSteeringAngle m115 : 45|14@0+ (0.1,-819.2) [0|0] "" Vector__XXX
 SG_ RCM_a116_eventSteeringAngle m116 : 45|14@0+ (0.1,-819.2) [0|0] "" Vector__XXX
 SG_ RCM_a117_eventSteeringAngle m117 : 45|14@0+ (0.1,-819.2) [0|0] "" Vector__XXX
 SG_ RCM_a118_eventSteeringAngle m118 : 45|14@0+ (0.1,-819.2) [0|0] "" Vector__XXX
 SG_ RCM_a000_eventDriverBrakeApply m0 : 46|2@1+ (1,0) [0|0] "" Vector__XXX
 SG_ RCM_a001_eventDriverBrakeApply m1 : 46|2@1+ (1,0) [0|0] "" Vector__XXX
 SG_ RCM_a002_eventDriverBrakeApply m2 : 46|2@1+ (1,0) [0|0] "" Vector__XXX
 SG_ RCM_a003_eventDriverBrakeApply m3 : 46|2@1+ (1,0) [0|0] "" Vector__XXX
 SG_ RCM_a004_eventDriverBrakeApply m4 : 46|2@1+ (1,0) [0|0] "" Vector__XXX
 SG_ RCM_a005_eventDriverBrakeApply m5 : 46|2@1+ (1,0) [0|0] "" Vector__XXX
 SG_ RCM_a006_eventDriverBrakeApply m6 : 46|2@1+ (1,0) [0|0] "" Vector__XXX
 SG_ RCM_a007_eventDriverBrakeApply m7 : 46|2@1+ (1,0) [0|0] "" Vector__XXX
 SG_ RCM_a008_eventDriverBrakeApply m8 : 46|2@1+ (1,0) [0|0] "" Vector__XXX
 SG_ RCM_a009_eventDriverBrakeApply m9 : 46|2@1+ (1,0) [0|0] "" Vector__XXX
 SG_ RCM_a010_eventDriverBrakeApply m10 : 46|2@1+ (1,0) [0|0] "" Vector__XXX
 SG_ RCM_a011_eventDriverBrakeApply m11 : 46|2@1+ (1,0) [0|0] "" Vector__XXX
 SG_ RCM_a012_eventDriverBrakeApply m12 : 46|2@1+ (1,0) [0|0] "" Vector__XXX
 SG_ RCM_a013_eventDriverBrakeApply m13 : 46|2@1+ (1,0) [0|0] "" Vector__XXX
 SG_ RCM_a014_eventDriverBrakeApply m14 : 46|2@1+ (1,0) [0|0] "" Vector__XXX
 SG_ RCM_a015_eventDriverBrakeApply m15 : 46|2@1+ (1,0) [0|0] "" Vector__XXX
 SG_ RCM_a016_eventDriverBrakeApply m16 : 46|2@1+ (1,0) [0|0] "" Vector__XXX
 SG_ RCM_a017_eventDriverBrakeApply m17 : 46|2@1+ (1,0) [0|0] "" Vector__XXX
 SG_ RCM_a018_eventDriverBrakeApply m18 : 46|2@1+ (1,0) [0|0] "" Vector__XXX
 SG_ RCM_a019_eventDriverBrakeApply m19 : 46|2@1+ (1,0) [0|0] "" Vector__XXX
 SG_ RCM_a020_eventDriverBrakeApply m20 : 46|2@1+ (1,0) [0|0] "" Vector__XXX
 SG_ RCM_a021_eventDriverBrakeApply m21 : 46|2@1+ (1,0) [0|0] "" Vector__XXX
 SG_ RCM_a022_eventDriverBrakeApply m22 : 46|2@1+ (1,0) [0|0] "" Vector__XXX
 SG_ RCM_a023_eventDriverBrakeApply m23 : 46|2@1+ (1,0) [0|0] "" Vector__XXX
 SG_ RCM_a024_eventDriverBrakeApply m24 : 46|2@1+ (1,0) [0|0] "" Vector__XXX
 SG_ RCM_a025_eventDriverBrakeApply m25 : 46|2@1+ (1,0) [0|0] "" Vector__XXX
 SG_ RCM_a026_eventDriverBrakeApply m26 : 46|2@1+ (1,0) [0|0] "" Vector__XXX
 SG_ RCM_a027_eventDriverBrakeApply m27 : 46|2@1+ (1,0) [0|0] "" Vector__XXX
 SG_ RCM_a028_eventDriverBrakeApply m28 : 46|2@1+ (1,0) [0|0] "" Vector__XXX
 SG_ RCM_a029_eventDriverBrakeApply m29 : 46|2@1+ (1,0) [0|0] "" Vector__XXX
 SG_ RCM_a030_eventDriverBrakeApply m30 : 46|2@1+ (1,0) [0|0] "" Vector__XXX
 SG_ RCM_a031_eventDriverBrakeApply m31 : 46|2@1+ (1,0) [0|0] "" Vector__XXX
 SG_ RCM_a032_eventDriverBrakeApply m32 : 46|2@1+ (1,0) [0|0] "" Vector__XXX
 SG_ RCM_a033_eventDriverBrakeApply m33 : 46|2@1+ (1,0) [0|0] "" Vector__XXX
 SG_ RCM_a034_eventDriverBrakeApply m34 : 46|2@1+ (1,0) [0|0] "" Vector__XXX
 SG_ RCM_a035_eventDriverBrakeApply m35 : 46|2@1+ (1,0) [0|0] "" Vector__XXX
 SG_ RCM_a036_eventDriverBrakeApply m36 : 46|2@1+ (1,0) [0|0] "" Vector__XXX
 SG_ RCM_a037_eventDriverBrakeApply m37 : 46|2@1+ (1,0) [0|0] "" Vector__XXX
 SG_ RCM_a038_eventDriverBrakeApply m38 : 46|2@1+ (1,0) [0|0] "" Vector__XXX
 SG_ RCM_a039_eventDriverBrakeApply m39 : 46|2@1+ (1,0) [0|0] "" Vector__XXX
 SG_ RCM_a040_eventDriverBrakeApply m40 : 46|2@1+ (1,0) [0|0] "" Vector__XXX
 SG_ RCM_a041_eventDriverBrakeApply m41 : 46|2@1+ (1,0) [0|0] "" Vector__XXX
 SG_ RCM_a042_eventDriverBrakeApply m42 : 46|2@1+ (1,0) [0|0] "" Vector__XXX
 SG_ RCM_a043_eventDriverBrakeApply m43 : 46|2@1+ (1,0) [0|0] "" Vector__XXX
 SG_ RCM_a044_eventDriverBrakeApply m44 : 46|2@1+ (1,0) [0|0] "" Vector__XXX
 SG_ RCM_a045_eventDriverBrakeApply m45 : 46|2@1+ (1,0) [0|0] "" Vector__XXX
 SG_ RCM_a046_eventDriverBrakeApply m46 : 46|2@1+ (1,0) [0|0] "" Vector__XXX
 SG_ RCM_a047_eventDriverBrakeApply m47 : 46|2@1+ (1,0) [0|0] "" Vector__XXX
 SG_ RCM_a048_eventDriverBrakeApply m48 : 46|2@1+ (1,0) [0|0] "" Vector__XXX
 SG_ RCM_a049_eventDriverBrakeApply m49 : 46|2@1+ (1,0) [0|0] "" Vector__XXX
 SG_ RCM_a050_eventDriverBrakeApply m50 : 46|2@1+ (1,0) [0|0] "" Vector__XXX
 SG_ RCM_a051_eventDriverBrakeApply m51 : 46|2@1+ (1,0) [0|0] "" Vector__XXX
 SG_ RCM_a052_eventDriverBrakeApply m52 : 46|2@1+ (1,0) [0|0] "" Vector__XXX
 SG_ RCM_a053_eventDriverBrakeApply m53 : 46|2@1+ (1,0) [0|0] "" Vector__XXX
 SG_ RCM_a054_eventDriverBrakeApply m54 : 46|2@1+ (1,0) [0|0] "" Vector__XXX
 SG_ RCM_a055_eventDriverBrakeApply m55 : 46|2@1+ (1,0) [0|0] "" Vector__XXX
 SG_ RCM_a056_eventDriverBrakeApply m56 : 46|2@1+ (1,0) [0|0] "" Vector__XXX
 SG_ RCM_a057_eventDriverBrakeApply m57 : 46|2@1+ (1,0) [0|0] "" Vector__XXX
 SG_ RCM_a058_eventDriverBrakeApply m58 : 46|2@1+ (1,0) [0|0] "" Vector__XXX
 SG_ RCM_a059_eventDriverBrakeApply m59 : 46|2@1+ (1,0) [0|0] "" Vector__XXX
 SG_ RCM_a060_eventDriverBrakeApply m60 : 46|2@1+ (1,0) [0|0] "" Vector__XXX
 SG_ RCM_a061_eventDriverBrakeApply m61 : 46|2@1+ (1,0) [0|0] "" Vector__XXX
 SG_ RCM_a062_eventDriverBrakeApply m62 : 46|2@1+ (1,0) [0|0] "" Vector__XXX
 SG_ RCM_a063_eventDriverBrakeApply m63 : 46|2@1+ (1,0) [0|0] "" Vector__XXX
 SG_ RCM_a064_eventDriverBrakeApply m64 : 46|2@1+ (1,0) [0|0] "" Vector__XXX
 SG_ RCM_a065_eventDriverBrakeApply m65 : 46|2@1+ (1,0) [0|0] "" Vector__XXX
 SG_ RCM_a066_eventDriverBrakeApply m66 : 46|2@1+ (1,0) [0|0] "" Vector__XXX
 SG_ RCM_a067_eventDriverBrakeApply m67 : 46|2@1+ (1,0) [0|0] "" Vector__XXX
 SG_ RCM_a068_eventDriverBrakeApply m68 : 46|2@1+ (1,0) [0|0] "" Vector__XXX
 SG_ RCM_a069_eventDriverBrakeApply m69 : 46|2@1+ (1,0) [0|0] "" Vector__XXX
 SG_ RCM_a070_eventDriverBrakeApply m70 : 46|2@1+ (1,0) [0|0] "" Vector__XXX
 SG_ RCM_a071_eventDriverBrakeApply m71 : 46|2@1+ (1,0) [0|0] "" Vector__XXX
 SG_ RCM_a072_eventDriverBrakeApply m72 : 46|2@1+ (1,0) [0|0] "" Vector__XXX
 SG_ RCM_a073_eventDriverBrakeApply m73 : 46|2@1+ (1,0) [0|0] "" Vector__XXX
 SG_ RCM_a074_eventDriverBrakeApply m74 : 46|2@1+ (1,0) [0|0] "" Vector__XXX
 SG_ RCM_a075_eventDriverBrakeApply m75 : 46|2@1+ (1,0) [0|0] "" Vector__XXX
 SG_ RCM_a076_eventDriverBrakeApply m76 : 46|2@1+ (1,0) [0|0] "" Vector__XXX
 SG_ RCM_a077_eventDriverBrakeApply m77 : 46|2@1+ (1,0) [0|0] "" Vector__XXX
 SG_ RCM_a078_eventDriverBrakeApply m78 : 46|2@1+ (1,0) [0|0] "" Vector__XXX
 SG_ RCM_a079_eventDriverBrakeApply m79 : 46|2@1+ (1,0) [0|0] "" Vector__XXX
 SG_ RCM_a080_eventDriverBrakeApply m80 : 46|2@1+ (1,0) [0|0] "" Vector__XXX
 SG_ RCM_a081_eventDriverBrakeApply m81 : 46|2@1+ (1,0) [0|0] "" Vector__XXX
 SG_ RCM_a082_eventDriverBrakeApply m82 : 46|2@1+ (1,0) [0|0] "" Vector__XXX
 SG_ RCM_a083_eventDriverBrakeApply m83 : 46|2@1+ (1,0) [0|0] "" Vector__XXX
 SG_ RCM_a084_eventDriverBrakeApply m84 : 46|2@1+ (1,0) [0|0] "" Vector__XXX
 SG_ RCM_a085_eventDriverBrakeApply m85 : 46|2@1+ (1,0) [0|0] "" Vector__XXX
 SG_ RCM_a086_eventDriverBrakeApply m86 : 46|2@1+ (1,0) [0|0] "" Vector__XXX
 SG_ RCM_a087_eventDriverBrakeApply m87 : 46|2@1+ (1,0) [0|0] "" Vector__XXX
 SG_ RCM_a088_eventDriverBrakeApply m88 : 46|2@1+ (1,0) [0|0] "" Vector__XXX
 SG_ RCM_a089_eventDriverBrakeApply m89 : 46|2@1+ (1,0) [0|0] "" Vector__XXX
 SG_ RCM_a090_eventDriverBrakeApply m90 : 46|2@1+ (1,0) [0|0] "" Vector__XXX
 SG_ RCM_a091_eventDriverBrakeApply m91 : 46|2@1+ (1,0) [0|0] "" Vector__XXX
 SG_ RCM_a092_eventDriverBrakeApply m92 : 46|2@1+ (1,0) [0|0] "" Vector__XXX
 SG_ RCM_a093_eventDriverBrakeApply m93 : 46|2@1+ (1,0) [0|0] "" Vector__XXX
 SG_ RCM_a094_eventDriverBrakeApply m94 : 46|2@1+ (1,0) [0|0] "" Vector__XXX
 SG_ RCM_a095_eventDriverBrakeApply m95 : 46|2@1+ (1,0) [0|0] "" Vector__XXX
 SG_ RCM_a096_eventDriverBrakeApply m96 : 46|2@1+ (1,0) [0|0] "" Vector__XXX
 SG_ RCM_a097_eventDriverBrakeApply m97 : 46|2@1+ (1,0) [0|0] "" Vector__XXX
 SG_ RCM_a098_eventDriverBrakeApply m98 : 46|2@1+ (1,0) [0|0] "" Vector__XXX
 SG_ RCM_a099_eventDriverBrakeApply m99 : 46|2@1+ (1,0) [0|0] "" Vector__XXX
 SG_ RCM_a100_eventDriverBrakeApply m100 : 46|2@1+ (1,0) [0|0] "" Vector__XXX
 SG_ RCM_a101_eventDriverBrakeApply m101 : 46|2@1+ (1,0) [0|0] "" Vector__XXX
 SG_ RCM_a102_eventDriverBrakeApply m102 : 46|2@1+ (1,0) [0|0] "" Vector__XXX
 SG_ RCM_a103_eventDriverBrakeApply m103 : 46|2@1+ (1,0) [0|0] "" Vector__XXX
 SG_ RCM_a104_eventDriverBrakeApply m104 : 46|2@1+ (1,0) [0|0] "" Vector__XXX
 SG_ RCM_a105_eventDriverBrakeApply m105 : 46|2@1+ (1,0) [0|0] "" Vector__XXX
 SG_ RCM_a106_eventDriverBrakeApply m106 : 46|2@1+ (1,0) [0|0] "" Vector__XXX
 SG_ RCM_a107_eventDriverBrakeApply m107 : 46|2@1+ (1,0) [0|0] "" Vector__XXX
 SG_ RCM_a108_eventDriverBrakeApply m108 : 46|2@1+ (1,0) [0|0] "" Vector__XXX
 SG_ RCM_a109_eventDriverBrakeApply m109 : 46|2@1+ (1,0) [0|0] "" Vector__XXX
 SG_ RCM_a110_eventDriverBrakeApply m110 : 46|2@1+ (1,0) [0|0] "" Vector__XXX
 SG_ RCM_a111_eventDriverBrakeApply m111 : 46|2@1+ (1,0) [0|0] "" Vector__XXX
 SG_ RCM_a112_eventDriverBrakeApply m112 : 46|2@1+ (1,0) [0|0] "" Vector__XXX
 SG_ RCM_a113_eventDriverBrakeApply m113 : 46|2@1+ (1,0) [0|0] "" Vector__XXX
 SG_ RCM_a114_eventDriverBrakeApply m114 : 46|2@1+ (1,0) [0|0] "" Vector__XXX
 SG_ RCM_a115_eventDriverBrakeApply m115 : 46|2@1+ (1,0) [0|0] "" Vector__XXX
 SG_ RCM_a116_eventDriverBrakeApply m116 : 46|2@1+ (1,0) [0|0] "" Vector__XXX
 SG_ RCM_a117_eventDriverBrakeApply m117 : 46|2@1+ (1,0) [0|0] "" Vector__XXX
 SG_ RCM_a118_eventDriverBrakeApply m118 : 46|2@1+ (1,0) [0|0] "" Vector__XXX
 SG_ RCM_a000_eventAccelPedalPos m0 : 56|8@1+ (0.4,0) [0|0] "" Vector__XXX
 SG_ RCM_a001_eventAccelPedalPos m1 : 56|8@1+ (0.4,0) [0|0] "" Vector__XXX
 SG_ RCM_a002_eventAccelPedalPos m2 : 56|8@1+ (0.4,0) [0|0] "" Vector__XXX
 SG_ RCM_a003_eventAccelPedalPos m3 : 56|8@1+ (0.4,0) [0|0] "" Vector__XXX
 SG_ RCM_a004_eventAccelPedalPos m4 : 56|8@1+ (0.4,0) [0|0] "" Vector__XXX
 SG_ RCM_a005_eventAccelPedalPos m5 : 56|8@1+ (0.4,0) [0|0] "" Vector__XXX
 SG_ RCM_a006_eventAccelPedalPos m6 : 56|8@1+ (0.4,0) [0|0] "" Vector__XXX
 SG_ RCM_a007_eventAccelPedalPos m7 : 56|8@1+ (0.4,0) [0|0] "" Vector__XXX
 SG_ RCM_a008_eventAccelPedalPos m8 : 56|8@1+ (0.4,0) [0|0] "" Vector__XXX
 SG_ RCM_a009_eventAccelPedalPos m9 : 56|8@1+ (0.4,0) [0|0] "" Vector__XXX
 SG_ RCM_a010_eventAccelPedalPos m10 : 56|8@1+ (0.4,0) [0|0] "" Vector__XXX
 SG_ RCM_a011_eventAccelPedalPos m11 : 56|8@1+ (0.4,0) [0|0] "" Vector__XXX
 SG_ RCM_a012_eventAccelPedalPos m12 : 56|8@1+ (0.4,0) [0|0] "" Vector__XXX
 SG_ RCM_a013_eventAccelPedalPos m13 : 56|8@1+ (0.4,0) [0|0] "" Vector__XXX
 SG_ RCM_a014_eventAccelPedalPos m14 : 56|8@1+ (0.4,0) [0|0] "" Vector__XXX
 SG_ RCM_a015_eventAccelPedalPos m15 : 56|8@1+ (0.4,0) [0|0] "" Vector__XXX
 SG_ RCM_a016_eventAccelPedalPos m16 : 56|8@1+ (0.4,0) [0|0] "" Vector__XXX
 SG_ RCM_a017_eventAccelPedalPos m17 : 56|8@1+ (0.4,0) [0|0] "" Vector__XXX
 SG_ RCM_a018_eventAccelPedalPos m18 : 56|8@1+ (0.4,0) [0|0] "" Vector__XXX
 SG_ RCM_a019_eventAccelPedalPos m19 : 56|8@1+ (0.4,0) [0|0] "" Vector__XXX
 SG_ RCM_a020_eventAccelPedalPos m20 : 56|8@1+ (0.4,0) [0|0] "" Vector__XXX
 SG_ RCM_a021_eventAccelPedalPos m21 : 56|8@1+ (0.4,0) [0|0] "" Vector__XXX
 SG_ RCM_a022_eventAccelPedalPos m22 : 56|8@1+ (0.4,0) [0|0] "" Vector__XXX
 SG_ RCM_a023_eventAccelPedalPos m23 : 56|8@1+ (0.4,0) [0|0] "" Vector__XXX
 SG_ RCM_a024_eventAccelPedalPos m24 : 56|8@1+ (0.4,0) [0|0] "" Vector__XXX
 SG_ RCM_a025_eventAccelPedalPos m25 : 56|8@1+ (0.4,0) [0|0] "" Vector__XXX
 SG_ RCM_a026_eventAccelPedalPos m26 : 56|8@1+ (0.4,0) [0|0] "" Vector__XXX
 SG_ RCM_a027_eventAccelPedalPos m27 : 56|8@1+ (0.4,0) [0|0] "" Vector__XXX
 SG_ RCM_a028_eventAccelPedalPos m28 : 56|8@1+ (0.4,0) [0|0] "" Vector__XXX
 SG_ RCM_a029_eventAccelPedalPos m29 : 56|8@1+ (0.4,0) [0|0] "" Vector__XXX
 SG_ RCM_a030_eventAccelPedalPos m30 : 56|8@1+ (0.4,0) [0|0] "" Vector__XXX
 SG_ RCM_a031_eventAccelPedalPos m31 : 56|8@1+ (0.4,0) [0|0] "" Vector__XXX
 SG_ RCM_a032_eventAccelPedalPos m32 : 56|8@1+ (0.4,0) [0|0] "" Vector__XXX
 SG_ RCM_a033_eventAccelPedalPos m33 : 56|8@1+ (0.4,0) [0|0] "" Vector__XXX
 SG_ RCM_a034_eventAccelPedalPos m34 : 56|8@1+ (0.4,0) [0|0] "" Vector__XXX
 SG_ RCM_a035_eventAccelPedalPos m35 : 56|8@1+ (0.4,0) [0|0] "" Vector__XXX
 SG_ RCM_a036_eventAccelPedalPos m36 : 56|8@1+ (0.4,0) [0|0] "" Vector__XXX
 SG_ RCM_a037_eventAccelPedalPos m37 : 56|8@1+ (0.4,0) [0|0] "" Vector__XXX
 SG_ RCM_a038_eventAccelPedalPos m38 : 56|8@1+ (0.4,0) [0|0] "" Vector__XXX
 SG_ RCM_a039_eventAccelPedalPos m39 : 56|8@1+ (0.4,0) [0|0] "" Vector__XXX
 SG_ RCM_a040_eventAccelPedalPos m40 : 56|8@1+ (0.4,0) [0|0] "" Vector__XXX
 SG_ RCM_a041_eventAccelPedalPos m41 : 56|8@1+ (0.4,0) [0|0] "" Vector__XXX
 SG_ RCM_a042_eventAccelPedalPos m42 : 56|8@1+ (0.4,0) [0|0] "" Vector__XXX
 SG_ RCM_a043_eventAccelPedalPos m43 : 56|8@1+ (0.4,0) [0|0] "" Vector__XXX
 SG_ RCM_a044_eventAccelPedalPos m44 : 56|8@1+ (0.4,0) [0|0] "" Vector__XXX
 SG_ RCM_a045_eventAccelPedalPos m45 : 56|8@1+ (0.4,0) [0|0] "" Vector__XXX
 SG_ RCM_a046_eventAccelPedalPos m46 : 56|8@1+ (0.4,0) [0|0] "" Vector__XXX
 SG_ RCM_a047_eventAccelPedalPos m47 : 56|8@1+ (0.4,0) [0|0] "" Vector__XXX
 SG_ RCM_a048_eventAccelPedalPos m48 : 56|8@1+ (0.4,0) [0|0] "" Vector__XXX
 SG_ RCM_a049_eventAccelPedalPos m49 : 56|8@1+ (0.4,0) [0|0] "" Vector__XXX
 SG_ RCM_a050_eventAccelPedalPos m50 : 56|8@1+ (0.4,0) [0|0] "" Vector__XXX
 SG_ RCM_a051_eventAccelPedalPos m51 : 56|8@1+ (0.4,0) [0|0] "" Vector__XXX
 SG_ RCM_a052_eventAccelPedalPos m52 : 56|8@1+ (0.4,0) [0|0] "" Vector__XXX
 SG_ RCM_a053_eventAccelPedalPos m53 : 56|8@1+ (0.4,0) [0|0] "" Vector__XXX
 SG_ RCM_a054_eventAccelPedalPos m54 : 56|8@1+ (0.4,0) [0|0] "" Vector__XXX
 SG_ RCM_a055_eventAccelPedalPos m55 : 56|8@1+ (0.4,0) [0|0] "" Vector__XXX
 SG_ RCM_a056_eventAccelPedalPos m56 : 56|8@1+ (0.4,0) [0|0] "" Vector__XXX
 SG_ RCM_a057_eventAccelPedalPos m57 : 56|8@1+ (0.4,0) [0|0] "" Vector__XXX
 SG_ RCM_a058_eventAccelPedalPos m58 : 56|8@1+ (0.4,0) [0|0] "" Vector__XXX
 SG_ RCM_a059_eventAccelPedalPos m59 : 56|8@1+ (0.4,0) [0|0] "" Vector__XXX
 SG_ RCM_a060_eventAccelPedalPos m60 : 56|8@1+ (0.4,0) [0|0] "" Vector__XXX
 SG_ RCM_a061_eventAccelPedalPos m61 : 56|8@1+ (0.4,0) [0|0] "" Vector__XXX
 SG_ RCM_a062_eventAccelPedalPos m62 : 56|8@1+ (0.4,0) [0|0] "" Vector__XXX
 SG_ RCM_a063_eventAccelPedalPos m63 : 56|8@1+ (0.4,0) [0|0] "" Vector__XXX
 SG_ RCM_a064_eventAccelPedalPos m64 : 56|8@1+ (0.4,0) [0|0] "" Vector__XXX
 SG_ RCM_a065_eventAccelPedalPos m65 : 56|8@1+ (0.4,0) [0|0] "" Vector__XXX
 SG_ RCM_a066_eventAccelPedalPos m66 : 56|8@1+ (0.4,0) [0|0] "" Vector__XXX
 SG_ RCM_a067_eventAccelPedalPos m67 : 56|8@1+ (0.4,0) [0|0] "" Vector__XXX
 SG_ RCM_a068_eventAccelPedalPos m68 : 56|8@1+ (0.4,0) [0|0] "" Vector__XXX
 SG_ RCM_a069_eventAccelPedalPos m69 : 56|8@1+ (0.4,0) [0|0] "" Vector__XXX
 SG_ RCM_a070_eventAccelPedalPos m70 : 56|8@1+ (0.4,0) [0|0] "" Vector__XXX
 SG_ RCM_a071_eventAccelPedalPos m71 : 56|8@1+ (0.4,0) [0|0] "" Vector__XXX
 SG_ RCM_a072_eventAccelPedalPos m72 : 56|8@1+ (0.4,0) [0|0] "" Vector__XXX
 SG_ RCM_a073_eventAccelPedalPos m73 : 56|8@1+ (0.4,0) [0|0] "" Vector__XXX
 SG_ RCM_a074_eventAccelPedalPos m74 : 56|8@1+ (0.4,0) [0|0] "" Vector__XXX
 SG_ RCM_a075_eventAccelPedalPos m75 : 56|8@1+ (0.4,0) [0|0] "" Vector__XXX
 SG_ RCM_a076_eventAccelPedalPos m76 : 56|8@1+ (0.4,0) [0|0] "" Vector__XXX
 SG_ RCM_a077_eventAccelPedalPos m77 : 56|8@1+ (0.4,0) [0|0] "" Vector__XXX
 SG_ RCM_a078_eventAccelPedalPos m78 : 56|8@1+ (0.4,0) [0|0] "" Vector__XXX
 SG_ RCM_a079_eventAccelPedalPos m79 : 56|8@1+ (0.4,0) [0|0] "" Vector__XXX
 SG_ RCM_a080_eventAccelPedalPos m80 : 56|8@1+ (0.4,0) [0|0] "" Vector__XXX
 SG_ RCM_a081_eventAccelPedalPos m81 : 56|8@1+ (0.4,0) [0|0] "" Vector__XXX
 SG_ RCM_a082_eventAccelPedalPos m82 : 56|8@1+ (0.4,0) [0|0] "" Vector__XXX
 SG_ RCM_a083_eventAccelPedalPos m83 : 56|8@1+ (0.4,0) [0|0] "" Vector__XXX
 SG_ RCM_a084_eventAccelPedalPos m84 : 56|8@1+ (0.4,0) [0|0] "" Vector__XXX
 SG_ RCM_a085_eventAccelPedalPos m85 : 56|8@1+ (0.4,0) [0|0] "" Vector__XXX
 SG_ RCM_a086_eventAccelPedalPos m86 : 56|8@1+ (0.4,0) [0|0] "" Vector__XXX
 SG_ RCM_a087_eventAccelPedalPos m87 : 56|8@1+ (0.4,0) [0|0] "" Vector__XXX
 SG_ RCM_a088_eventAccelPedalPos m88 : 56|8@1+ (0.4,0) [0|0] "" Vector__XXX
 SG_ RCM_a089_eventAccelPedalPos m89 : 56|8@1+ (0.4,0) [0|0] "" Vector__XXX
 SG_ RCM_a090_eventAccelPedalPos m90 : 56|8@1+ (0.4,0) [0|0] "" Vector__XXX
 SG_ RCM_a091_eventAccelPedalPos m91 : 56|8@1+ (0.4,0) [0|0] "" Vector__XXX
 SG_ RCM_a092_eventAccelPedalPos m92 : 56|8@1+ (0.4,0) [0|0] "" Vector__XXX
 SG_ RCM_a093_eventAccelPedalPos m93 : 56|8@1+ (0.4,0) [0|0] "" Vector__XXX
 SG_ RCM_a094_eventAccelPedalPos m94 : 56|8@1+ (0.4,0) [0|0] "" Vector__XXX
 SG_ RCM_a095_eventAccelPedalPos m95 : 56|8@1+ (0.4,0) [0|0] "" Vector__XXX
 SG_ RCM_a096_eventAccelPedalPos m96 : 56|8@1+ (0.4,0) [0|0] "" Vector__XXX
 SG_ RCM_a097_eventAccelPedalPos m97 : 56|8@1+ (0.4,0) [0|0] "" Vector__XXX
 SG_ RCM_a098_eventAccelPedalPos m98 : 56|8@1+ (0.4,0) [0|0] "" Vector__XXX
 SG_ RCM_a099_eventAccelPedalPos m99 : 56|8@1+ (0.4,0) [0|0] "" Vector__XXX
 SG_ RCM_a100_eventAccelPedalPos m100 : 56|8@1+ (0.4,0) [0|0] "" Vector__XXX
 SG_ RCM_a101_eventAccelPedalPos m101 : 56|8@1+ (0.4,0) [0|0] "" Vector__XXX
 SG_ RCM_a102_eventAccelPedalPos m102 : 56|8@1+ (0.4,0) [0|0] "" Vector__XXX
 SG_ RCM_a103_eventAccelPedalPos m103 : 56|8@1+ (0.4,0) [0|0] "" Vector__XXX
 SG_ RCM_a104_eventAccelPedalPos m104 : 56|8@1+ (0.4,0) [0|0] "" Vector__XXX
 SG_ RCM_a105_eventAccelPedalPos m105 : 56|8@1+ (0.4,0) [0|0] "" Vector__XXX
 SG_ RCM_a106_eventAccelPedalPos m106 : 56|8@1+ (0.4,0) [0|0] "" Vector__XXX
 SG_ RCM_a107_eventAccelPedalPos m107 : 56|8@1+ (0.4,0) [0|0] "" Vector__XXX
 SG_ RCM_a108_eventAccelPedalPos m108 : 56|8@1+ (0.4,0) [0|0] "" Vector__XXX
 SG_ RCM_a109_eventAccelPedalPos m109 : 56|8@1+ (0.4,0) [0|0] "" Vector__XXX
 SG_ RCM_a110_eventAccelPedalPos m110 : 56|8@1+ (0.4,0) [0|0] "" Vector__XXX
 SG_ RCM_a111_eventAccelPedalPos m111 : 56|8@1+ (0.4,0) [0|0] "" Vector__XXX
 SG_ RCM_a112_eventAccelPedalPos m112 : 56|8@1+ (0.4,0) [0|0] "" Vector__XXX
 SG_ RCM_a113_eventAccelPedalPos m113 : 56|8@1+ (0.4,0) [0|0] "" Vector__XXX
 SG_ RCM_a114_eventAccelPedalPos m114 : 56|8@1+ (0.4,0) [0|0] "" Vector__XXX
 SG_ RCM_a115_eventAccelPedalPos m115 : 56|8@1+ (0.4,0) [0|0] "" Vector__XXX
 SG_ RCM_a116_eventAccelPedalPos m116 : 56|8@1+ (0.4,0) [0|0] "" Vector__XXX
 SG_ RCM_a117_eventAccelPedalPos m117 : 56|8@1+ (0.4,0) [0|0] "" Vector__XXX
 SG_ RCM_a118_eventAccelPedalPos m118 : 56|8@1+ (0.4,0) [0|0] "" Vector__XXX
